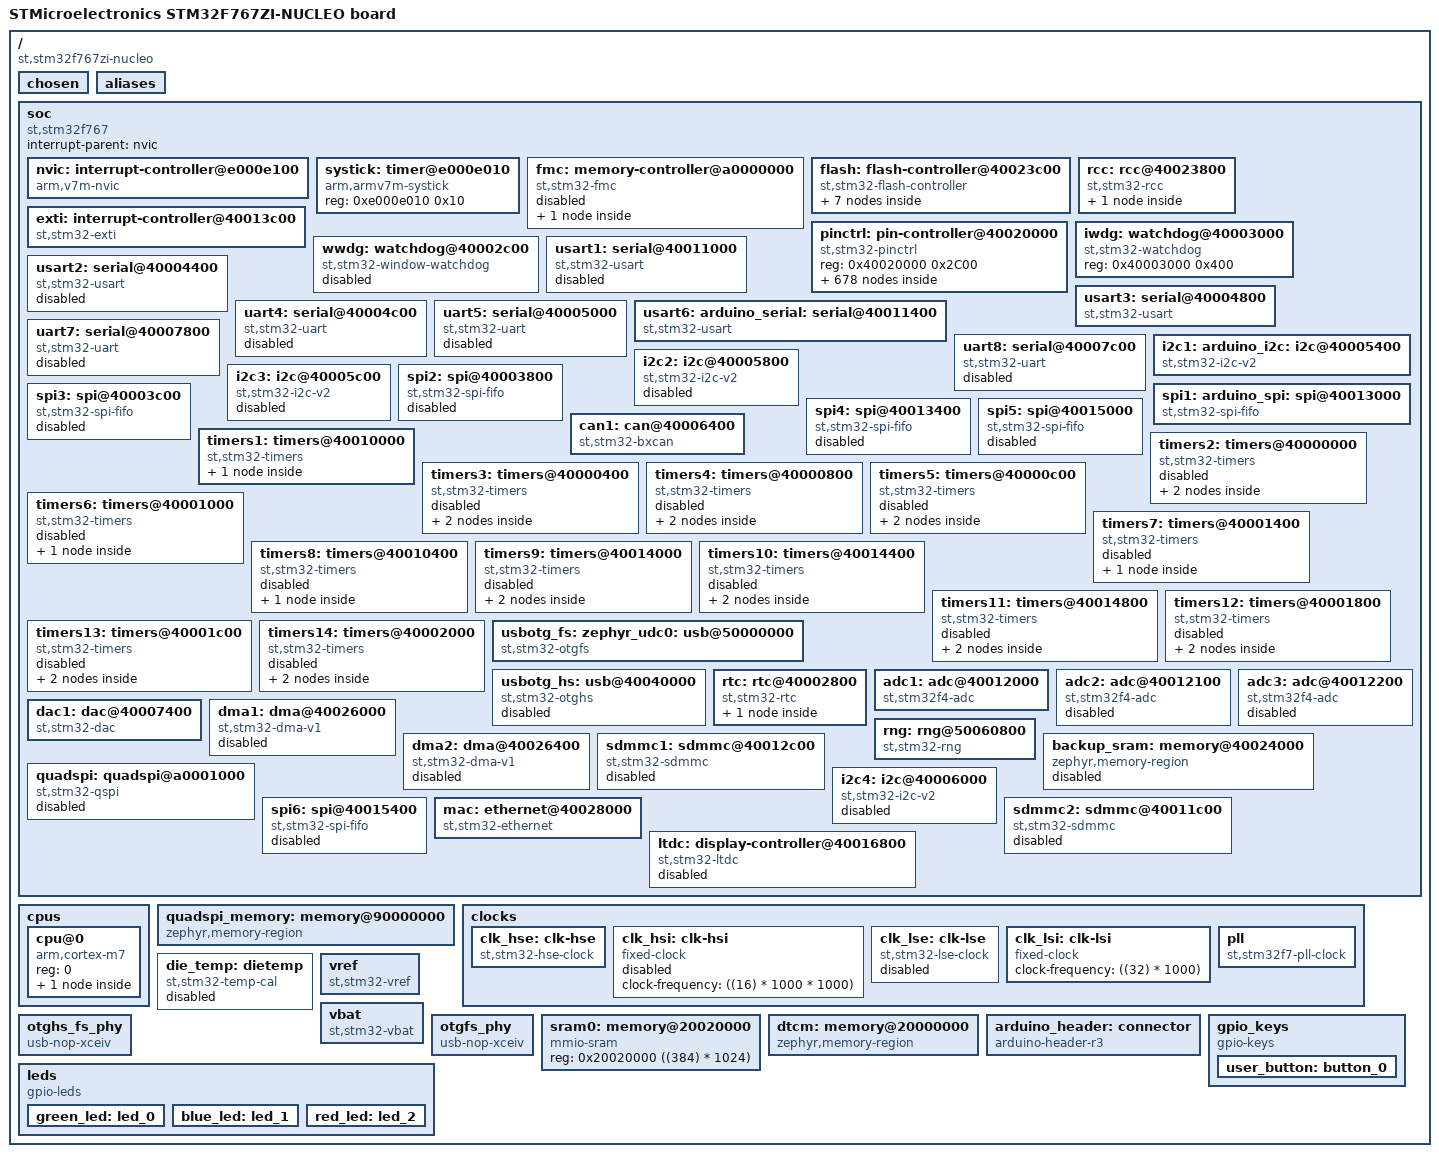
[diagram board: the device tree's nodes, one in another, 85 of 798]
/dts-v1/;
/ {
 #address-cells = <1>;
 #size-cells = <1>;
 chosen { };
 aliases { };
};
/ {
 soc {
  #address-cells = <1>;
  #size-cells = <1>;
  compatible = "simple-bus";
  interrupt-parent = <&nvic>;
  ranges;
  nvic: interrupt-controller@e000e100 {
   #address-cells = <1>;
   compatible = "arm,v7m-nvic";
   reg = <0xe000e100 0xc00>;
   interrupt-controller;
   #interrupt-cells = <2>;
  };
  systick: timer@e000e010 {
   compatible = "arm,armv7m-systick";
   reg = <0xe000e010 0x10>;
  };
 };
};
/ {
 chosen {
  zephyr,entropy = &rng;
  zephyr,flash-controller = &flash;
 };
 cpus {
  #address-cells = <1>;
  #size-cells = <0>;
  cpu@0 {
   device_type = "cpu";
   compatible = "arm,cortex-m7";
   reg = <0>;
   #address-cells = <1>;
   #size-cells = <1>;
   mpu: mpu@e000ed90 {
    compatible = "arm,armv7m-mpu";
    reg = <0xe000ed90 0x40>;
    arm,num-mpu-regions = <8>;
   };
  };
 };
 quadspi_memory: memory@90000000 {
  compatible = "zephyr,memory-region", "mmio-sram";
  reg = <0x90000000 ((256) * 1024 * 1024)>;
  zephyr,memory-region = "QSPI";
  zephyr,memory-attr = <( (((1UL << (5))) << (20)) )>;
 };
 clocks {
  clk_hse: clk-hse {
   #clock-cells = <0>;
   compatible = "st,stm32-hse-clock";
   status = "disabled";
  };
  clk_hsi: clk-hsi {
   #clock-cells = <0>;
   compatible = "fixed-clock";
   clock-frequency = <((16) * 1000 * 1000)>;
   status = "disabled";
  };
  clk_lse: clk-lse {
   #clock-cells = <0>;
   compatible = "st,stm32-lse-clock";
   clock-frequency = <32768>;
   driving-capability = <0>;
   status = "disabled";
  };
  clk_lsi: clk-lsi {
   #clock-cells = <0>;
   compatible = "fixed-clock";
   clock-frequency = <((32) * 1000)>;
   status = "disabled";
  };
  pll: pll {
   #clock-cells = <0>;
   compatible = "st,stm32f7-pll-clock";
   status = "disabled";
  };
 };
 soc {
  fmc: memory-controller@a0000000 {
   compatible = "st,stm32-fmc";
   reg = <0xa0000000 0x400>;
   clocks = <&rcc 0x038 0x00000001>;
   status = "disabled";
   sdram: sdram {
    compatible = "st,stm32-fmc-sdram";
    #address-cells = <1>;
    #size-cells = <0>;
    status = "disabled";
   };
  };
  flash: flash-controller@40023c00 {
   compatible = "st,stm32-flash-controller", "st,stm32f7-flash-controller";
   reg = <0x40023c00 0x400>;
   interrupts = <4 0>;
   #address-cells = <1>;
   #size-cells = <1>;
   flash0: flash@8000000 {
    compatible = "st,stm32-nv-flash", "soc-nv-flash";
    write-block-size = <1>;
    max-erase-time = <4000>;
   };
  };
  rcc: rcc@40023800 {
   compatible = "st,stm32-rcc";
   #clock-cells = <2>;
   reg = <0x40023800 0x400>;
   rctl: reset-controller {
    compatible = "st,stm32-rcc-rctl";
    #reset-cells = <1>;
   };
  };
  exti: interrupt-controller@40013c00 {
   compatible = "st,stm32-exti";
   interrupt-controller;
   #interrupt-cells = <1>;
   #address-cells = <1>;
   reg = <0x40013c00 0x400>;
   num-lines = <16>;
   interrupts = <6 0>, <7 0>, <8 0>, <9 0>,
         <10 0>, <23 0>, <40 0>;
   interrupt-names = "line0", "line1", "line2", "line3",
       "line4", "line5-9", "line10-15";
   line-ranges = <0 1>, <1 1>, <2 1>, <3 1>,
          <4 1>, <5 5>, <10 6>;
  };
  pinctrl: pin-controller@40020000 {
   compatible = "st,stm32-pinctrl";
   #address-cells = <1>;
   #size-cells = <1>;
   reg = <0x40020000 0x2400>;
   gpioa: gpio@40020000 {
    compatible = "st,stm32-gpio";
    gpio-controller;
    #gpio-cells = <2>;
    reg = <0x40020000 0x400>;
    clocks = <&rcc 0x030 0x00000001>;
   };
   gpiob: gpio@40020400 {
    compatible = "st,stm32-gpio";
    gpio-controller;
    #gpio-cells = <2>;
    reg = <0x40020400 0x400>;
    clocks = <&rcc 0x030 0x00000002>;
   };
   gpioc: gpio@40020800 {
    compatible = "st,stm32-gpio";
    gpio-controller;
    #gpio-cells = <2>;
    reg = <0x40020800 0x400>;
    clocks = <&rcc 0x030 0x00000004>;
   };
   gpiod: gpio@40020C00 {
    compatible = "st,stm32-gpio";
    gpio-controller;
    #gpio-cells = <2>;
    reg = <0x40020C00 0x400>;
    clocks = <&rcc 0x030 0x00000008>;
   };
   gpioe: gpio@40021000 {
    compatible = "st,stm32-gpio";
    gpio-controller;
    #gpio-cells = <2>;
    reg = <0x40021000 0x400>;
    clocks = <&rcc 0x030 0x00000010>;
   };
   gpiof: gpio@40021400 {
    compatible = "st,stm32-gpio";
    gpio-controller;
    #gpio-cells = <2>;
    reg = <0x40021400 0x400>;
    clocks = <&rcc 0x030 0x00000020>;
   };
   gpiog: gpio@40021800 {
    compatible = "st,stm32-gpio";
    gpio-controller;
    #gpio-cells = <2>;
    reg = <0x40021800 0x400>;
    clocks = <&rcc 0x030 0x00000040>;
   };
   gpioh: gpio@40021C00 {
    compatible = "st,stm32-gpio";
    gpio-controller;
    #gpio-cells = <2>;
    reg = <0x40021C00 0x400>;
    clocks = <&rcc 0x030 0x00000080>;
   };
   gpioi: gpio@40022000 {
    compatible = "st,stm32-gpio";
    gpio-controller;
    #gpio-cells = <2>;
    reg = <0x40022000 0x400>;
    clocks = <&rcc 0x030 0x00000100>;
   };
  };
  iwdg: watchdog@40003000 {
   compatible = "st,stm32-watchdog";
   reg = <0x40003000 0x400>;
   status = "disabled";
  };
  wwdg: watchdog@40002c00 {
   compatible = "st,stm32-window-watchdog";
   reg = <0x40002C00 0x400>;
   clocks = <&rcc 0x040 0x00000800>;
   interrupts = <0 7>;
   status = "disabled";
  };
  usart1: serial@40011000 {
   compatible = "st,stm32-usart", "st,stm32-uart";
   reg = <0x40011000 0x400>;
   clocks = <&rcc 0x044 0x00000010>;
   resets = <&rctl (((0x24) << 5U) | (4U))>;
   interrupts = <37 0>;
   status = "disabled";
  };
  usart2: serial@40004400 {
   compatible = "st,stm32-usart", "st,stm32-uart";
   reg = <0x40004400 0x400>;
   clocks = <&rcc 0x040 0x00020000>;
   resets = <&rctl (((0x20) << 5U) | (17U))>;
   interrupts = <38 0>;
   status = "disabled";
  };
  usart3: serial@40004800 {
   compatible = "st,stm32-usart", "st,stm32-uart";
   reg = <0x40004800 0x400>;
   clocks = <&rcc 0x040 0x00040000>;
   resets = <&rctl (((0x20) << 5U) | (18U))>;
   interrupts = <39 0>;
   status = "disabled";
  };
  uart4: serial@40004c00 {
   compatible ="st,stm32-uart";
   reg = <0x40004c00 0x400>;
   clocks = <&rcc 0x040 0x00080000>;
   resets = <&rctl (((0x20) << 5U) | (19U))>;
   interrupts = <52 0>;
   status = "disabled";
  };
  uart5: serial@40005000 {
   compatible = "st,stm32-uart";
   reg = <0x40005000 0x400>;
   clocks = <&rcc 0x040 0x00100000>;
   resets = <&rctl (((0x20) << 5U) | (20U))>;
   interrupts = <53 0>;
   status = "disabled";
  };
  usart6: serial@40011400 {
   compatible = "st,stm32-usart", "st,stm32-uart";
   reg = <0x40011400 0x400>;
   clocks = <&rcc 0x044 0x00000020>;
   resets = <&rctl (((0x24) << 5U) | (5U))>;
   interrupts = <71 0>;
   status = "disabled";
  };
  uart7: serial@40007800 {
   compatible = "st,stm32-uart";
   reg = <0x40007800 0x400>;
   clocks = <&rcc 0x040 0x40000000>;
   resets = <&rctl (((0x20) << 5U) | (30U))>;
   interrupts = <82 0>;
   status = "disabled";
  };
  uart8: serial@40007c00 {
   compatible = "st,stm32-uart";
   reg = <0x40007c00 0x400>;
   clocks = <&rcc 0x040 0x80000000>;
   resets = <&rctl (((0x20) << 5U) | (31U))>;
   interrupts = <83 0>;
   status = "disabled";
  };
  i2c1: i2c@40005400 {
   compatible = "st,stm32-i2c-v2";
   clock-frequency = <100000>;
   #address-cells = <1>;
   #size-cells = <0>;
   reg = <0x40005400 0x400>;
   clocks = <&rcc 0x040 0x00200000>;
   interrupts = <31 0>, <32 0>;
   interrupt-names = "event", "error";
   status = "disabled";
  };
  i2c2: i2c@40005800 {
   compatible = "st,stm32-i2c-v2";
   clock-frequency = <100000>;
   #address-cells = <1>;
   #size-cells = <0>;
   reg = <0x40005800 0x400>;
   clocks = <&rcc 0x040 0x00400000>;
   interrupts = <33 0>, <34 0>;
   interrupt-names = "event", "error";
   status = "disabled";
  };
  i2c3: i2c@40005c00 {
   compatible = "st,stm32-i2c-v2";
   clock-frequency = <100000>;
   #address-cells = <1>;
   #size-cells = <0>;
   reg = <0x40005c00 0x400>;
   clocks = <&rcc 0x040 0x00800000>;
   interrupts = <72 0>, <73 0>;
   interrupt-names = "event", "error";
   status = "disabled";
  };
  spi1: spi@40013000 {
   compatible = "st,stm32-spi-fifo", "st,stm32-spi";
   #address-cells = <1>;
   #size-cells = <0>;
   reg = <0x40013000 0x400>;
   clocks = <&rcc 0x044 0x00001000>;
   interrupts = <35 5>;
   status = "disabled";
  };
  spi2: spi@40003800 {
   compatible = "st,stm32-spi-fifo", "st,stm32-spi";
   #address-cells = <1>;
   #size-cells = <0>;
   reg = <0x40003800 0x400>;
   clocks = <&rcc 0x040 0x00004000>;
   interrupts = <36 5>;
   status = "disabled";
  };
  spi3: spi@40003c00 {
   compatible = "st,stm32-spi-fifo", "st,stm32-spi";
   #address-cells = <1>;
   #size-cells = <0>;
   reg = <0x40003c00 0x400>;
   clocks = <&rcc 0x040 0x00008000>;
   interrupts = <51 5>;
   status = "disabled";
  };
  spi4: spi@40013400 {
   compatible = "st,stm32-spi-fifo", "st,stm32-spi";
   #address-cells = <1>;
   #size-cells = <0>;
   reg = <0x40013400 0x400>;
   clocks = <&rcc 0x044 0x00002000>;
   interrupts = <84 5>;
   status = "disabled";
  };
  spi5: spi@40015000 {
   compatible = "st,stm32-spi-fifo", "st,stm32-spi";
   #address-cells = <1>;
   #size-cells = <0>;
   reg = <0x40015000 0x400>;
   clocks = <&rcc 0x044 0x00100000>;
   interrupts = <85 5>;
   status = "disabled";
  };
  can1: can@40006400 {
   compatible = "st,stm32-bxcan";
   reg = <0x40006400 0x400>;
   interrupts = <19 0>, <20 0>, <21 0>, <22 0>;
   interrupt-names = "TX", "RX0", "RX1", "SCE";
   clocks = <&rcc 0x040 0x02000000>;
   status = "disabled";
   sample-point = <875>;
  };
  timers1: timers@40010000 {
   compatible = "st,stm32-timers";
   reg = <0x40010000 0x400>;
   clocks = <&rcc 0x044 0x00000001>;
   resets = <&rctl (((0x24) << 5U) | (0U))>;
   interrupts = <24 0>, <25 0>, <26 0>, <27 0>;
   interrupt-names = "brk", "up", "trgcom", "cc";
   st,prescaler = <0>;
   status = "disabled";
   pwm {
    compatible = "st,stm32-pwm";
    status = "disabled";
    #pwm-cells = <3>;
   };
  };
  timers2: timers@40000000 {
   compatible = "st,stm32-timers";
   reg = <0x40000000 0x400>;
   clocks = <&rcc 0x040 0x00000001>;
   resets = <&rctl (((0x20) << 5U) | (0U))>;
   interrupts = <28 0>;
   interrupt-names = "global";
   st,prescaler = <0>;
   status = "disabled";
   pwm {
    compatible = "st,stm32-pwm";
    status = "disabled";
    #pwm-cells = <3>;
   };
   counter {
    compatible = "st,stm32-counter";
    status = "disabled";
   };
  };
  timers3: timers@40000400 {
   compatible = "st,stm32-timers";
   reg = <0x40000400 0x400>;
   clocks = <&rcc 0x040 0x00000002>;
   resets = <&rctl (((0x20) << 5U) | (1U))>;
   interrupts = <29 0>;
   interrupt-names = "global";
   st,prescaler = <0>;
   status = "disabled";
   pwm {
    compatible = "st,stm32-pwm";
    status = "disabled";
    #pwm-cells = <3>;
   };
   counter {
    compatible = "st,stm32-counter";
    status = "disabled";
   };
  };
  timers4: timers@40000800 {
   compatible = "st,stm32-timers";
   reg = <0x40000800 0x400>;
   clocks = <&rcc 0x040 0x00000004>;
   resets = <&rctl (((0x20) << 5U) | (2U))>;
   interrupts = <30 0>;
   interrupt-names = "global";
   st,prescaler = <0>;
   status = "disabled";
   pwm {
    compatible = "st,stm32-pwm";
    status = "disabled";
    #pwm-cells = <3>;
   };
   counter {
    compatible = "st,stm32-counter";
    status = "disabled";
   };
  };
  timers5: timers@40000c00 {
   compatible = "st,stm32-timers";
   reg = <0x40000c00 0x400>;
   clocks = <&rcc 0x040 0x00000008>;
   resets = <&rctl (((0x20) << 5U) | (3U))>;
   interrupts = <50 0>;
   interrupt-names = "global";
   st,prescaler = <0>;
   status = "disabled";
   pwm {
    compatible = "st,stm32-pwm";
    status = "disabled";
    #pwm-cells = <3>;
   };
   counter {
    compatible = "st,stm32-counter";
    status = "disabled";
   };
  };
  timers6: timers@40001000 {
   compatible = "st,stm32-timers";
   reg = <0x40001000 0x400>;
   clocks = <&rcc 0x040 0x00000010>;
   resets = <&rctl (((0x20) << 5U) | (4U))>;
   interrupts = <54 0>;
   interrupt-names = "global";
   st,prescaler = <0>;
   status = "disabled";
   counter {
    compatible = "st,stm32-counter";
    status = "disabled";
   };
  };
  timers7: timers@40001400 {
   compatible = "st,stm32-timers";
   reg = <0x40001400 0x400>;
   clocks = <&rcc 0x040 0x00000020>;
   resets = <&rctl (((0x20) << 5U) | (5U))>;
   interrupts = <55 0>;
   interrupt-names = "global";
   st,prescaler = <0>;
   status = "disabled";
   counter {
    compatible = "st,stm32-counter";
    status = "disabled";
   };
  };
  timers8: timers@40010400 {
   compatible = "st,stm32-timers";
   reg = <0x40010400 0x400>;
   clocks = <&rcc 0x044 0x00000002>;
   resets = <&rctl (((0x24) << 5U) | (1U))>;
   interrupts = <43 0>, <44 0>, <45 0>, <46 0>;
   interrupt-names = "brk", "up", "trgcom", "cc";
   st,prescaler = <0>;
   status = "disabled";
   pwm {
    compatible = "st,stm32-pwm";
    status = "disabled";
    #pwm-cells = <3>;
   };
  };
  timers9: timers@40014000 {
   compatible = "st,stm32-timers";
   reg = <0x40014000 0x400>;
   clocks = <&rcc 0x044 0x00010000>;
   resets = <&rctl (((0x24) << 5U) | (16U))>;
   interrupts = <24 0>;
   interrupt-names = "global";
   st,prescaler = <0>;
   status = "disabled";
   pwm {
    compatible = "st,stm32-pwm";
    status = "disabled";
    #pwm-cells = <3>;
   };
   counter {
    compatible = "st,stm32-counter";
    status = "disabled";
   };
  };
  timers10: timers@40014400 {
   compatible = "st,stm32-timers";
   reg = <0x40014400 0x400>;
   clocks = <&rcc 0x044 0x00020000>;
   resets = <&rctl (((0x24) << 5U) | (17U))>;
   interrupts = <25 0>;
   interrupt-names = "global";
   st,prescaler = <0>;
   status = "disabled";
   pwm {
    compatible = "st,stm32-pwm";
    status = "disabled";
    #pwm-cells = <3>;
   };
   counter {
    compatible = "st,stm32-counter";
    status = "disabled";
   };
  };
  timers11: timers@40014800 {
   compatible = "st,stm32-timers";
   reg = <0x40014800 0x400>;
   clocks = <&rcc 0x044 0x00040000>;
   resets = <&rctl (((0x24) << 5U) | (18U))>;
   interrupts = <26 0>;
   interrupt-names = "global";
   st,prescaler = <0>;
   status = "disabled";
   pwm {
    compatible = "st,stm32-pwm";
    status = "disabled";
    #pwm-cells = <3>;
   };
   counter {
    compatible = "st,stm32-counter";
    status = "disabled";
   };
  };
  timers12: timers@40001800 {
   compatible = "st,stm32-timers";
   reg = <0x40001800 0x400>;
   clocks = <&rcc 0x040 0x00000040>;
   resets = <&rctl (((0x20) << 5U) | (6U))>;
   interrupts = <43 0>;
   interrupt-names = "global";
   st,prescaler = <0>;
   status = "disabled";
   pwm {
    compatible = "st,stm32-pwm";
    status = "disabled";
    #pwm-cells = <3>;
   };
   counter {
    compatible = "st,stm32-counter";
    status = "disabled";
   };
  };
  timers13: timers@40001c00 {
   compatible = "st,stm32-timers";
   reg = <0x40001c00 0x400>;
   clocks = <&rcc 0x040 0x00000080>;
   resets = <&rctl (((0x20) << 5U) | (7U))>;
   interrupts = <44 0>;
   interrupt-names = "global";
   st,prescaler = <0>;
   status = "disabled";
   pwm {
    compatible = "st,stm32-pwm";
    status = "disabled";
    #pwm-cells = <3>;
   };
   counter {
    compatible = "st,stm32-counter";
    status = "disabled";
   };
  };
  timers14: timers@40002000 {
   compatible = "st,stm32-timers";
   reg = <0x40002000 0x400>;
   clocks = <&rcc 0x040 0x00000100>;
   resets = <&rctl (((0x20) << 5U) | (8U))>;
   interrupts = <45 0>;
   interrupt-names = "global";
   st,prescaler = <0>;
   status = "disabled";
   pwm {
    compatible = "st,stm32-pwm";
    status = "disabled";
    #pwm-cells = <3>;
   };
   counter {
    compatible = "st,stm32-counter";
    status = "disabled";
   };
  };
  usbotg_fs: usb@50000000 {
   compatible = "st,stm32-otgfs";
   reg = <0x50000000 0x40000>;
   interrupts = <67 0>;
   interrupt-names = "otgfs";
   num-bidir-endpoints = <6>;
   ram-size = <1280>;
   maximum-speed = "full-speed";
   phys = <&otgfs_phy>;
   clocks = <&rcc 0x034 0x00000080>,
     <&rcc 0x002 ((((0x90) & 0xFFU) << 0U) | (((27) & 0x1FU) << 8U) | (((1) & 0x7U) << 13U) | (((0) & 0x7U) << 16U))>;
   status = "disabled";
  };
  usbotg_hs: usb@40040000 {
   compatible = "st,stm32-otghs";
   reg = <0x40040000 0x40000>;
   interrupts = <77 0>, <74 0>, <75 0>;
   interrupt-names = "otghs", "ep1_out", "ep1_in";
   num-bidir-endpoints = <9>;
   ram-size = <4096>;
   maximum-speed = "full-speed";
   clocks = <&rcc 0x030 0x20000000>;
   phys = <&otghs_fs_phy>;
   status = "disabled";
  };
  rtc: rtc@40002800 {
   compatible = "st,stm32-rtc";
   reg = <0x40002800 0x300>;
   interrupts = <41 0>;
   clocks = <&rcc 0x040 0x10000000>;
   prescaler = <32768>;
   status = "disabled";
   bbram: backup_regs {
    compatible = "st,stm32-bbram";
    st,backup-regs = <32>;
    status = "disabled";
   };
  };
  adc1: adc@40012000 {
   compatible = "st,stm32f4-adc", "st,stm32-adc";
   reg = <0x40012000 0x50>;
   clocks = <&rcc 0x044 0x00000100>;
   interrupts = <18 0>;
   status = "disabled";
   #io-channel-cells = <1>;
   resolutions = <((((0x04) & ((1UL << (8)) - 1UL)) << 0U) | (((24) & ((1UL << (5)) - 1UL)) << 8U) | (((((1UL << (2)) - 1UL)) & ((1UL << (3)) - 1UL)) << 13U) | (((0x00) & ((1UL << (3)) - 1UL)) << 16U) | (((12) & ((1UL << (13)) - 1UL)) << 19U))
           ((((0x04) & ((1UL << (8)) - 1UL)) << 0U) | (((24) & ((1UL << (5)) - 1UL)) << 8U) | (((((1UL << (2)) - 1UL)) & ((1UL << (3)) - 1UL)) << 13U) | (((0x01) & ((1UL << (3)) - 1UL)) << 16U) | (((10) & ((1UL << (13)) - 1UL)) << 19U))
           ((((0x04) & ((1UL << (8)) - 1UL)) << 0U) | (((24) & ((1UL << (5)) - 1UL)) << 8U) | (((((1UL << (2)) - 1UL)) & ((1UL << (3)) - 1UL)) << 13U) | (((0x02) & ((1UL << (3)) - 1UL)) << 16U) | (((8) & ((1UL << (13)) - 1UL)) << 19U))
           ((((0x04) & ((1UL << (8)) - 1UL)) << 0U) | (((24) & ((1UL << (5)) - 1UL)) << 8U) | (((((1UL << (2)) - 1UL)) & ((1UL << (3)) - 1UL)) << 13U) | (((0x03) & ((1UL << (3)) - 1UL)) << 16U) | (((6) & ((1UL << (13)) - 1UL)) << 19U))>;
   sampling-times = <3 15 28 56 84 112 144 480>;
   st,adc-clock-source = <1>;
   st,adc-sequencer = <1>;
  };
  adc2: adc@40012100 {
   compatible = "st,stm32f4-adc", "st,stm32-adc";
   reg = <0x40012100 0x50>;
   clocks = <&rcc 0x044 0x00000200>;
   interrupts = <18 0>;
   status = "disabled";
   #io-channel-cells = <1>;
   resolutions = <((((0x04) & ((1UL << (8)) - 1UL)) << 0U) | (((24) & ((1UL << (5)) - 1UL)) << 8U) | (((((1UL << (2)) - 1UL)) & ((1UL << (3)) - 1UL)) << 13U) | (((0x00) & ((1UL << (3)) - 1UL)) << 16U) | (((12) & ((1UL << (13)) - 1UL)) << 19U))
           ((((0x04) & ((1UL << (8)) - 1UL)) << 0U) | (((24) & ((1UL << (5)) - 1UL)) << 8U) | (((((1UL << (2)) - 1UL)) & ((1UL << (3)) - 1UL)) << 13U) | (((0x01) & ((1UL << (3)) - 1UL)) << 16U) | (((10) & ((1UL << (13)) - 1UL)) << 19U))
           ((((0x04) & ((1UL << (8)) - 1UL)) << 0U) | (((24) & ((1UL << (5)) - 1UL)) << 8U) | (((((1UL << (2)) - 1UL)) & ((1UL << (3)) - 1UL)) << 13U) | (((0x02) & ((1UL << (3)) - 1UL)) << 16U) | (((8) & ((1UL << (13)) - 1UL)) << 19U))
           ((((0x04) & ((1UL << (8)) - 1UL)) << 0U) | (((24) & ((1UL << (5)) - 1UL)) << 8U) | (((((1UL << (2)) - 1UL)) & ((1UL << (3)) - 1UL)) << 13U) | (((0x03) & ((1UL << (3)) - 1UL)) << 16U) | (((6) & ((1UL << (13)) - 1UL)) << 19U))>;
   sampling-times = <3 15 28 56 84 112 144 480>;
   st,adc-clock-source = <1>;
   st,adc-sequencer = <1>;
  };
  adc3: adc@40012200 {
   compatible = "st,stm32f4-adc", "st,stm32-adc";
   reg = <0x40012200 0x50>;
   clocks = <&rcc 0x044 0x00000400>;
   interrupts = <18 0>;
   status = "disabled";
   #io-channel-cells = <1>;
   resolutions = <((((0x04) & ((1UL << (8)) - 1UL)) << 0U) | (((24) & ((1UL << (5)) - 1UL)) << 8U) | (((((1UL << (2)) - 1UL)) & ((1UL << (3)) - 1UL)) << 13U) | (((0x00) & ((1UL << (3)) - 1UL)) << 16U) | (((12) & ((1UL << (13)) - 1UL)) << 19U))
           ((((0x04) & ((1UL << (8)) - 1UL)) << 0U) | (((24) & ((1UL << (5)) - 1UL)) << 8U) | (((((1UL << (2)) - 1UL)) & ((1UL << (3)) - 1UL)) << 13U) | (((0x01) & ((1UL << (3)) - 1UL)) << 16U) | (((10) & ((1UL << (13)) - 1UL)) << 19U))
           ((((0x04) & ((1UL << (8)) - 1UL)) << 0U) | (((24) & ((1UL << (5)) - 1UL)) << 8U) | (((((1UL << (2)) - 1UL)) & ((1UL << (3)) - 1UL)) << 13U) | (((0x02) & ((1UL << (3)) - 1UL)) << 16U) | (((8) & ((1UL << (13)) - 1UL)) << 19U))
           ((((0x04) & ((1UL << (8)) - 1UL)) << 0U) | (((24) & ((1UL << (5)) - 1UL)) << 8U) | (((((1UL << (2)) - 1UL)) & ((1UL << (3)) - 1UL)) << 13U) | (((0x03) & ((1UL << (3)) - 1UL)) << 16U) | (((6) & ((1UL << (13)) - 1UL)) << 19U))>;
   sampling-times = <3 15 28 56 84 112 144 480>;
   st,adc-clock-source = <1>;
   st,adc-sequencer = <1>;
  };
  dac1: dac@40007400 {
   compatible = "st,stm32-dac";
   reg = <0x40007400 0x400>;
   clocks = <&rcc 0x040 0x20000000>;
   status = "disabled";
   #io-channel-cells = <1>;
  };
  dma1: dma@40026000 {
   compatible = "st,stm32-dma-v1";
   #dma-cells = <4>;
   reg = <0x40026000 0x400>;
   interrupts = <11 0 12 0 13 0 14 0 15 0 16 0 17 0 47 0>;
   clocks = <&rcc 0x030 0x200000>;
   status = "disabled";
  };
  dma2: dma@40026400 {
   compatible = "st,stm32-dma-v1";
   #dma-cells = <4>;
   reg = <0x40026400 0x400>;
   interrupts = <56 0 57 0 58 0 59 0 60 0 68 0 69 0 70 0>;
   clocks = <&rcc 0x030 0x400000>;
   st,mem2mem;
   status = "disabled";
  };
  rng: rng@50060800 {
   compatible = "st,stm32-rng";
   reg = <0x50060800 0x400>;
   interrupts = <80 0>;
   clocks = <&rcc 0x034 0x00000040>,
     <&rcc 0x002 ((((0x90) & 0xFFU) << 0U) | (((27) & 0x1FU) << 8U) | (((1) & 0x7U) << 13U) | (((0) & 0x7U) << 16U))>;
   status = "disabled";
  };
  sdmmc1: sdmmc@40012c00 {
   compatible = "st,stm32-sdmmc";
   reg = <0x40012c00 0x400>;
   clocks = <&rcc 0x044 0x00000800>,
     <&rcc 0x002 ((((0x90) & 0xFFU) << 0U) | (((28) & 0x1FU) << 8U) | (((1) & 0x7U) << 13U) | (((0) & 0x7U) << 16U))>;
   resets = <&rctl (((0x24) << 5U) | (11U))>;
   interrupts = <49 0>;
   status = "disabled";
  };
  backup_sram: memory@40024000 {
   compatible = "zephyr,memory-region", "st,stm32-backup-sram";
   reg = <0x40024000 ((4) * 1024)>;
   clocks = <&rcc 0x030 0x00040000>;
   zephyr,memory-region = "BACKUP_SRAM";
   status = "disabled";
  };
  quadspi: quadspi@a0001000 {
   compatible = "st,stm32-qspi";
   #address-cells = <0x1>;
   #size-cells = <0x0>;
   reg = <0xa0001000 0x34>;
   interrupts = <92 0>;
   clocks = <&rcc 0x038 0x2>;
   status = "disabled";
  };
 };
 die_temp: dietemp {
  compatible = "st,stm32-temp-cal";
  ts-cal1-addr = <0x1FF0F44C>;
  ts-cal2-addr = <0x1FF0F44E>;
  ts-cal1-temp = <30>;
  ts-cal2-temp = <110>;
  ts-cal-vrefanalog = <3300>;
  io-channels = <&adc1 18>;
  status = "disabled";
 };
 vref: vref {
  compatible = "st,stm32-vref";
  vrefint-cal-addr = <0x1FFF7A2A>;
  vrefint-cal-mv = <3300>;
  io-channels = <&adc1 17>;
  status = "disabled";
 };
 vbat: vbat {
  compatible = "st,stm32-vbat";
  ratio = <4>;
  io-channels = <&adc1 18>;
  status = "disabled";
 };
 otghs_fs_phy: otghs_fs_phy {
  compatible = "usb-nop-xceiv";
  #phy-cells = <0>;
 };
 otgfs_phy: otgfs_phy {
  compatible = "usb-nop-xceiv";
  #phy-cells = <0>;
 };
};
&nvic {
 arm,num-irq-priority-bits = <4>;
};
/ {
 sram0: memory@20020000 {
  compatible = "mmio-sram";
  reg = <0x20020000 ((384) * 1024)>;
 };
 dtcm: memory@20000000 {
  compatible = "zephyr,memory-region", "arm,dtcm";
  reg = <0x20000000 ((128) * 1024)>;
  zephyr,memory-region = "DTCM";
 };
 soc {
  compatible = "st,stm32f765", "st,stm32f7", "simple-bus";
  pinctrl: pin-controller@40020000 {
   reg = <0x40020000 0x2C00>;
   gpioj: gpio@40022400 {
    compatible = "st,stm32-gpio";
    gpio-controller;
    #gpio-cells = <2>;
    reg = <0x40022400 0x400>;
    clocks = <&rcc 0x030 0x00000200>;
   };
   gpiok: gpio@40022800 {
    compatible = "st,stm32-gpio";
    gpio-controller;
    #gpio-cells = <2>;
    reg = <0x40022800 0x400>;
    clocks = <&rcc 0x030 0x00000400>;
   };
  };
  i2c4: i2c@40006000 {
   compatible = "st,stm32-i2c-v2";
   clock-frequency = <100000>;
   #address-cells = <1>;
   #size-cells = <0>;
   reg = <0x40006000 0x400>;
   clocks = <&rcc 0x040 0x01000000>;
   interrupts = <95 0>, <96 0>;
   interrupt-names = "event", "error";
   status = "disabled";
  };
  spi6: spi@40015400 {
   compatible = "st,stm32-spi-fifo", "st,stm32-spi";
   #address-cells = <1>;
   #size-cells = <0>;
   reg = <0x40015400 0x400>;
   clocks = <&rcc 0x044 0x00200000>;
   interrupts = <86 5>;
   status = "disabled";
  };
  mac: ethernet@40028000 {
   compatible = "st,stm32-ethernet";
   reg = <0x40028000 0x8000>;
   interrupts = <61 0>;
   clock-names = "stmmaceth", "mac-clk-tx",
          "mac-clk-rx", "mac-clk-ptp";
   clocks = <&rcc 0x030 0x02000000>,
     <&rcc 0x030 0x04000000>,
     <&rcc 0x030 0x08000000>,
     <&rcc 0x030 0x10000000>;
   status = "disabled";
  };
  sdmmc2: sdmmc@40011c00 {
   compatible = "st,stm32-sdmmc";
   reg = <0x40011c00 0x400>;
   clocks = <&rcc 0x044 0x00000080>,
     <&rcc 0x002 ((((0x90) & 0xFFU) << 0U) | (((29) & 0x1FU) << 8U) | (((1) & 0x7U) << 13U) | (((0) & 0x7U) << 16U))>;
   resets = <&rctl (((0x24) << 5U) | (7U))>;
   interrupts = <103 0>;
   status = "disabled";
  };
 };
};
/ {
 soc {
  compatible = "st,stm32f767", "st,stm32f7", "simple-bus";
  ltdc: display-controller@40016800 {
   compatible = "st,stm32-ltdc";
   reg = <0x40016800 0x200>;
   interrupts = <88 0>, <89 0>;
   interrupt-names = "ltdc", "ltdc_err";
   clocks = <&rcc 0x044 0x04000000>;
   status = "disabled";
  };
 };
};
/ {
 soc {
  flash-controller@40023c00 {
   flash0: flash@8000000 {
    reg = <0x08000000 ((2048) * 1024)>;
   };
  };
 };
};
/ {
 soc {
  pinctrl: pin-controller@40020000 {
   /omit-if-no-ref/ adc1_in0_pa0: adc1_in0_pa0 {
    pinmux = <((((('A') - 'A') & 0xFU) << 9U) | (((0) & 0xFU) << 5U) | (((0x10) & 0x1FU) << 0U))>;
   };
   /omit-if-no-ref/ adc1_in1_pa1: adc1_in1_pa1 {
    pinmux = <((((('A') - 'A') & 0xFU) << 9U) | (((1) & 0xFU) << 5U) | (((0x10) & 0x1FU) << 0U))>;
   };
   /omit-if-no-ref/ adc1_in2_pa2: adc1_in2_pa2 {
    pinmux = <((((('A') - 'A') & 0xFU) << 9U) | (((2) & 0xFU) << 5U) | (((0x10) & 0x1FU) << 0U))>;
   };
   /omit-if-no-ref/ adc1_in3_pa3: adc1_in3_pa3 {
    pinmux = <((((('A') - 'A') & 0xFU) << 9U) | (((3) & 0xFU) << 5U) | (((0x10) & 0x1FU) << 0U))>;
   };
   /omit-if-no-ref/ adc1_in4_pa4: adc1_in4_pa4 {
    pinmux = <((((('A') - 'A') & 0xFU) << 9U) | (((4) & 0xFU) << 5U) | (((0x10) & 0x1FU) << 0U))>;
   };
   /omit-if-no-ref/ adc1_in5_pa5: adc1_in5_pa5 {
    pinmux = <((((('A') - 'A') & 0xFU) << 9U) | (((5) & 0xFU) << 5U) | (((0x10) & 0x1FU) << 0U))>;
   };
   /omit-if-no-ref/ adc1_in6_pa6: adc1_in6_pa6 {
    pinmux = <((((('A') - 'A') & 0xFU) << 9U) | (((6) & 0xFU) << 5U) | (((0x10) & 0x1FU) << 0U))>;
   };
   /omit-if-no-ref/ adc1_in7_pa7: adc1_in7_pa7 {
    pinmux = <((((('A') - 'A') & 0xFU) << 9U) | (((7) & 0xFU) << 5U) | (((0x10) & 0x1FU) << 0U))>;
   };
   /omit-if-no-ref/ adc1_in8_pb0: adc1_in8_pb0 {
    pinmux = <((((('B') - 'A') & 0xFU) << 9U) | (((0) & 0xFU) << 5U) | (((0x10) & 0x1FU) << 0U))>;
   };
   /omit-if-no-ref/ adc1_in9_pb1: adc1_in9_pb1 {
    pinmux = <((((('B') - 'A') & 0xFU) << 9U) | (((1) & 0xFU) << 5U) | (((0x10) & 0x1FU) << 0U))>;
   };
   /omit-if-no-ref/ adc1_in10_pc0: adc1_in10_pc0 {
    pinmux = <((((('C') - 'A') & 0xFU) << 9U) | (((0) & 0xFU) << 5U) | (((0x10) & 0x1FU) << 0U))>;
   };
   /omit-if-no-ref/ adc1_in11_pc1: adc1_in11_pc1 {
    pinmux = <((((('C') - 'A') & 0xFU) << 9U) | (((1) & 0xFU) << 5U) | (((0x10) & 0x1FU) << 0U))>;
   };
   /omit-if-no-ref/ adc1_in12_pc2: adc1_in12_pc2 {
    pinmux = <((((('C') - 'A') & 0xFU) << 9U) | (((2) & 0xFU) << 5U) | (((0x10) & 0x1FU) << 0U))>;
   };
   /omit-if-no-ref/ adc1_in13_pc3: adc1_in13_pc3 {
    pinmux = <((((('C') - 'A') & 0xFU) << 9U) | (((3) & 0xFU) << 5U) | (((0x10) & 0x1FU) << 0U))>;
   };
   /omit-if-no-ref/ adc1_in14_pc4: adc1_in14_pc4 {
    pinmux = <((((('C') - 'A') & 0xFU) << 9U) | (((4) & 0xFU) << 5U) | (((0x10) & 0x1FU) << 0U))>;
   };
   /omit-if-no-ref/ adc1_in15_pc5: adc1_in15_pc5 {
    pinmux = <((((('C') - 'A') & 0xFU) << 9U) | (((5) & 0xFU) << 5U) | (((0x10) & 0x1FU) << 0U))>;
   };
   /omit-if-no-ref/ adc2_in0_pa0: adc2_in0_pa0 {
    pinmux = <((((('A') - 'A') & 0xFU) << 9U) | (((0) & 0xFU) << 5U) | (((0x10) & 0x1FU) << 0U))>;
   };
   /omit-if-no-ref/ adc2_in1_pa1: adc2_in1_pa1 {
    pinmux = <((((('A') - 'A') & 0xFU) << 9U) | (((1) & 0xFU) << 5U) | (((0x10) & 0x1FU) << 0U))>;
   };
   /omit-if-no-ref/ adc2_in2_pa2: adc2_in2_pa2 {
    pinmux = <((((('A') - 'A') & 0xFU) << 9U) | (((2) & 0xFU) << 5U) | (((0x10) & 0x1FU) << 0U))>;
   };
   /omit-if-no-ref/ adc2_in3_pa3: adc2_in3_pa3 {
    pinmux = <((((('A') - 'A') & 0xFU) << 9U) | (((3) & 0xFU) << 5U) | (((0x10) & 0x1FU) << 0U))>;
   };
   /omit-if-no-ref/ adc2_in4_pa4: adc2_in4_pa4 {
    pinmux = <((((('A') - 'A') & 0xFU) << 9U) | (((4) & 0xFU) << 5U) | (((0x10) & 0x1FU) << 0U))>;
   };
   /omit-if-no-ref/ adc2_in5_pa5: adc2_in5_pa5 {
    pinmux = <((((('A') - 'A') & 0xFU) << 9U) | (((5) & 0xFU) << 5U) | (((0x10) & 0x1FU) << 0U))>;
   };
   /omit-if-no-ref/ adc2_in6_pa6: adc2_in6_pa6 {
    pinmux = <((((('A') - 'A') & 0xFU) << 9U) | (((6) & 0xFU) << 5U) | (((0x10) & 0x1FU) << 0U))>;
   };
   /omit-if-no-ref/ adc2_in7_pa7: adc2_in7_pa7 {
    pinmux = <((((('A') - 'A') & 0xFU) << 9U) | (((7) & 0xFU) << 5U) | (((0x10) & 0x1FU) << 0U))>;
   };
   /omit-if-no-ref/ adc2_in8_pb0: adc2_in8_pb0 {
    pinmux = <((((('B') - 'A') & 0xFU) << 9U) | (((0) & 0xFU) << 5U) | (((0x10) & 0x1FU) << 0U))>;
   };
   /omit-if-no-ref/ adc2_in9_pb1: adc2_in9_pb1 {
    pinmux = <((((('B') - 'A') & 0xFU) << 9U) | (((1) & 0xFU) << 5U) | (((0x10) & 0x1FU) << 0U))>;
   };
   /omit-if-no-ref/ adc2_in10_pc0: adc2_in10_pc0 {
    pinmux = <((((('C') - 'A') & 0xFU) << 9U) | (((0) & 0xFU) << 5U) | (((0x10) & 0x1FU) << 0U))>;
   };
   /omit-if-no-ref/ adc2_in11_pc1: adc2_in11_pc1 {
    pinmux = <((((('C') - 'A') & 0xFU) << 9U) | (((1) & 0xFU) << 5U) | (((0x10) & 0x1FU) << 0U))>;
   };
   /omit-if-no-ref/ adc2_in12_pc2: adc2_in12_pc2 {
    pinmux = <((((('C') - 'A') & 0xFU) << 9U) | (((2) & 0xFU) << 5U) | (((0x10) & 0x1FU) << 0U))>;
   };
   /omit-if-no-ref/ adc2_in13_pc3: adc2_in13_pc3 {
    pinmux = <((((('C') - 'A') & 0xFU) << 9U) | (((3) & 0xFU) << 5U) | (((0x10) & 0x1FU) << 0U))>;
   };
   /omit-if-no-ref/ adc2_in14_pc4: adc2_in14_pc4 {
    pinmux = <((((('C') - 'A') & 0xFU) << 9U) | (((4) & 0xFU) << 5U) | (((0x10) & 0x1FU) << 0U))>;
   };
   /omit-if-no-ref/ adc2_in15_pc5: adc2_in15_pc5 {
    pinmux = <((((('C') - 'A') & 0xFU) << 9U) | (((5) & 0xFU) << 5U) | (((0x10) & 0x1FU) << 0U))>;
   };
   /omit-if-no-ref/ adc3_in0_pa0: adc3_in0_pa0 {
    pinmux = <((((('A') - 'A') & 0xFU) << 9U) | (((0) & 0xFU) << 5U) | (((0x10) & 0x1FU) << 0U))>;
   };
   /omit-if-no-ref/ adc3_in1_pa1: adc3_in1_pa1 {
    pinmux = <((((('A') - 'A') & 0xFU) << 9U) | (((1) & 0xFU) << 5U) | (((0x10) & 0x1FU) << 0U))>;
   };
   /omit-if-no-ref/ adc3_in2_pa2: adc3_in2_pa2 {
    pinmux = <((((('A') - 'A') & 0xFU) << 9U) | (((2) & 0xFU) << 5U) | (((0x10) & 0x1FU) << 0U))>;
   };
   /omit-if-no-ref/ adc3_in3_pa3: adc3_in3_pa3 {
    pinmux = <((((('A') - 'A') & 0xFU) << 9U) | (((3) & 0xFU) << 5U) | (((0x10) & 0x1FU) << 0U))>;
   };
   /omit-if-no-ref/ adc3_in10_pc0: adc3_in10_pc0 {
    pinmux = <((((('C') - 'A') & 0xFU) << 9U) | (((0) & 0xFU) << 5U) | (((0x10) & 0x1FU) << 0U))>;
   };
   /omit-if-no-ref/ adc3_in11_pc1: adc3_in11_pc1 {
    pinmux = <((((('C') - 'A') & 0xFU) << 9U) | (((1) & 0xFU) << 5U) | (((0x10) & 0x1FU) << 0U))>;
   };
   /omit-if-no-ref/ adc3_in12_pc2: adc3_in12_pc2 {
    pinmux = <((((('C') - 'A') & 0xFU) << 9U) | (((2) & 0xFU) << 5U) | (((0x10) & 0x1FU) << 0U))>;
   };
   /omit-if-no-ref/ adc3_in13_pc3: adc3_in13_pc3 {
    pinmux = <((((('C') - 'A') & 0xFU) << 9U) | (((3) & 0xFU) << 5U) | (((0x10) & 0x1FU) << 0U))>;
   };
   /omit-if-no-ref/ adc3_in9_pf3: adc3_in9_pf3 {
    pinmux = <((((('F') - 'A') & 0xFU) << 9U) | (((3) & 0xFU) << 5U) | (((0x10) & 0x1FU) << 0U))>;
   };
   /omit-if-no-ref/ adc3_in14_pf4: adc3_in14_pf4 {
    pinmux = <((((('F') - 'A') & 0xFU) << 9U) | (((4) & 0xFU) << 5U) | (((0x10) & 0x1FU) << 0U))>;
   };
   /omit-if-no-ref/ adc3_in15_pf5: adc3_in15_pf5 {
    pinmux = <((((('F') - 'A') & 0xFU) << 9U) | (((5) & 0xFU) << 5U) | (((0x10) & 0x1FU) << 0U))>;
   };
   /omit-if-no-ref/ adc3_in4_pf6: adc3_in4_pf6 {
    pinmux = <((((('F') - 'A') & 0xFU) << 9U) | (((6) & 0xFU) << 5U) | (((0x10) & 0x1FU) << 0U))>;
   };
   /omit-if-no-ref/ adc3_in5_pf7: adc3_in5_pf7 {
    pinmux = <((((('F') - 'A') & 0xFU) << 9U) | (((7) & 0xFU) << 5U) | (((0x10) & 0x1FU) << 0U))>;
   };
   /omit-if-no-ref/ adc3_in6_pf8: adc3_in6_pf8 {
    pinmux = <((((('F') - 'A') & 0xFU) << 9U) | (((8) & 0xFU) << 5U) | (((0x10) & 0x1FU) << 0U))>;
   };
   /omit-if-no-ref/ adc3_in7_pf9: adc3_in7_pf9 {
    pinmux = <((((('F') - 'A') & 0xFU) << 9U) | (((9) & 0xFU) << 5U) | (((0x10) & 0x1FU) << 0U))>;
   };
   /omit-if-no-ref/ adc3_in8_pf10: adc3_in8_pf10 {
    pinmux = <((((('F') - 'A') & 0xFU) << 9U) | (((10) & 0xFU) << 5U) | (((0x10) & 0x1FU) << 0U))>;
   };
   /omit-if-no-ref/ analog_pa0: analog_pa0 {
    pinmux = <((((('A') - 'A') & 0xFU) << 9U) | (((0) & 0xFU) << 5U) | (((0x10) & 0x1FU) << 0U))>;
   };
   /omit-if-no-ref/ analog_pa1: analog_pa1 {
    pinmux = <((((('A') - 'A') & 0xFU) << 9U) | (((1) & 0xFU) << 5U) | (((0x10) & 0x1FU) << 0U))>;
   };
   /omit-if-no-ref/ analog_pa2: analog_pa2 {
    pinmux = <((((('A') - 'A') & 0xFU) << 9U) | (((2) & 0xFU) << 5U) | (((0x10) & 0x1FU) << 0U))>;
   };
   /omit-if-no-ref/ analog_pa3: analog_pa3 {
    pinmux = <((((('A') - 'A') & 0xFU) << 9U) | (((3) & 0xFU) << 5U) | (((0x10) & 0x1FU) << 0U))>;
   };
   /omit-if-no-ref/ analog_pa4: analog_pa4 {
    pinmux = <((((('A') - 'A') & 0xFU) << 9U) | (((4) & 0xFU) << 5U) | (((0x10) & 0x1FU) << 0U))>;
   };
   /omit-if-no-ref/ analog_pa5: analog_pa5 {
    pinmux = <((((('A') - 'A') & 0xFU) << 9U) | (((5) & 0xFU) << 5U) | (((0x10) & 0x1FU) << 0U))>;
   };
   /omit-if-no-ref/ analog_pa6: analog_pa6 {
    pinmux = <((((('A') - 'A') & 0xFU) << 9U) | (((6) & 0xFU) << 5U) | (((0x10) & 0x1FU) << 0U))>;
   };
   /omit-if-no-ref/ analog_pa7: analog_pa7 {
    pinmux = <((((('A') - 'A') & 0xFU) << 9U) | (((7) & 0xFU) << 5U) | (((0x10) & 0x1FU) << 0U))>;
   };
   /omit-if-no-ref/ analog_pa8: analog_pa8 {
    pinmux = <((((('A') - 'A') & 0xFU) << 9U) | (((8) & 0xFU) << 5U) | (((0x10) & 0x1FU) << 0U))>;
   };
   /omit-if-no-ref/ analog_pa9: analog_pa9 {
    pinmux = <((((('A') - 'A') & 0xFU) << 9U) | (((9) & 0xFU) << 5U) | (((0x10) & 0x1FU) << 0U))>;
   };
   /omit-if-no-ref/ analog_pa10: analog_pa10 {
    pinmux = <((((('A') - 'A') & 0xFU) << 9U) | (((10) & 0xFU) << 5U) | (((0x10) & 0x1FU) << 0U))>;
   };
   /omit-if-no-ref/ analog_pa11: analog_pa11 {
    pinmux = <((((('A') - 'A') & 0xFU) << 9U) | (((11) & 0xFU) << 5U) | (((0x10) & 0x1FU) << 0U))>;
   };
   /omit-if-no-ref/ analog_pa12: analog_pa12 {
    pinmux = <((((('A') - 'A') & 0xFU) << 9U) | (((12) & 0xFU) << 5U) | (((0x10) & 0x1FU) << 0U))>;
   };
   /omit-if-no-ref/ analog_pa13: analog_pa13 {
    pinmux = <((((('A') - 'A') & 0xFU) << 9U) | (((13) & 0xFU) << 5U) | (((0x10) & 0x1FU) << 0U))>;
   };
   /omit-if-no-ref/ analog_pa14: analog_pa14 {
    pinmux = <((((('A') - 'A') & 0xFU) << 9U) | (((14) & 0xFU) << 5U) | (((0x10) & 0x1FU) << 0U))>;
   };
   /omit-if-no-ref/ analog_pa15: analog_pa15 {
    pinmux = <((((('A') - 'A') & 0xFU) << 9U) | (((15) & 0xFU) << 5U) | (((0x10) & 0x1FU) << 0U))>;
   };
   /omit-if-no-ref/ analog_pb0: analog_pb0 {
    pinmux = <((((('B') - 'A') & 0xFU) << 9U) | (((0) & 0xFU) << 5U) | (((0x10) & 0x1FU) << 0U))>;
   };
   /omit-if-no-ref/ analog_pb1: analog_pb1 {
    pinmux = <((((('B') - 'A') & 0xFU) << 9U) | (((1) & 0xFU) << 5U) | (((0x10) & 0x1FU) << 0U))>;
   };
   /omit-if-no-ref/ analog_pb2: analog_pb2 {
    pinmux = <((((('B') - 'A') & 0xFU) << 9U) | (((2) & 0xFU) << 5U) | (((0x10) & 0x1FU) << 0U))>;
   };
   /omit-if-no-ref/ analog_pb3: analog_pb3 {
    pinmux = <((((('B') - 'A') & 0xFU) << 9U) | (((3) & 0xFU) << 5U) | (((0x10) & 0x1FU) << 0U))>;
   };
   /omit-if-no-ref/ analog_pb4: analog_pb4 {
    pinmux = <((((('B') - 'A') & 0xFU) << 9U) | (((4) & 0xFU) << 5U) | (((0x10) & 0x1FU) << 0U))>;
   };
   /omit-if-no-ref/ analog_pb5: analog_pb5 {
    pinmux = <((((('B') - 'A') & 0xFU) << 9U) | (((5) & 0xFU) << 5U) | (((0x10) & 0x1FU) << 0U))>;
   };
   /omit-if-no-ref/ analog_pb6: analog_pb6 {
    pinmux = <((((('B') - 'A') & 0xFU) << 9U) | (((6) & 0xFU) << 5U) | (((0x10) & 0x1FU) << 0U))>;
   };
   /omit-if-no-ref/ analog_pb7: analog_pb7 {
    pinmux = <((((('B') - 'A') & 0xFU) << 9U) | (((7) & 0xFU) << 5U) | (((0x10) & 0x1FU) << 0U))>;
   };
   /omit-if-no-ref/ analog_pb8: analog_pb8 {
    pinmux = <((((('B') - 'A') & 0xFU) << 9U) | (((8) & 0xFU) << 5U) | (((0x10) & 0x1FU) << 0U))>;
   };
   /omit-if-no-ref/ analog_pb9: analog_pb9 {
    pinmux = <((((('B') - 'A') & 0xFU) << 9U) | (((9) & 0xFU) << 5U) | (((0x10) & 0x1FU) << 0U))>;
   };
   /omit-if-no-ref/ analog_pb10: analog_pb10 {
    pinmux = <((((('B') - 'A') & 0xFU) << 9U) | (((10) & 0xFU) << 5U) | (((0x10) & 0x1FU) << 0U))>;
   };
   /omit-if-no-ref/ analog_pb11: analog_pb11 {
    pinmux = <((((('B') - 'A') & 0xFU) << 9U) | (((11) & 0xFU) << 5U) | (((0x10) & 0x1FU) << 0U))>;
   };
   /omit-if-no-ref/ analog_pb12: analog_pb12 {
    pinmux = <((((('B') - 'A') & 0xFU) << 9U) | (((12) & 0xFU) << 5U) | (((0x10) & 0x1FU) << 0U))>;
   };
   /omit-if-no-ref/ analog_pb13: analog_pb13 {
    pinmux = <((((('B') - 'A') & 0xFU) << 9U) | (((13) & 0xFU) << 5U) | (((0x10) & 0x1FU) << 0U))>;
   };
   /omit-if-no-ref/ analog_pb14: analog_pb14 {
    pinmux = <((((('B') - 'A') & 0xFU) << 9U) | (((14) & 0xFU) << 5U) | (((0x10) & 0x1FU) << 0U))>;
   };
   /omit-if-no-ref/ analog_pb15: analog_pb15 {
    pinmux = <((((('B') - 'A') & 0xFU) << 9U) | (((15) & 0xFU) << 5U) | (((0x10) & 0x1FU) << 0U))>;
   };
   /omit-if-no-ref/ analog_pc0: analog_pc0 {
    pinmux = <((((('C') - 'A') & 0xFU) << 9U) | (((0) & 0xFU) << 5U) | (((0x10) & 0x1FU) << 0U))>;
   };
   /omit-if-no-ref/ analog_pc1: analog_pc1 {
    pinmux = <((((('C') - 'A') & 0xFU) << 9U) | (((1) & 0xFU) << 5U) | (((0x10) & 0x1FU) << 0U))>;
   };
   /omit-if-no-ref/ analog_pc2: analog_pc2 {
    pinmux = <((((('C') - 'A') & 0xFU) << 9U) | (((2) & 0xFU) << 5U) | (((0x10) & 0x1FU) << 0U))>;
   };
   /omit-if-no-ref/ analog_pc3: analog_pc3 {
    pinmux = <((((('C') - 'A') & 0xFU) << 9U) | (((3) & 0xFU) << 5U) | (((0x10) & 0x1FU) << 0U))>;
   };
   /omit-if-no-ref/ analog_pc4: analog_pc4 {
    pinmux = <((((('C') - 'A') & 0xFU) << 9U) | (((4) & 0xFU) << 5U) | (((0x10) & 0x1FU) << 0U))>;
   };
   /omit-if-no-ref/ analog_pc5: analog_pc5 {
    pinmux = <((((('C') - 'A') & 0xFU) << 9U) | (((5) & 0xFU) << 5U) | (((0x10) & 0x1FU) << 0U))>;
   };
   /omit-if-no-ref/ analog_pc6: analog_pc6 {
    pinmux = <((((('C') - 'A') & 0xFU) << 9U) | (((6) & 0xFU) << 5U) | (((0x10) & 0x1FU) << 0U))>;
   };
   /omit-if-no-ref/ analog_pc7: analog_pc7 {
    pinmux = <((((('C') - 'A') & 0xFU) << 9U) | (((7) & 0xFU) << 5U) | (((0x10) & 0x1FU) << 0U))>;
   };
   /omit-if-no-ref/ analog_pc8: analog_pc8 {
    pinmux = <((((('C') - 'A') & 0xFU) << 9U) | (((8) & 0xFU) << 5U) | (((0x10) & 0x1FU) << 0U))>;
   };
   /omit-if-no-ref/ analog_pc9: analog_pc9 {
    pinmux = <((((('C') - 'A') & 0xFU) << 9U) | (((9) & 0xFU) << 5U) | (((0x10) & 0x1FU) << 0U))>;
   };
   /omit-if-no-ref/ analog_pc10: analog_pc10 {
    pinmux = <((((('C') - 'A') & 0xFU) << 9U) | (((10) & 0xFU) << 5U) | (((0x10) & 0x1FU) << 0U))>;
   };
   /omit-if-no-ref/ analog_pc11: analog_pc11 {
    pinmux = <((((('C') - 'A') & 0xFU) << 9U) | (((11) & 0xFU) << 5U) | (((0x10) & 0x1FU) << 0U))>;
   };
   /omit-if-no-ref/ analog_pc12: analog_pc12 {
    pinmux = <((((('C') - 'A') & 0xFU) << 9U) | (((12) & 0xFU) << 5U) | (((0x10) & 0x1FU) << 0U))>;
   };
   /omit-if-no-ref/ analog_pc13: analog_pc13 {
    pinmux = <((((('C') - 'A') & 0xFU) << 9U) | (((13) & 0xFU) << 5U) | (((0x10) & 0x1FU) << 0U))>;
   };
   /omit-if-no-ref/ analog_pc14: analog_pc14 {
    pinmux = <((((('C') - 'A') & 0xFU) << 9U) | (((14) & 0xFU) << 5U) | (((0x10) & 0x1FU) << 0U))>;
   };
   /omit-if-no-ref/ analog_pc15: analog_pc15 {
    pinmux = <((((('C') - 'A') & 0xFU) << 9U) | (((15) & 0xFU) << 5U) | (((0x10) & 0x1FU) << 0U))>;
   };
   /omit-if-no-ref/ analog_pd0: analog_pd0 {
    pinmux = <((((('D') - 'A') & 0xFU) << 9U) | (((0) & 0xFU) << 5U) | (((0x10) & 0x1FU) << 0U))>;
   };
   /omit-if-no-ref/ analog_pd1: analog_pd1 {
    pinmux = <((((('D') - 'A') & 0xFU) << 9U) | (((1) & 0xFU) << 5U) | (((0x10) & 0x1FU) << 0U))>;
   };
   /omit-if-no-ref/ analog_pd2: analog_pd2 {
    pinmux = <((((('D') - 'A') & 0xFU) << 9U) | (((2) & 0xFU) << 5U) | (((0x10) & 0x1FU) << 0U))>;
   };
   /omit-if-no-ref/ analog_pd3: analog_pd3 {
    pinmux = <((((('D') - 'A') & 0xFU) << 9U) | (((3) & 0xFU) << 5U) | (((0x10) & 0x1FU) << 0U))>;
   };
   /omit-if-no-ref/ analog_pd4: analog_pd4 {
    pinmux = <((((('D') - 'A') & 0xFU) << 9U) | (((4) & 0xFU) << 5U) | (((0x10) & 0x1FU) << 0U))>;
   };
   /omit-if-no-ref/ analog_pd5: analog_pd5 {
    pinmux = <((((('D') - 'A') & 0xFU) << 9U) | (((5) & 0xFU) << 5U) | (((0x10) & 0x1FU) << 0U))>;
   };
   /omit-if-no-ref/ analog_pd6: analog_pd6 {
    pinmux = <((((('D') - 'A') & 0xFU) << 9U) | (((6) & 0xFU) << 5U) | (((0x10) & 0x1FU) << 0U))>;
   };
   /omit-if-no-ref/ analog_pd7: analog_pd7 {
    pinmux = <((((('D') - 'A') & 0xFU) << 9U) | (((7) & 0xFU) << 5U) | (((0x10) & 0x1FU) << 0U))>;
   };
   /omit-if-no-ref/ analog_pd8: analog_pd8 {
    pinmux = <((((('D') - 'A') & 0xFU) << 9U) | (((8) & 0xFU) << 5U) | (((0x10) & 0x1FU) << 0U))>;
   };
   /omit-if-no-ref/ analog_pd9: analog_pd9 {
    pinmux = <((((('D') - 'A') & 0xFU) << 9U) | (((9) & 0xFU) << 5U) | (((0x10) & 0x1FU) << 0U))>;
   };
   /omit-if-no-ref/ analog_pd10: analog_pd10 {
    pinmux = <((((('D') - 'A') & 0xFU) << 9U) | (((10) & 0xFU) << 5U) | (((0x10) & 0x1FU) << 0U))>;
   };
   /omit-if-no-ref/ analog_pd11: analog_pd11 {
    pinmux = <((((('D') - 'A') & 0xFU) << 9U) | (((11) & 0xFU) << 5U) | (((0x10) & 0x1FU) << 0U))>;
   };
   /omit-if-no-ref/ analog_pd12: analog_pd12 {
    pinmux = <((((('D') - 'A') & 0xFU) << 9U) | (((12) & 0xFU) << 5U) | (((0x10) & 0x1FU) << 0U))>;
   };
   /omit-if-no-ref/ analog_pd13: analog_pd13 {
    pinmux = <((((('D') - 'A') & 0xFU) << 9U) | (((13) & 0xFU) << 5U) | (((0x10) & 0x1FU) << 0U))>;
   };
   /omit-if-no-ref/ analog_pd14: analog_pd14 {
    pinmux = <((((('D') - 'A') & 0xFU) << 9U) | (((14) & 0xFU) << 5U) | (((0x10) & 0x1FU) << 0U))>;
   };
   /omit-if-no-ref/ analog_pd15: analog_pd15 {
    pinmux = <((((('D') - 'A') & 0xFU) << 9U) | (((15) & 0xFU) << 5U) | (((0x10) & 0x1FU) << 0U))>;
   };
   /omit-if-no-ref/ analog_pe0: analog_pe0 {
    pinmux = <((((('E') - 'A') & 0xFU) << 9U) | (((0) & 0xFU) << 5U) | (((0x10) & 0x1FU) << 0U))>;
   };
   /omit-if-no-ref/ analog_pe1: analog_pe1 {
    pinmux = <((((('E') - 'A') & 0xFU) << 9U) | (((1) & 0xFU) << 5U) | (((0x10) & 0x1FU) << 0U))>;
   };
   /omit-if-no-ref/ analog_pe2: analog_pe2 {
    pinmux = <((((('E') - 'A') & 0xFU) << 9U) | (((2) & 0xFU) << 5U) | (((0x10) & 0x1FU) << 0U))>;
   };
   /omit-if-no-ref/ analog_pe3: analog_pe3 {
    pinmux = <((((('E') - 'A') & 0xFU) << 9U) | (((3) & 0xFU) << 5U) | (((0x10) & 0x1FU) << 0U))>;
   };
   /omit-if-no-ref/ analog_pe4: analog_pe4 {
    pinmux = <((((('E') - 'A') & 0xFU) << 9U) | (((4) & 0xFU) << 5U) | (((0x10) & 0x1FU) << 0U))>;
   };
   /omit-if-no-ref/ analog_pe5: analog_pe5 {
    pinmux = <((((('E') - 'A') & 0xFU) << 9U) | (((5) & 0xFU) << 5U) | (((0x10) & 0x1FU) << 0U))>;
   };
   /omit-if-no-ref/ analog_pe6: analog_pe6 {
    pinmux = <((((('E') - 'A') & 0xFU) << 9U) | (((6) & 0xFU) << 5U) | (((0x10) & 0x1FU) << 0U))>;
   };
   /omit-if-no-ref/ analog_pe7: analog_pe7 {
    pinmux = <((((('E') - 'A') & 0xFU) << 9U) | (((7) & 0xFU) << 5U) | (((0x10) & 0x1FU) << 0U))>;
   };
   /omit-if-no-ref/ analog_pe8: analog_pe8 {
    pinmux = <((((('E') - 'A') & 0xFU) << 9U) | (((8) & 0xFU) << 5U) | (((0x10) & 0x1FU) << 0U))>;
   };
   /omit-if-no-ref/ analog_pe9: analog_pe9 {
    pinmux = <((((('E') - 'A') & 0xFU) << 9U) | (((9) & 0xFU) << 5U) | (((0x10) & 0x1FU) << 0U))>;
   };
   /omit-if-no-ref/ analog_pe10: analog_pe10 {
    pinmux = <((((('E') - 'A') & 0xFU) << 9U) | (((10) & 0xFU) << 5U) | (((0x10) & 0x1FU) << 0U))>;
   };
   /omit-if-no-ref/ analog_pe11: analog_pe11 {
    pinmux = <((((('E') - 'A') & 0xFU) << 9U) | (((11) & 0xFU) << 5U) | (((0x10) & 0x1FU) << 0U))>;
   };
   /omit-if-no-ref/ analog_pe12: analog_pe12 {
    pinmux = <((((('E') - 'A') & 0xFU) << 9U) | (((12) & 0xFU) << 5U) | (((0x10) & 0x1FU) << 0U))>;
   };
   /omit-if-no-ref/ analog_pe13: analog_pe13 {
    pinmux = <((((('E') - 'A') & 0xFU) << 9U) | (((13) & 0xFU) << 5U) | (((0x10) & 0x1FU) << 0U))>;
   };
   /omit-if-no-ref/ analog_pe14: analog_pe14 {
    pinmux = <((((('E') - 'A') & 0xFU) << 9U) | (((14) & 0xFU) << 5U) | (((0x10) & 0x1FU) << 0U))>;
   };
   /omit-if-no-ref/ analog_pe15: analog_pe15 {
    pinmux = <((((('E') - 'A') & 0xFU) << 9U) | (((15) & 0xFU) << 5U) | (((0x10) & 0x1FU) << 0U))>;
   };
   /omit-if-no-ref/ analog_pf0: analog_pf0 {
    pinmux = <((((('F') - 'A') & 0xFU) << 9U) | (((0) & 0xFU) << 5U) | (((0x10) & 0x1FU) << 0U))>;
   };
   /omit-if-no-ref/ analog_pf1: analog_pf1 {
    pinmux = <((((('F') - 'A') & 0xFU) << 9U) | (((1) & 0xFU) << 5U) | (((0x10) & 0x1FU) << 0U))>;
   };
   /omit-if-no-ref/ analog_pf2: analog_pf2 {
    pinmux = <((((('F') - 'A') & 0xFU) << 9U) | (((2) & 0xFU) << 5U) | (((0x10) & 0x1FU) << 0U))>;
   };
   /omit-if-no-ref/ analog_pf3: analog_pf3 {
    pinmux = <((((('F') - 'A') & 0xFU) << 9U) | (((3) & 0xFU) << 5U) | (((0x10) & 0x1FU) << 0U))>;
   };
   /omit-if-no-ref/ analog_pf4: analog_pf4 {
    pinmux = <((((('F') - 'A') & 0xFU) << 9U) | (((4) & 0xFU) << 5U) | (((0x10) & 0x1FU) << 0U))>;
   };
   /omit-if-no-ref/ analog_pf5: analog_pf5 {
    pinmux = <((((('F') - 'A') & 0xFU) << 9U) | (((5) & 0xFU) << 5U) | (((0x10) & 0x1FU) << 0U))>;
   };
   /omit-if-no-ref/ analog_pf6: analog_pf6 {
    pinmux = <((((('F') - 'A') & 0xFU) << 9U) | (((6) & 0xFU) << 5U) | (((0x10) & 0x1FU) << 0U))>;
   };
   /omit-if-no-ref/ analog_pf7: analog_pf7 {
    pinmux = <((((('F') - 'A') & 0xFU) << 9U) | (((7) & 0xFU) << 5U) | (((0x10) & 0x1FU) << 0U))>;
   };
   /omit-if-no-ref/ analog_pf8: analog_pf8 {
    pinmux = <((((('F') - 'A') & 0xFU) << 9U) | (((8) & 0xFU) << 5U) | (((0x10) & 0x1FU) << 0U))>;
   };
   /omit-if-no-ref/ analog_pf9: analog_pf9 {
    pinmux = <((((('F') - 'A') & 0xFU) << 9U) | (((9) & 0xFU) << 5U) | (((0x10) & 0x1FU) << 0U))>;
   };
   /omit-if-no-ref/ analog_pf10: analog_pf10 {
    pinmux = <((((('F') - 'A') & 0xFU) << 9U) | (((10) & 0xFU) << 5U) | (((0x10) & 0x1FU) << 0U))>;
   };
   /omit-if-no-ref/ analog_pf11: analog_pf11 {
    pinmux = <((((('F') - 'A') & 0xFU) << 9U) | (((11) & 0xFU) << 5U) | (((0x10) & 0x1FU) << 0U))>;
   };
   /omit-if-no-ref/ analog_pf12: analog_pf12 {
    pinmux = <((((('F') - 'A') & 0xFU) << 9U) | (((12) & 0xFU) << 5U) | (((0x10) & 0x1FU) << 0U))>;
   };
   /omit-if-no-ref/ analog_pf13: analog_pf13 {
    pinmux = <((((('F') - 'A') & 0xFU) << 9U) | (((13) & 0xFU) << 5U) | (((0x10) & 0x1FU) << 0U))>;
   };
   /omit-if-no-ref/ analog_pf14: analog_pf14 {
    pinmux = <((((('F') - 'A') & 0xFU) << 9U) | (((14) & 0xFU) << 5U) | (((0x10) & 0x1FU) << 0U))>;
   };
   /omit-if-no-ref/ analog_pf15: analog_pf15 {
    pinmux = <((((('F') - 'A') & 0xFU) << 9U) | (((15) & 0xFU) << 5U) | (((0x10) & 0x1FU) << 0U))>;
   };
   /omit-if-no-ref/ analog_pg0: analog_pg0 {
    pinmux = <((((('G') - 'A') & 0xFU) << 9U) | (((0) & 0xFU) << 5U) | (((0x10) & 0x1FU) << 0U))>;
   };
   /omit-if-no-ref/ analog_pg1: analog_pg1 {
    pinmux = <((((('G') - 'A') & 0xFU) << 9U) | (((1) & 0xFU) << 5U) | (((0x10) & 0x1FU) << 0U))>;
   };
   /omit-if-no-ref/ analog_pg2: analog_pg2 {
    pinmux = <((((('G') - 'A') & 0xFU) << 9U) | (((2) & 0xFU) << 5U) | (((0x10) & 0x1FU) << 0U))>;
   };
   /omit-if-no-ref/ analog_pg3: analog_pg3 {
    pinmux = <((((('G') - 'A') & 0xFU) << 9U) | (((3) & 0xFU) << 5U) | (((0x10) & 0x1FU) << 0U))>;
   };
   /omit-if-no-ref/ analog_pg4: analog_pg4 {
    pinmux = <((((('G') - 'A') & 0xFU) << 9U) | (((4) & 0xFU) << 5U) | (((0x10) & 0x1FU) << 0U))>;
   };
   /omit-if-no-ref/ analog_pg5: analog_pg5 {
    pinmux = <((((('G') - 'A') & 0xFU) << 9U) | (((5) & 0xFU) << 5U) | (((0x10) & 0x1FU) << 0U))>;
   };
   /omit-if-no-ref/ analog_pg6: analog_pg6 {
    pinmux = <((((('G') - 'A') & 0xFU) << 9U) | (((6) & 0xFU) << 5U) | (((0x10) & 0x1FU) << 0U))>;
   };
   /omit-if-no-ref/ analog_pg7: analog_pg7 {
    pinmux = <((((('G') - 'A') & 0xFU) << 9U) | (((7) & 0xFU) << 5U) | (((0x10) & 0x1FU) << 0U))>;
   };
   /omit-if-no-ref/ analog_pg8: analog_pg8 {
    pinmux = <((((('G') - 'A') & 0xFU) << 9U) | (((8) & 0xFU) << 5U) | (((0x10) & 0x1FU) << 0U))>;
   };
   /omit-if-no-ref/ analog_pg9: analog_pg9 {
    pinmux = <((((('G') - 'A') & 0xFU) << 9U) | (((9) & 0xFU) << 5U) | (((0x10) & 0x1FU) << 0U))>;
   };
   /omit-if-no-ref/ analog_pg10: analog_pg10 {
    pinmux = <((((('G') - 'A') & 0xFU) << 9U) | (((10) & 0xFU) << 5U) | (((0x10) & 0x1FU) << 0U))>;
   };
   /omit-if-no-ref/ analog_pg11: analog_pg11 {
    pinmux = <((((('G') - 'A') & 0xFU) << 9U) | (((11) & 0xFU) << 5U) | (((0x10) & 0x1FU) << 0U))>;
   };
   /omit-if-no-ref/ analog_pg12: analog_pg12 {
    pinmux = <((((('G') - 'A') & 0xFU) << 9U) | (((12) & 0xFU) << 5U) | (((0x10) & 0x1FU) << 0U))>;
   };
   /omit-if-no-ref/ analog_pg13: analog_pg13 {
    pinmux = <((((('G') - 'A') & 0xFU) << 9U) | (((13) & 0xFU) << 5U) | (((0x10) & 0x1FU) << 0U))>;
   };
   /omit-if-no-ref/ analog_pg14: analog_pg14 {
    pinmux = <((((('G') - 'A') & 0xFU) << 9U) | (((14) & 0xFU) << 5U) | (((0x10) & 0x1FU) << 0U))>;
   };
   /omit-if-no-ref/ analog_pg15: analog_pg15 {
    pinmux = <((((('G') - 'A') & 0xFU) << 9U) | (((15) & 0xFU) << 5U) | (((0x10) & 0x1FU) << 0U))>;
   };
   /omit-if-no-ref/ analog_ph0: analog_ph0 {
    pinmux = <((((('H') - 'A') & 0xFU) << 9U) | (((0) & 0xFU) << 5U) | (((0x10) & 0x1FU) << 0U))>;
   };
   /omit-if-no-ref/ analog_ph1: analog_ph1 {
    pinmux = <((((('H') - 'A') & 0xFU) << 9U) | (((1) & 0xFU) << 5U) | (((0x10) & 0x1FU) << 0U))>;
   };
   /omit-if-no-ref/ can1_rx_pa11: can1_rx_pa11 {
    pinmux = <((((('A') - 'A') & 0xFU) << 9U) | (((11) & 0xFU) << 5U) | (((0x9) & 0x1FU) << 0U))>;
    bias-pull-up;
   };
   /omit-if-no-ref/ can1_rx_pb8: can1_rx_pb8 {
    pinmux = <((((('B') - 'A') & 0xFU) << 9U) | (((8) & 0xFU) << 5U) | (((0x9) & 0x1FU) << 0U))>;
    bias-pull-up;
   };
   /omit-if-no-ref/ can1_rx_pd0: can1_rx_pd0 {
    pinmux = <((((('D') - 'A') & 0xFU) << 9U) | (((0) & 0xFU) << 5U) | (((0x9) & 0x1FU) << 0U))>;
    bias-pull-up;
   };
   /omit-if-no-ref/ can2_rx_pb5: can2_rx_pb5 {
    pinmux = <((((('B') - 'A') & 0xFU) << 9U) | (((5) & 0xFU) << 5U) | (((0x9) & 0x1FU) << 0U))>;
    bias-pull-up;
   };
   /omit-if-no-ref/ can2_rx_pb12: can2_rx_pb12 {
    pinmux = <((((('B') - 'A') & 0xFU) << 9U) | (((12) & 0xFU) << 5U) | (((0x9) & 0x1FU) << 0U))>;
    bias-pull-up;
   };
   /omit-if-no-ref/ can3_rx_pa8: can3_rx_pa8 {
    pinmux = <((((('A') - 'A') & 0xFU) << 9U) | (((8) & 0xFU) << 5U) | (((0xb) & 0x1FU) << 0U))>;
    bias-pull-up;
   };
   /omit-if-no-ref/ can3_rx_pb3: can3_rx_pb3 {
    pinmux = <((((('B') - 'A') & 0xFU) << 9U) | (((3) & 0xFU) << 5U) | (((0xb) & 0x1FU) << 0U))>;
    bias-pull-up;
   };
   /omit-if-no-ref/ can1_tx_pa12: can1_tx_pa12 {
    pinmux = <((((('A') - 'A') & 0xFU) << 9U) | (((12) & 0xFU) << 5U) | (((0x9) & 0x1FU) << 0U))>;
   };
   /omit-if-no-ref/ can1_tx_pb9: can1_tx_pb9 {
    pinmux = <((((('B') - 'A') & 0xFU) << 9U) | (((9) & 0xFU) << 5U) | (((0x9) & 0x1FU) << 0U))>;
   };
   /omit-if-no-ref/ can1_tx_pd1: can1_tx_pd1 {
    pinmux = <((((('D') - 'A') & 0xFU) << 9U) | (((1) & 0xFU) << 5U) | (((0x9) & 0x1FU) << 0U))>;
   };
   /omit-if-no-ref/ can2_tx_pb6: can2_tx_pb6 {
    pinmux = <((((('B') - 'A') & 0xFU) << 9U) | (((6) & 0xFU) << 5U) | (((0x9) & 0x1FU) << 0U))>;
   };
   /omit-if-no-ref/ can2_tx_pb13: can2_tx_pb13 {
    pinmux = <((((('B') - 'A') & 0xFU) << 9U) | (((13) & 0xFU) << 5U) | (((0x9) & 0x1FU) << 0U))>;
   };
   /omit-if-no-ref/ can3_tx_pa15: can3_tx_pa15 {
    pinmux = <((((('A') - 'A') & 0xFU) << 9U) | (((15) & 0xFU) << 5U) | (((0xb) & 0x1FU) << 0U))>;
   };
   /omit-if-no-ref/ can3_tx_pb4: can3_tx_pb4 {
    pinmux = <((((('B') - 'A') & 0xFU) << 9U) | (((4) & 0xFU) << 5U) | (((0xb) & 0x1FU) << 0U))>;
   };
   /omit-if-no-ref/ dac_out1_pa4: dac_out1_pa4 {
    pinmux = <((((('A') - 'A') & 0xFU) << 9U) | (((4) & 0xFU) << 5U) | (((0x10) & 0x1FU) << 0U))>;
   };
   /omit-if-no-ref/ dac_out2_pa5: dac_out2_pa5 {
    pinmux = <((((('A') - 'A') & 0xFU) << 9U) | (((5) & 0xFU) << 5U) | (((0x10) & 0x1FU) << 0U))>;
   };
   /omit-if-no-ref/ eth_col_pa3: eth_col_pa3 {
    pinmux = <((((('A') - 'A') & 0xFU) << 9U) | (((3) & 0xFU) << 5U) | (((0xb) & 0x1FU) << 0U))>;
    slew-rate = "very-high-speed";
   };
   /omit-if-no-ref/ eth_crs_pa0: eth_crs_pa0 {
    pinmux = <((((('A') - 'A') & 0xFU) << 9U) | (((0) & 0xFU) << 5U) | (((0xb) & 0x1FU) << 0U))>;
    slew-rate = "very-high-speed";
   };
   /omit-if-no-ref/ eth_crs_dv_pa7: eth_crs_dv_pa7 {
    pinmux = <((((('A') - 'A') & 0xFU) << 9U) | (((7) & 0xFU) << 5U) | (((0xb) & 0x1FU) << 0U))>;
    slew-rate = "very-high-speed";
   };
   /omit-if-no-ref/ eth_mdc_pc1: eth_mdc_pc1 {
    pinmux = <((((('C') - 'A') & 0xFU) << 9U) | (((1) & 0xFU) << 5U) | (((0xb) & 0x1FU) << 0U))>;
    slew-rate = "very-high-speed";
   };
   /omit-if-no-ref/ eth_mdio_pa2: eth_mdio_pa2 {
    pinmux = <((((('A') - 'A') & 0xFU) << 9U) | (((2) & 0xFU) << 5U) | (((0xb) & 0x1FU) << 0U))>;
    slew-rate = "very-high-speed";
   };
   /omit-if-no-ref/ eth_pps_out_pb5: eth_pps_out_pb5 {
    pinmux = <((((('B') - 'A') & 0xFU) << 9U) | (((5) & 0xFU) << 5U) | (((0xb) & 0x1FU) << 0U))>;
    slew-rate = "very-high-speed";
   };
   /omit-if-no-ref/ eth_pps_out_pg8: eth_pps_out_pg8 {
    pinmux = <((((('G') - 'A') & 0xFU) << 9U) | (((8) & 0xFU) << 5U) | (((0xb) & 0x1FU) << 0U))>;
    slew-rate = "very-high-speed";
   };
   /omit-if-no-ref/ eth_ref_clk_pa1: eth_ref_clk_pa1 {
    pinmux = <((((('A') - 'A') & 0xFU) << 9U) | (((1) & 0xFU) << 5U) | (((0xb) & 0x1FU) << 0U))>;
    slew-rate = "very-high-speed";
   };
   /omit-if-no-ref/ eth_rxd0_pc4: eth_rxd0_pc4 {
    pinmux = <((((('C') - 'A') & 0xFU) << 9U) | (((4) & 0xFU) << 5U) | (((0xb) & 0x1FU) << 0U))>;
    slew-rate = "very-high-speed";
   };
   /omit-if-no-ref/ eth_rxd1_pc5: eth_rxd1_pc5 {
    pinmux = <((((('C') - 'A') & 0xFU) << 9U) | (((5) & 0xFU) << 5U) | (((0xb) & 0x1FU) << 0U))>;
    slew-rate = "very-high-speed";
   };
   /omit-if-no-ref/ eth_rxd2_pb0: eth_rxd2_pb0 {
    pinmux = <((((('B') - 'A') & 0xFU) << 9U) | (((0) & 0xFU) << 5U) | (((0xb) & 0x1FU) << 0U))>;
    slew-rate = "very-high-speed";
   };
   /omit-if-no-ref/ eth_rxd3_pb1: eth_rxd3_pb1 {
    pinmux = <((((('B') - 'A') & 0xFU) << 9U) | (((1) & 0xFU) << 5U) | (((0xb) & 0x1FU) << 0U))>;
    slew-rate = "very-high-speed";
   };
   /omit-if-no-ref/ eth_rx_clk_pa1: eth_rx_clk_pa1 {
    pinmux = <((((('A') - 'A') & 0xFU) << 9U) | (((1) & 0xFU) << 5U) | (((0xb) & 0x1FU) << 0U))>;
    slew-rate = "very-high-speed";
   };
   /omit-if-no-ref/ eth_rx_dv_pa7: eth_rx_dv_pa7 {
    pinmux = <((((('A') - 'A') & 0xFU) << 9U) | (((7) & 0xFU) << 5U) | (((0xb) & 0x1FU) << 0U))>;
    slew-rate = "very-high-speed";
   };
   /omit-if-no-ref/ eth_rx_er_pb10: eth_rx_er_pb10 {
    pinmux = <((((('B') - 'A') & 0xFU) << 9U) | (((10) & 0xFU) << 5U) | (((0xb) & 0x1FU) << 0U))>;
    slew-rate = "very-high-speed";
   };
   /omit-if-no-ref/ eth_txd0_pb12: eth_txd0_pb12 {
    pinmux = <((((('B') - 'A') & 0xFU) << 9U) | (((12) & 0xFU) << 5U) | (((0xb) & 0x1FU) << 0U))>;
    slew-rate = "very-high-speed";
   };
   /omit-if-no-ref/ eth_txd0_pg13: eth_txd0_pg13 {
    pinmux = <((((('G') - 'A') & 0xFU) << 9U) | (((13) & 0xFU) << 5U) | (((0xb) & 0x1FU) << 0U))>;
    slew-rate = "very-high-speed";
   };
   /omit-if-no-ref/ eth_txd1_pb13: eth_txd1_pb13 {
    pinmux = <((((('B') - 'A') & 0xFU) << 9U) | (((13) & 0xFU) << 5U) | (((0xb) & 0x1FU) << 0U))>;
    slew-rate = "very-high-speed";
   };
   /omit-if-no-ref/ eth_txd1_pg14: eth_txd1_pg14 {
    pinmux = <((((('G') - 'A') & 0xFU) << 9U) | (((14) & 0xFU) << 5U) | (((0xb) & 0x1FU) << 0U))>;
    slew-rate = "very-high-speed";
   };
   /omit-if-no-ref/ eth_txd2_pc2: eth_txd2_pc2 {
    pinmux = <((((('C') - 'A') & 0xFU) << 9U) | (((2) & 0xFU) << 5U) | (((0xb) & 0x1FU) << 0U))>;
    slew-rate = "very-high-speed";
   };
   /omit-if-no-ref/ eth_txd3_pb8: eth_txd3_pb8 {
    pinmux = <((((('B') - 'A') & 0xFU) << 9U) | (((8) & 0xFU) << 5U) | (((0xb) & 0x1FU) << 0U))>;
    slew-rate = "very-high-speed";
   };
   /omit-if-no-ref/ eth_txd3_pe2: eth_txd3_pe2 {
    pinmux = <((((('E') - 'A') & 0xFU) << 9U) | (((2) & 0xFU) << 5U) | (((0xb) & 0x1FU) << 0U))>;
    slew-rate = "very-high-speed";
   };
   /omit-if-no-ref/ eth_tx_clk_pc3: eth_tx_clk_pc3 {
    pinmux = <((((('C') - 'A') & 0xFU) << 9U) | (((3) & 0xFU) << 5U) | (((0xb) & 0x1FU) << 0U))>;
    slew-rate = "very-high-speed";
   };
   /omit-if-no-ref/ eth_tx_en_pb11: eth_tx_en_pb11 {
    pinmux = <((((('B') - 'A') & 0xFU) << 9U) | (((11) & 0xFU) << 5U) | (((0xb) & 0x1FU) << 0U))>;
    slew-rate = "very-high-speed";
   };
   /omit-if-no-ref/ eth_tx_en_pg11: eth_tx_en_pg11 {
    pinmux = <((((('G') - 'A') & 0xFU) << 9U) | (((11) & 0xFU) << 5U) | (((0xb) & 0x1FU) << 0U))>;
    slew-rate = "very-high-speed";
   };
   /omit-if-no-ref/ fmc_sdnwe_pa7: fmc_sdnwe_pa7 {
    pinmux = <((((('A') - 'A') & 0xFU) << 9U) | (((7) & 0xFU) << 5U) | (((0xc) & 0x1FU) << 0U))>;
    bias-pull-up;
    slew-rate = "very-high-speed";
   };
   /omit-if-no-ref/ fmc_sdcke1_pb5: fmc_sdcke1_pb5 {
    pinmux = <((((('B') - 'A') & 0xFU) << 9U) | (((5) & 0xFU) << 5U) | (((0xc) & 0x1FU) << 0U))>;
    bias-pull-up;
    slew-rate = "very-high-speed";
   };
   /omit-if-no-ref/ fmc_sdne1_pb6: fmc_sdne1_pb6 {
    pinmux = <((((('B') - 'A') & 0xFU) << 9U) | (((6) & 0xFU) << 5U) | (((0xc) & 0x1FU) << 0U))>;
    bias-pull-up;
    slew-rate = "very-high-speed";
   };
   /omit-if-no-ref/ fmc_nl_pb7: fmc_nl_pb7 {
    pinmux = <((((('B') - 'A') & 0xFU) << 9U) | (((7) & 0xFU) << 5U) | (((0xc) & 0x1FU) << 0U))>;
    bias-pull-up;
    slew-rate = "very-high-speed";
   };
   /omit-if-no-ref/ fmc_sdnwe_pc0: fmc_sdnwe_pc0 {
    pinmux = <((((('C') - 'A') & 0xFU) << 9U) | (((0) & 0xFU) << 5U) | (((0xc) & 0x1FU) << 0U))>;
    bias-pull-up;
    slew-rate = "very-high-speed";
   };
   /omit-if-no-ref/ fmc_sdne0_pc2: fmc_sdne0_pc2 {
    pinmux = <((((('C') - 'A') & 0xFU) << 9U) | (((2) & 0xFU) << 5U) | (((0xc) & 0x1FU) << 0U))>;
    bias-pull-up;
    slew-rate = "very-high-speed";
   };
   /omit-if-no-ref/ fmc_sdcke0_pc3: fmc_sdcke0_pc3 {
    pinmux = <((((('C') - 'A') & 0xFU) << 9U) | (((3) & 0xFU) << 5U) | (((0xc) & 0x1FU) << 0U))>;
    bias-pull-up;
    slew-rate = "very-high-speed";
   };
   /omit-if-no-ref/ fmc_sdne0_pc4: fmc_sdne0_pc4 {
    pinmux = <((((('C') - 'A') & 0xFU) << 9U) | (((4) & 0xFU) << 5U) | (((0xc) & 0x1FU) << 0U))>;
    bias-pull-up;
    slew-rate = "very-high-speed";
   };
   /omit-if-no-ref/ fmc_sdcke0_pc5: fmc_sdcke0_pc5 {
    pinmux = <((((('C') - 'A') & 0xFU) << 9U) | (((5) & 0xFU) << 5U) | (((0xc) & 0x1FU) << 0U))>;
    bias-pull-up;
    slew-rate = "very-high-speed";
   };
   /omit-if-no-ref/ fmc_nwait_pc6: fmc_nwait_pc6 {
    pinmux = <((((('C') - 'A') & 0xFU) << 9U) | (((6) & 0xFU) << 5U) | (((0x9) & 0x1FU) << 0U))>;
    bias-pull-up;
    slew-rate = "very-high-speed";
   };
   /omit-if-no-ref/ fmc_ne1_pc7: fmc_ne1_pc7 {
    pinmux = <((((('C') - 'A') & 0xFU) << 9U) | (((7) & 0xFU) << 5U) | (((0x9) & 0x1FU) << 0U))>;
    bias-pull-up;
    slew-rate = "very-high-speed";
   };
   /omit-if-no-ref/ fmc_nce_pc8: fmc_nce_pc8 {
    pinmux = <((((('C') - 'A') & 0xFU) << 9U) | (((8) & 0xFU) << 5U) | (((0x9) & 0x1FU) << 0U))>;
    bias-pull-up;
    slew-rate = "very-high-speed";
   };
   /omit-if-no-ref/ fmc_ne2_pc8: fmc_ne2_pc8 {
    pinmux = <((((('C') - 'A') & 0xFU) << 9U) | (((8) & 0xFU) << 5U) | (((0x9) & 0x1FU) << 0U))>;
    bias-pull-up;
    slew-rate = "very-high-speed";
   };
   /omit-if-no-ref/ fmc_d2_pd0: fmc_d2_pd0 {
    pinmux = <((((('D') - 'A') & 0xFU) << 9U) | (((0) & 0xFU) << 5U) | (((0xc) & 0x1FU) << 0U))>;
    bias-pull-up;
    slew-rate = "very-high-speed";
   };
   /omit-if-no-ref/ fmc_d3_pd1: fmc_d3_pd1 {
    pinmux = <((((('D') - 'A') & 0xFU) << 9U) | (((1) & 0xFU) << 5U) | (((0xc) & 0x1FU) << 0U))>;
    bias-pull-up;
    slew-rate = "very-high-speed";
   };
   /omit-if-no-ref/ fmc_clk_pd3: fmc_clk_pd3 {
    pinmux = <((((('D') - 'A') & 0xFU) << 9U) | (((3) & 0xFU) << 5U) | (((0xc) & 0x1FU) << 0U))>;
    bias-pull-up;
    slew-rate = "very-high-speed";
   };
   /omit-if-no-ref/ fmc_noe_pd4: fmc_noe_pd4 {
    pinmux = <((((('D') - 'A') & 0xFU) << 9U) | (((4) & 0xFU) << 5U) | (((0xc) & 0x1FU) << 0U))>;
    bias-pull-up;
    slew-rate = "very-high-speed";
   };
   /omit-if-no-ref/ fmc_nwe_pd5: fmc_nwe_pd5 {
    pinmux = <((((('D') - 'A') & 0xFU) << 9U) | (((5) & 0xFU) << 5U) | (((0xc) & 0x1FU) << 0U))>;
    bias-pull-up;
    slew-rate = "very-high-speed";
   };
   /omit-if-no-ref/ fmc_nwait_pd6: fmc_nwait_pd6 {
    pinmux = <((((('D') - 'A') & 0xFU) << 9U) | (((6) & 0xFU) << 5U) | (((0xc) & 0x1FU) << 0U))>;
    bias-pull-up;
    slew-rate = "very-high-speed";
   };
   /omit-if-no-ref/ fmc_ne1_pd7: fmc_ne1_pd7 {
    pinmux = <((((('D') - 'A') & 0xFU) << 9U) | (((7) & 0xFU) << 5U) | (((0xc) & 0x1FU) << 0U))>;
    bias-pull-up;
    slew-rate = "very-high-speed";
   };
   /omit-if-no-ref/ fmc_d13_pd8: fmc_d13_pd8 {
    pinmux = <((((('D') - 'A') & 0xFU) << 9U) | (((8) & 0xFU) << 5U) | (((0xc) & 0x1FU) << 0U))>;
    bias-pull-up;
    slew-rate = "very-high-speed";
   };
   /omit-if-no-ref/ fmc_d14_pd9: fmc_d14_pd9 {
    pinmux = <((((('D') - 'A') & 0xFU) << 9U) | (((9) & 0xFU) << 5U) | (((0xc) & 0x1FU) << 0U))>;
    bias-pull-up;
    slew-rate = "very-high-speed";
   };
   /omit-if-no-ref/ fmc_d15_pd10: fmc_d15_pd10 {
    pinmux = <((((('D') - 'A') & 0xFU) << 9U) | (((10) & 0xFU) << 5U) | (((0xc) & 0x1FU) << 0U))>;
    bias-pull-up;
    slew-rate = "very-high-speed";
   };
   /omit-if-no-ref/ fmc_a16_pd11: fmc_a16_pd11 {
    pinmux = <((((('D') - 'A') & 0xFU) << 9U) | (((11) & 0xFU) << 5U) | (((0xc) & 0x1FU) << 0U))>;
    bias-pull-up;
    slew-rate = "very-high-speed";
   };
   /omit-if-no-ref/ fmc_a17_pd12: fmc_a17_pd12 {
    pinmux = <((((('D') - 'A') & 0xFU) << 9U) | (((12) & 0xFU) << 5U) | (((0xc) & 0x1FU) << 0U))>;
    bias-pull-up;
    slew-rate = "very-high-speed";
   };
   /omit-if-no-ref/ fmc_a18_pd13: fmc_a18_pd13 {
    pinmux = <((((('D') - 'A') & 0xFU) << 9U) | (((13) & 0xFU) << 5U) | (((0xc) & 0x1FU) << 0U))>;
    bias-pull-up;
    slew-rate = "very-high-speed";
   };
   /omit-if-no-ref/ fmc_d0_pd14: fmc_d0_pd14 {
    pinmux = <((((('D') - 'A') & 0xFU) << 9U) | (((14) & 0xFU) << 5U) | (((0xc) & 0x1FU) << 0U))>;
    bias-pull-up;
    slew-rate = "very-high-speed";
   };
   /omit-if-no-ref/ fmc_d1_pd15: fmc_d1_pd15 {
    pinmux = <((((('D') - 'A') & 0xFU) << 9U) | (((15) & 0xFU) << 5U) | (((0xc) & 0x1FU) << 0U))>;
    bias-pull-up;
    slew-rate = "very-high-speed";
   };
   /omit-if-no-ref/ fmc_nbl0_pe0: fmc_nbl0_pe0 {
    pinmux = <((((('E') - 'A') & 0xFU) << 9U) | (((0) & 0xFU) << 5U) | (((0xc) & 0x1FU) << 0U))>;
    bias-pull-up;
    slew-rate = "very-high-speed";
   };
   /omit-if-no-ref/ fmc_nbl1_pe1: fmc_nbl1_pe1 {
    pinmux = <((((('E') - 'A') & 0xFU) << 9U) | (((1) & 0xFU) << 5U) | (((0xc) & 0x1FU) << 0U))>;
    bias-pull-up;
    slew-rate = "very-high-speed";
   };
   /omit-if-no-ref/ fmc_a23_pe2: fmc_a23_pe2 {
    pinmux = <((((('E') - 'A') & 0xFU) << 9U) | (((2) & 0xFU) << 5U) | (((0xc) & 0x1FU) << 0U))>;
    bias-pull-up;
    slew-rate = "very-high-speed";
   };
   /omit-if-no-ref/ fmc_a19_pe3: fmc_a19_pe3 {
    pinmux = <((((('E') - 'A') & 0xFU) << 9U) | (((3) & 0xFU) << 5U) | (((0xc) & 0x1FU) << 0U))>;
    bias-pull-up;
    slew-rate = "very-high-speed";
   };
   /omit-if-no-ref/ fmc_a20_pe4: fmc_a20_pe4 {
    pinmux = <((((('E') - 'A') & 0xFU) << 9U) | (((4) & 0xFU) << 5U) | (((0xc) & 0x1FU) << 0U))>;
    bias-pull-up;
    slew-rate = "very-high-speed";
   };
   /omit-if-no-ref/ fmc_a21_pe5: fmc_a21_pe5 {
    pinmux = <((((('E') - 'A') & 0xFU) << 9U) | (((5) & 0xFU) << 5U) | (((0xc) & 0x1FU) << 0U))>;
    bias-pull-up;
    slew-rate = "very-high-speed";
   };
   /omit-if-no-ref/ fmc_a22_pe6: fmc_a22_pe6 {
    pinmux = <((((('E') - 'A') & 0xFU) << 9U) | (((6) & 0xFU) << 5U) | (((0xc) & 0x1FU) << 0U))>;
    bias-pull-up;
    slew-rate = "very-high-speed";
   };
   /omit-if-no-ref/ fmc_d4_pe7: fmc_d4_pe7 {
    pinmux = <((((('E') - 'A') & 0xFU) << 9U) | (((7) & 0xFU) << 5U) | (((0xc) & 0x1FU) << 0U))>;
    bias-pull-up;
    slew-rate = "very-high-speed";
   };
   /omit-if-no-ref/ fmc_d5_pe8: fmc_d5_pe8 {
    pinmux = <((((('E') - 'A') & 0xFU) << 9U) | (((8) & 0xFU) << 5U) | (((0xc) & 0x1FU) << 0U))>;
    bias-pull-up;
    slew-rate = "very-high-speed";
   };
   /omit-if-no-ref/ fmc_d6_pe9: fmc_d6_pe9 {
    pinmux = <((((('E') - 'A') & 0xFU) << 9U) | (((9) & 0xFU) << 5U) | (((0xc) & 0x1FU) << 0U))>;
    bias-pull-up;
    slew-rate = "very-high-speed";
   };
   /omit-if-no-ref/ fmc_d7_pe10: fmc_d7_pe10 {
    pinmux = <((((('E') - 'A') & 0xFU) << 9U) | (((10) & 0xFU) << 5U) | (((0xc) & 0x1FU) << 0U))>;
    bias-pull-up;
    slew-rate = "very-high-speed";
   };
   /omit-if-no-ref/ fmc_d8_pe11: fmc_d8_pe11 {
    pinmux = <((((('E') - 'A') & 0xFU) << 9U) | (((11) & 0xFU) << 5U) | (((0xc) & 0x1FU) << 0U))>;
    bias-pull-up;
    slew-rate = "very-high-speed";
   };
   /omit-if-no-ref/ fmc_d9_pe12: fmc_d9_pe12 {
    pinmux = <((((('E') - 'A') & 0xFU) << 9U) | (((12) & 0xFU) << 5U) | (((0xc) & 0x1FU) << 0U))>;
    bias-pull-up;
    slew-rate = "very-high-speed";
   };
   /omit-if-no-ref/ fmc_d10_pe13: fmc_d10_pe13 {
    pinmux = <((((('E') - 'A') & 0xFU) << 9U) | (((13) & 0xFU) << 5U) | (((0xc) & 0x1FU) << 0U))>;
    bias-pull-up;
    slew-rate = "very-high-speed";
   };
   /omit-if-no-ref/ fmc_d11_pe14: fmc_d11_pe14 {
    pinmux = <((((('E') - 'A') & 0xFU) << 9U) | (((14) & 0xFU) << 5U) | (((0xc) & 0x1FU) << 0U))>;
    bias-pull-up;
    slew-rate = "very-high-speed";
   };
   /omit-if-no-ref/ fmc_d12_pe15: fmc_d12_pe15 {
    pinmux = <((((('E') - 'A') & 0xFU) << 9U) | (((15) & 0xFU) << 5U) | (((0xc) & 0x1FU) << 0U))>;
    bias-pull-up;
    slew-rate = "very-high-speed";
   };
   /omit-if-no-ref/ fmc_a0_pf0: fmc_a0_pf0 {
    pinmux = <((((('F') - 'A') & 0xFU) << 9U) | (((0) & 0xFU) << 5U) | (((0xc) & 0x1FU) << 0U))>;
    bias-pull-up;
    slew-rate = "very-high-speed";
   };
   /omit-if-no-ref/ fmc_a1_pf1: fmc_a1_pf1 {
    pinmux = <((((('F') - 'A') & 0xFU) << 9U) | (((1) & 0xFU) << 5U) | (((0xc) & 0x1FU) << 0U))>;
    bias-pull-up;
    slew-rate = "very-high-speed";
   };
   /omit-if-no-ref/ fmc_a2_pf2: fmc_a2_pf2 {
    pinmux = <((((('F') - 'A') & 0xFU) << 9U) | (((2) & 0xFU) << 5U) | (((0xc) & 0x1FU) << 0U))>;
    bias-pull-up;
    slew-rate = "very-high-speed";
   };
   /omit-if-no-ref/ fmc_a3_pf3: fmc_a3_pf3 {
    pinmux = <((((('F') - 'A') & 0xFU) << 9U) | (((3) & 0xFU) << 5U) | (((0xc) & 0x1FU) << 0U))>;
    bias-pull-up;
    slew-rate = "very-high-speed";
   };
   /omit-if-no-ref/ fmc_a4_pf4: fmc_a4_pf4 {
    pinmux = <((((('F') - 'A') & 0xFU) << 9U) | (((4) & 0xFU) << 5U) | (((0xc) & 0x1FU) << 0U))>;
    bias-pull-up;
    slew-rate = "very-high-speed";
   };
   /omit-if-no-ref/ fmc_a5_pf5: fmc_a5_pf5 {
    pinmux = <((((('F') - 'A') & 0xFU) << 9U) | (((5) & 0xFU) << 5U) | (((0xc) & 0x1FU) << 0U))>;
    bias-pull-up;
    slew-rate = "very-high-speed";
   };
   /omit-if-no-ref/ fmc_sdnras_pf11: fmc_sdnras_pf11 {
    pinmux = <((((('F') - 'A') & 0xFU) << 9U) | (((11) & 0xFU) << 5U) | (((0xc) & 0x1FU) << 0U))>;
    bias-pull-up;
    slew-rate = "very-high-speed";
   };
   /omit-if-no-ref/ fmc_a6_pf12: fmc_a6_pf12 {
    pinmux = <((((('F') - 'A') & 0xFU) << 9U) | (((12) & 0xFU) << 5U) | (((0xc) & 0x1FU) << 0U))>;
    bias-pull-up;
    slew-rate = "very-high-speed";
   };
   /omit-if-no-ref/ fmc_a7_pf13: fmc_a7_pf13 {
    pinmux = <((((('F') - 'A') & 0xFU) << 9U) | (((13) & 0xFU) << 5U) | (((0xc) & 0x1FU) << 0U))>;
    bias-pull-up;
    slew-rate = "very-high-speed";
   };
   /omit-if-no-ref/ fmc_a8_pf14: fmc_a8_pf14 {
    pinmux = <((((('F') - 'A') & 0xFU) << 9U) | (((14) & 0xFU) << 5U) | (((0xc) & 0x1FU) << 0U))>;
    bias-pull-up;
    slew-rate = "very-high-speed";
   };
   /omit-if-no-ref/ fmc_a9_pf15: fmc_a9_pf15 {
    pinmux = <((((('F') - 'A') & 0xFU) << 9U) | (((15) & 0xFU) << 5U) | (((0xc) & 0x1FU) << 0U))>;
    bias-pull-up;
    slew-rate = "very-high-speed";
   };
   /omit-if-no-ref/ fmc_a10_pg0: fmc_a10_pg0 {
    pinmux = <((((('G') - 'A') & 0xFU) << 9U) | (((0) & 0xFU) << 5U) | (((0xc) & 0x1FU) << 0U))>;
    bias-pull-up;
    slew-rate = "very-high-speed";
   };
   /omit-if-no-ref/ fmc_a11_pg1: fmc_a11_pg1 {
    pinmux = <((((('G') - 'A') & 0xFU) << 9U) | (((1) & 0xFU) << 5U) | (((0xc) & 0x1FU) << 0U))>;
    bias-pull-up;
    slew-rate = "very-high-speed";
   };
   /omit-if-no-ref/ fmc_a12_pg2: fmc_a12_pg2 {
    pinmux = <((((('G') - 'A') & 0xFU) << 9U) | (((2) & 0xFU) << 5U) | (((0xc) & 0x1FU) << 0U))>;
    bias-pull-up;
    slew-rate = "very-high-speed";
   };
   /omit-if-no-ref/ fmc_a13_pg3: fmc_a13_pg3 {
    pinmux = <((((('G') - 'A') & 0xFU) << 9U) | (((3) & 0xFU) << 5U) | (((0xc) & 0x1FU) << 0U))>;
    bias-pull-up;
    slew-rate = "very-high-speed";
   };
   /omit-if-no-ref/ fmc_a14_pg4: fmc_a14_pg4 {
    pinmux = <((((('G') - 'A') & 0xFU) << 9U) | (((4) & 0xFU) << 5U) | (((0xc) & 0x1FU) << 0U))>;
    bias-pull-up;
    slew-rate = "very-high-speed";
   };
   /omit-if-no-ref/ fmc_a15_pg5: fmc_a15_pg5 {
    pinmux = <((((('G') - 'A') & 0xFU) << 9U) | (((5) & 0xFU) << 5U) | (((0xc) & 0x1FU) << 0U))>;
    bias-pull-up;
    slew-rate = "very-high-speed";
   };
   /omit-if-no-ref/ fmc_ne3_pg6: fmc_ne3_pg6 {
    pinmux = <((((('G') - 'A') & 0xFU) << 9U) | (((6) & 0xFU) << 5U) | (((0xc) & 0x1FU) << 0U))>;
    bias-pull-up;
    slew-rate = "very-high-speed";
   };
   /omit-if-no-ref/ fmc_int_pg7: fmc_int_pg7 {
    pinmux = <((((('G') - 'A') & 0xFU) << 9U) | (((7) & 0xFU) << 5U) | (((0xc) & 0x1FU) << 0U))>;
    bias-pull-up;
    slew-rate = "very-high-speed";
   };
   /omit-if-no-ref/ fmc_sdclk_pg8: fmc_sdclk_pg8 {
    pinmux = <((((('G') - 'A') & 0xFU) << 9U) | (((8) & 0xFU) << 5U) | (((0xc) & 0x1FU) << 0U))>;
    bias-pull-up;
    slew-rate = "very-high-speed";
   };
   /omit-if-no-ref/ fmc_nce_pg9: fmc_nce_pg9 {
    pinmux = <((((('G') - 'A') & 0xFU) << 9U) | (((9) & 0xFU) << 5U) | (((0xc) & 0x1FU) << 0U))>;
    bias-pull-up;
    slew-rate = "very-high-speed";
   };
   /omit-if-no-ref/ fmc_ne2_pg9: fmc_ne2_pg9 {
    pinmux = <((((('G') - 'A') & 0xFU) << 9U) | (((9) & 0xFU) << 5U) | (((0xc) & 0x1FU) << 0U))>;
    bias-pull-up;
    slew-rate = "very-high-speed";
   };
   /omit-if-no-ref/ fmc_ne3_pg10: fmc_ne3_pg10 {
    pinmux = <((((('G') - 'A') & 0xFU) << 9U) | (((10) & 0xFU) << 5U) | (((0xc) & 0x1FU) << 0U))>;
    bias-pull-up;
    slew-rate = "very-high-speed";
   };
   /omit-if-no-ref/ fmc_ne4_pg12: fmc_ne4_pg12 {
    pinmux = <((((('G') - 'A') & 0xFU) << 9U) | (((12) & 0xFU) << 5U) | (((0xc) & 0x1FU) << 0U))>;
    bias-pull-up;
    slew-rate = "very-high-speed";
   };
   /omit-if-no-ref/ fmc_a24_pg13: fmc_a24_pg13 {
    pinmux = <((((('G') - 'A') & 0xFU) << 9U) | (((13) & 0xFU) << 5U) | (((0xc) & 0x1FU) << 0U))>;
    bias-pull-up;
    slew-rate = "very-high-speed";
   };
   /omit-if-no-ref/ fmc_a25_pg14: fmc_a25_pg14 {
    pinmux = <((((('G') - 'A') & 0xFU) << 9U) | (((14) & 0xFU) << 5U) | (((0xc) & 0x1FU) << 0U))>;
    bias-pull-up;
    slew-rate = "very-high-speed";
   };
   /omit-if-no-ref/ fmc_sdncas_pg15: fmc_sdncas_pg15 {
    pinmux = <((((('G') - 'A') & 0xFU) << 9U) | (((15) & 0xFU) << 5U) | (((0xc) & 0x1FU) << 0U))>;
    bias-pull-up;
    slew-rate = "very-high-speed";
   };
   /omit-if-no-ref/ i2c1_scl_pb6: i2c1_scl_pb6 {
    pinmux = <((((('B') - 'A') & 0xFU) << 9U) | (((6) & 0xFU) << 5U) | (((0x4) & 0x1FU) << 0U))>;
    bias-pull-up;
    drive-open-drain;
   };
   /omit-if-no-ref/ i2c1_scl_pb8: i2c1_scl_pb8 {
    pinmux = <((((('B') - 'A') & 0xFU) << 9U) | (((8) & 0xFU) << 5U) | (((0x4) & 0x1FU) << 0U))>;
    bias-pull-up;
    drive-open-drain;
   };
   /omit-if-no-ref/ i2c2_scl_pb10: i2c2_scl_pb10 {
    pinmux = <((((('B') - 'A') & 0xFU) << 9U) | (((10) & 0xFU) << 5U) | (((0x4) & 0x1FU) << 0U))>;
    bias-pull-up;
    drive-open-drain;
   };
   /omit-if-no-ref/ i2c2_scl_pf1: i2c2_scl_pf1 {
    pinmux = <((((('F') - 'A') & 0xFU) << 9U) | (((1) & 0xFU) << 5U) | (((0x4) & 0x1FU) << 0U))>;
    bias-pull-up;
    drive-open-drain;
   };
   /omit-if-no-ref/ i2c3_scl_pa8: i2c3_scl_pa8 {
    pinmux = <((((('A') - 'A') & 0xFU) << 9U) | (((8) & 0xFU) << 5U) | (((0x4) & 0x1FU) << 0U))>;
    bias-pull-up;
    drive-open-drain;
   };
   /omit-if-no-ref/ i2c4_scl_pb6: i2c4_scl_pb6 {
    pinmux = <((((('B') - 'A') & 0xFU) << 9U) | (((6) & 0xFU) << 5U) | (((0xb) & 0x1FU) << 0U))>;
    bias-pull-up;
    drive-open-drain;
   };
   /omit-if-no-ref/ i2c4_scl_pb8: i2c4_scl_pb8 {
    pinmux = <((((('B') - 'A') & 0xFU) << 9U) | (((8) & 0xFU) << 5U) | (((0x1) & 0x1FU) << 0U))>;
    bias-pull-up;
    drive-open-drain;
   };
   /omit-if-no-ref/ i2c4_scl_pd12: i2c4_scl_pd12 {
    pinmux = <((((('D') - 'A') & 0xFU) << 9U) | (((12) & 0xFU) << 5U) | (((0x4) & 0x1FU) << 0U))>;
    bias-pull-up;
    drive-open-drain;
   };
   /omit-if-no-ref/ i2c4_scl_pf14: i2c4_scl_pf14 {
    pinmux = <((((('F') - 'A') & 0xFU) << 9U) | (((14) & 0xFU) << 5U) | (((0x4) & 0x1FU) << 0U))>;
    bias-pull-up;
    drive-open-drain;
   };
   /omit-if-no-ref/ i2c1_sda_pb7: i2c1_sda_pb7 {
    pinmux = <((((('B') - 'A') & 0xFU) << 9U) | (((7) & 0xFU) << 5U) | (((0x4) & 0x1FU) << 0U))>;
    bias-pull-up;
    drive-open-drain;
   };
   /omit-if-no-ref/ i2c1_sda_pb9: i2c1_sda_pb9 {
    pinmux = <((((('B') - 'A') & 0xFU) << 9U) | (((9) & 0xFU) << 5U) | (((0x4) & 0x1FU) << 0U))>;
    bias-pull-up;
    drive-open-drain;
   };
   /omit-if-no-ref/ i2c2_sda_pb11: i2c2_sda_pb11 {
    pinmux = <((((('B') - 'A') & 0xFU) << 9U) | (((11) & 0xFU) << 5U) | (((0x4) & 0x1FU) << 0U))>;
    bias-pull-up;
    drive-open-drain;
   };
   /omit-if-no-ref/ i2c2_sda_pf0: i2c2_sda_pf0 {
    pinmux = <((((('F') - 'A') & 0xFU) << 9U) | (((0) & 0xFU) << 5U) | (((0x4) & 0x1FU) << 0U))>;
    bias-pull-up;
    drive-open-drain;
   };
   /omit-if-no-ref/ i2c3_sda_pc9: i2c3_sda_pc9 {
    pinmux = <((((('C') - 'A') & 0xFU) << 9U) | (((9) & 0xFU) << 5U) | (((0x4) & 0x1FU) << 0U))>;
    bias-pull-up;
    drive-open-drain;
   };
   /omit-if-no-ref/ i2c4_sda_pb7: i2c4_sda_pb7 {
    pinmux = <((((('B') - 'A') & 0xFU) << 9U) | (((7) & 0xFU) << 5U) | (((0xb) & 0x1FU) << 0U))>;
    bias-pull-up;
    drive-open-drain;
   };
   /omit-if-no-ref/ i2c4_sda_pb9: i2c4_sda_pb9 {
    pinmux = <((((('B') - 'A') & 0xFU) << 9U) | (((9) & 0xFU) << 5U) | (((0x1) & 0x1FU) << 0U))>;
    bias-pull-up;
    drive-open-drain;
   };
   /omit-if-no-ref/ i2c4_sda_pd13: i2c4_sda_pd13 {
    pinmux = <((((('D') - 'A') & 0xFU) << 9U) | (((13) & 0xFU) << 5U) | (((0x4) & 0x1FU) << 0U))>;
    bias-pull-up;
    drive-open-drain;
   };
   /omit-if-no-ref/ i2c4_sda_pf15: i2c4_sda_pf15 {
    pinmux = <((((('F') - 'A') & 0xFU) << 9U) | (((15) & 0xFU) << 5U) | (((0x4) & 0x1FU) << 0U))>;
    bias-pull-up;
    drive-open-drain;
   };
   /omit-if-no-ref/ i2s1_ck_pa5: i2s1_ck_pa5 {
    pinmux = <((((('A') - 'A') & 0xFU) << 9U) | (((5) & 0xFU) << 5U) | (((0x5) & 0x1FU) << 0U))>;
    slew-rate = "very-high-speed";
   };
   /omit-if-no-ref/ i2s1_ck_pb3: i2s1_ck_pb3 {
    pinmux = <((((('B') - 'A') & 0xFU) << 9U) | (((3) & 0xFU) << 5U) | (((0x5) & 0x1FU) << 0U))>;
    slew-rate = "very-high-speed";
   };
   /omit-if-no-ref/ i2s1_ck_pg11: i2s1_ck_pg11 {
    pinmux = <((((('G') - 'A') & 0xFU) << 9U) | (((11) & 0xFU) << 5U) | (((0x5) & 0x1FU) << 0U))>;
    slew-rate = "very-high-speed";
   };
   /omit-if-no-ref/ i2s2_ck_pa9: i2s2_ck_pa9 {
    pinmux = <((((('A') - 'A') & 0xFU) << 9U) | (((9) & 0xFU) << 5U) | (((0x5) & 0x1FU) << 0U))>;
    slew-rate = "very-high-speed";
   };
   /omit-if-no-ref/ i2s2_ck_pa12: i2s2_ck_pa12 {
    pinmux = <((((('A') - 'A') & 0xFU) << 9U) | (((12) & 0xFU) << 5U) | (((0x5) & 0x1FU) << 0U))>;
    slew-rate = "very-high-speed";
   };
   /omit-if-no-ref/ i2s2_ck_pb10: i2s2_ck_pb10 {
    pinmux = <((((('B') - 'A') & 0xFU) << 9U) | (((10) & 0xFU) << 5U) | (((0x5) & 0x1FU) << 0U))>;
    slew-rate = "very-high-speed";
   };
   /omit-if-no-ref/ i2s2_ck_pb13: i2s2_ck_pb13 {
    pinmux = <((((('B') - 'A') & 0xFU) << 9U) | (((13) & 0xFU) << 5U) | (((0x5) & 0x1FU) << 0U))>;
    slew-rate = "very-high-speed";
   };
   /omit-if-no-ref/ i2s2_ck_pd3: i2s2_ck_pd3 {
    pinmux = <((((('D') - 'A') & 0xFU) << 9U) | (((3) & 0xFU) << 5U) | (((0x5) & 0x1FU) << 0U))>;
    slew-rate = "very-high-speed";
   };
   /omit-if-no-ref/ i2s3_ck_pb3: i2s3_ck_pb3 {
    pinmux = <((((('B') - 'A') & 0xFU) << 9U) | (((3) & 0xFU) << 5U) | (((0x6) & 0x1FU) << 0U))>;
    slew-rate = "very-high-speed";
   };
   /omit-if-no-ref/ i2s3_ck_pc10: i2s3_ck_pc10 {
    pinmux = <((((('C') - 'A') & 0xFU) << 9U) | (((10) & 0xFU) << 5U) | (((0x6) & 0x1FU) << 0U))>;
    slew-rate = "very-high-speed";
   };
   /omit-if-no-ref/ i2s1_mck_pc4: i2s1_mck_pc4 {
    pinmux = <((((('C') - 'A') & 0xFU) << 9U) | (((4) & 0xFU) << 5U) | (((0x5) & 0x1FU) << 0U))>;
    slew-rate = "very-high-speed";
   };
   /omit-if-no-ref/ i2s2_mck_pc6: i2s2_mck_pc6 {
    pinmux = <((((('C') - 'A') & 0xFU) << 9U) | (((6) & 0xFU) << 5U) | (((0x5) & 0x1FU) << 0U))>;
    slew-rate = "very-high-speed";
   };
   /omit-if-no-ref/ i2s3_mck_pc7: i2s3_mck_pc7 {
    pinmux = <((((('C') - 'A') & 0xFU) << 9U) | (((7) & 0xFU) << 5U) | (((0x6) & 0x1FU) << 0U))>;
    slew-rate = "very-high-speed";
   };
   /omit-if-no-ref/ i2s1_sd_pa7: i2s1_sd_pa7 {
    pinmux = <((((('A') - 'A') & 0xFU) << 9U) | (((7) & 0xFU) << 5U) | (((0x5) & 0x1FU) << 0U))>;
   };
   /omit-if-no-ref/ i2s1_sd_pb5: i2s1_sd_pb5 {
    pinmux = <((((('B') - 'A') & 0xFU) << 9U) | (((5) & 0xFU) << 5U) | (((0x5) & 0x1FU) << 0U))>;
   };
   /omit-if-no-ref/ i2s1_sd_pd7: i2s1_sd_pd7 {
    pinmux = <((((('D') - 'A') & 0xFU) << 9U) | (((7) & 0xFU) << 5U) | (((0x5) & 0x1FU) << 0U))>;
   };
   /omit-if-no-ref/ i2s2_sd_pb15: i2s2_sd_pb15 {
    pinmux = <((((('B') - 'A') & 0xFU) << 9U) | (((15) & 0xFU) << 5U) | (((0x5) & 0x1FU) << 0U))>;
   };
   /omit-if-no-ref/ i2s2_sd_pc1: i2s2_sd_pc1 {
    pinmux = <((((('C') - 'A') & 0xFU) << 9U) | (((1) & 0xFU) << 5U) | (((0x5) & 0x1FU) << 0U))>;
   };
   /omit-if-no-ref/ i2s2_sd_pc3: i2s2_sd_pc3 {
    pinmux = <((((('C') - 'A') & 0xFU) << 9U) | (((3) & 0xFU) << 5U) | (((0x5) & 0x1FU) << 0U))>;
   };
   /omit-if-no-ref/ i2s3_sd_pb2: i2s3_sd_pb2 {
    pinmux = <((((('B') - 'A') & 0xFU) << 9U) | (((2) & 0xFU) << 5U) | (((0x7) & 0x1FU) << 0U))>;
   };
   /omit-if-no-ref/ i2s3_sd_pb5: i2s3_sd_pb5 {
    pinmux = <((((('B') - 'A') & 0xFU) << 9U) | (((5) & 0xFU) << 5U) | (((0x6) & 0x1FU) << 0U))>;
   };
   /omit-if-no-ref/ i2s3_sd_pc12: i2s3_sd_pc12 {
    pinmux = <((((('C') - 'A') & 0xFU) << 9U) | (((12) & 0xFU) << 5U) | (((0x6) & 0x1FU) << 0U))>;
   };
   /omit-if-no-ref/ i2s3_sd_pd6: i2s3_sd_pd6 {
    pinmux = <((((('D') - 'A') & 0xFU) << 9U) | (((6) & 0xFU) << 5U) | (((0x5) & 0x1FU) << 0U))>;
   };
   /omit-if-no-ref/ i2s1_ws_pa4: i2s1_ws_pa4 {
    pinmux = <((((('A') - 'A') & 0xFU) << 9U) | (((4) & 0xFU) << 5U) | (((0x5) & 0x1FU) << 0U))>;
   };
   /omit-if-no-ref/ i2s1_ws_pa15: i2s1_ws_pa15 {
    pinmux = <((((('A') - 'A') & 0xFU) << 9U) | (((15) & 0xFU) << 5U) | (((0x5) & 0x1FU) << 0U))>;
   };
   /omit-if-no-ref/ i2s1_ws_pg10: i2s1_ws_pg10 {
    pinmux = <((((('G') - 'A') & 0xFU) << 9U) | (((10) & 0xFU) << 5U) | (((0x5) & 0x1FU) << 0U))>;
   };
   /omit-if-no-ref/ i2s2_ws_pa11: i2s2_ws_pa11 {
    pinmux = <((((('A') - 'A') & 0xFU) << 9U) | (((11) & 0xFU) << 5U) | (((0x5) & 0x1FU) << 0U))>;
   };
   /omit-if-no-ref/ i2s2_ws_pb4: i2s2_ws_pb4 {
    pinmux = <((((('B') - 'A') & 0xFU) << 9U) | (((4) & 0xFU) << 5U) | (((0x7) & 0x1FU) << 0U))>;
   };
   /omit-if-no-ref/ i2s2_ws_pb9: i2s2_ws_pb9 {
    pinmux = <((((('B') - 'A') & 0xFU) << 9U) | (((9) & 0xFU) << 5U) | (((0x5) & 0x1FU) << 0U))>;
   };
   /omit-if-no-ref/ i2s2_ws_pb12: i2s2_ws_pb12 {
    pinmux = <((((('B') - 'A') & 0xFU) << 9U) | (((12) & 0xFU) << 5U) | (((0x5) & 0x1FU) << 0U))>;
   };
   /omit-if-no-ref/ i2s3_ws_pa4: i2s3_ws_pa4 {
    pinmux = <((((('A') - 'A') & 0xFU) << 9U) | (((4) & 0xFU) << 5U) | (((0x6) & 0x1FU) << 0U))>;
   };
   /omit-if-no-ref/ i2s3_ws_pa15: i2s3_ws_pa15 {
    pinmux = <((((('A') - 'A') & 0xFU) << 9U) | (((15) & 0xFU) << 5U) | (((0x6) & 0x1FU) << 0U))>;
   };
   /omit-if-no-ref/ ltdc_r2_pa1: ltdc_r2_pa1 {
    pinmux = <((((('A') - 'A') & 0xFU) << 9U) | (((1) & 0xFU) << 5U) | (((0xe) & 0x1FU) << 0U))>;
   };
   /omit-if-no-ref/ ltdc_r1_pa2: ltdc_r1_pa2 {
    pinmux = <((((('A') - 'A') & 0xFU) << 9U) | (((2) & 0xFU) << 5U) | (((0xe) & 0x1FU) << 0U))>;
   };
   /omit-if-no-ref/ ltdc_b2_pa3: ltdc_b2_pa3 {
    pinmux = <((((('A') - 'A') & 0xFU) << 9U) | (((3) & 0xFU) << 5U) | (((0x9) & 0x1FU) << 0U))>;
   };
   /omit-if-no-ref/ ltdc_b5_pa3: ltdc_b5_pa3 {
    pinmux = <((((('A') - 'A') & 0xFU) << 9U) | (((3) & 0xFU) << 5U) | (((0xe) & 0x1FU) << 0U))>;
   };
   /omit-if-no-ref/ ltdc_vsync_pa4: ltdc_vsync_pa4 {
    pinmux = <((((('A') - 'A') & 0xFU) << 9U) | (((4) & 0xFU) << 5U) | (((0xe) & 0x1FU) << 0U))>;
   };
   /omit-if-no-ref/ ltdc_r4_pa5: ltdc_r4_pa5 {
    pinmux = <((((('A') - 'A') & 0xFU) << 9U) | (((5) & 0xFU) << 5U) | (((0xe) & 0x1FU) << 0U))>;
   };
   /omit-if-no-ref/ ltdc_g2_pa6: ltdc_g2_pa6 {
    pinmux = <((((('A') - 'A') & 0xFU) << 9U) | (((6) & 0xFU) << 5U) | (((0xe) & 0x1FU) << 0U))>;
   };
   /omit-if-no-ref/ ltdc_b3_pa8: ltdc_b3_pa8 {
    pinmux = <((((('A') - 'A') & 0xFU) << 9U) | (((8) & 0xFU) << 5U) | (((0xd) & 0x1FU) << 0U))>;
   };
   /omit-if-no-ref/ ltdc_r6_pa8: ltdc_r6_pa8 {
    pinmux = <((((('A') - 'A') & 0xFU) << 9U) | (((8) & 0xFU) << 5U) | (((0xe) & 0x1FU) << 0U))>;
   };
   /omit-if-no-ref/ ltdc_r5_pa9: ltdc_r5_pa9 {
    pinmux = <((((('A') - 'A') & 0xFU) << 9U) | (((9) & 0xFU) << 5U) | (((0xe) & 0x1FU) << 0U))>;
   };
   /omit-if-no-ref/ ltdc_b1_pa10: ltdc_b1_pa10 {
    pinmux = <((((('A') - 'A') & 0xFU) << 9U) | (((10) & 0xFU) << 5U) | (((0xe) & 0x1FU) << 0U))>;
   };
   /omit-if-no-ref/ ltdc_b4_pa10: ltdc_b4_pa10 {
    pinmux = <((((('A') - 'A') & 0xFU) << 9U) | (((10) & 0xFU) << 5U) | (((0x9) & 0x1FU) << 0U))>;
   };
   /omit-if-no-ref/ ltdc_r4_pa11: ltdc_r4_pa11 {
    pinmux = <((((('A') - 'A') & 0xFU) << 9U) | (((11) & 0xFU) << 5U) | (((0xe) & 0x1FU) << 0U))>;
   };
   /omit-if-no-ref/ ltdc_r5_pa12: ltdc_r5_pa12 {
    pinmux = <((((('A') - 'A') & 0xFU) << 9U) | (((12) & 0xFU) << 5U) | (((0xe) & 0x1FU) << 0U))>;
   };
   /omit-if-no-ref/ ltdc_g1_pb0: ltdc_g1_pb0 {
    pinmux = <((((('B') - 'A') & 0xFU) << 9U) | (((0) & 0xFU) << 5U) | (((0xe) & 0x1FU) << 0U))>;
   };
   /omit-if-no-ref/ ltdc_r3_pb0: ltdc_r3_pb0 {
    pinmux = <((((('B') - 'A') & 0xFU) << 9U) | (((0) & 0xFU) << 5U) | (((0x9) & 0x1FU) << 0U))>;
   };
   /omit-if-no-ref/ ltdc_g0_pb1: ltdc_g0_pb1 {
    pinmux = <((((('B') - 'A') & 0xFU) << 9U) | (((1) & 0xFU) << 5U) | (((0xe) & 0x1FU) << 0U))>;
   };
   /omit-if-no-ref/ ltdc_r6_pb1: ltdc_r6_pb1 {
    pinmux = <((((('B') - 'A') & 0xFU) << 9U) | (((1) & 0xFU) << 5U) | (((0x9) & 0x1FU) << 0U))>;
   };
   /omit-if-no-ref/ ltdc_g7_pb5: ltdc_g7_pb5 {
    pinmux = <((((('B') - 'A') & 0xFU) << 9U) | (((5) & 0xFU) << 5U) | (((0xe) & 0x1FU) << 0U))>;
   };
   /omit-if-no-ref/ ltdc_b6_pb8: ltdc_b6_pb8 {
    pinmux = <((((('B') - 'A') & 0xFU) << 9U) | (((8) & 0xFU) << 5U) | (((0xe) & 0x1FU) << 0U))>;
   };
   /omit-if-no-ref/ ltdc_b7_pb9: ltdc_b7_pb9 {
    pinmux = <((((('B') - 'A') & 0xFU) << 9U) | (((9) & 0xFU) << 5U) | (((0xe) & 0x1FU) << 0U))>;
   };
   /omit-if-no-ref/ ltdc_g4_pb10: ltdc_g4_pb10 {
    pinmux = <((((('B') - 'A') & 0xFU) << 9U) | (((10) & 0xFU) << 5U) | (((0xe) & 0x1FU) << 0U))>;
   };
   /omit-if-no-ref/ ltdc_g5_pb11: ltdc_g5_pb11 {
    pinmux = <((((('B') - 'A') & 0xFU) << 9U) | (((11) & 0xFU) << 5U) | (((0xe) & 0x1FU) << 0U))>;
   };
   /omit-if-no-ref/ ltdc_r5_pc0: ltdc_r5_pc0 {
    pinmux = <((((('C') - 'A') & 0xFU) << 9U) | (((0) & 0xFU) << 5U) | (((0xe) & 0x1FU) << 0U))>;
   };
   /omit-if-no-ref/ ltdc_hsync_pc6: ltdc_hsync_pc6 {
    pinmux = <((((('C') - 'A') & 0xFU) << 9U) | (((6) & 0xFU) << 5U) | (((0xe) & 0x1FU) << 0U))>;
   };
   /omit-if-no-ref/ ltdc_g6_pc7: ltdc_g6_pc7 {
    pinmux = <((((('C') - 'A') & 0xFU) << 9U) | (((7) & 0xFU) << 5U) | (((0xe) & 0x1FU) << 0U))>;
   };
   /omit-if-no-ref/ ltdc_b2_pc9: ltdc_b2_pc9 {
    pinmux = <((((('C') - 'A') & 0xFU) << 9U) | (((9) & 0xFU) << 5U) | (((0xe) & 0x1FU) << 0U))>;
   };
   /omit-if-no-ref/ ltdc_g3_pc9: ltdc_g3_pc9 {
    pinmux = <((((('C') - 'A') & 0xFU) << 9U) | (((9) & 0xFU) << 5U) | (((0xa) & 0x1FU) << 0U))>;
   };
   /omit-if-no-ref/ ltdc_r2_pc10: ltdc_r2_pc10 {
    pinmux = <((((('C') - 'A') & 0xFU) << 9U) | (((10) & 0xFU) << 5U) | (((0xe) & 0x1FU) << 0U))>;
   };
   /omit-if-no-ref/ ltdc_g7_pd3: ltdc_g7_pd3 {
    pinmux = <((((('D') - 'A') & 0xFU) << 9U) | (((3) & 0xFU) << 5U) | (((0xe) & 0x1FU) << 0U))>;
   };
   /omit-if-no-ref/ ltdc_b2_pd6: ltdc_b2_pd6 {
    pinmux = <((((('D') - 'A') & 0xFU) << 9U) | (((6) & 0xFU) << 5U) | (((0xe) & 0x1FU) << 0U))>;
   };
   /omit-if-no-ref/ ltdc_b3_pd10: ltdc_b3_pd10 {
    pinmux = <((((('D') - 'A') & 0xFU) << 9U) | (((10) & 0xFU) << 5U) | (((0xe) & 0x1FU) << 0U))>;
   };
   /omit-if-no-ref/ ltdc_b0_pe4: ltdc_b0_pe4 {
    pinmux = <((((('E') - 'A') & 0xFU) << 9U) | (((4) & 0xFU) << 5U) | (((0xe) & 0x1FU) << 0U))>;
   };
   /omit-if-no-ref/ ltdc_g0_pe5: ltdc_g0_pe5 {
    pinmux = <((((('E') - 'A') & 0xFU) << 9U) | (((5) & 0xFU) << 5U) | (((0xe) & 0x1FU) << 0U))>;
   };
   /omit-if-no-ref/ ltdc_g1_pe6: ltdc_g1_pe6 {
    pinmux = <((((('E') - 'A') & 0xFU) << 9U) | (((6) & 0xFU) << 5U) | (((0xe) & 0x1FU) << 0U))>;
   };
   /omit-if-no-ref/ ltdc_g3_pe11: ltdc_g3_pe11 {
    pinmux = <((((('E') - 'A') & 0xFU) << 9U) | (((11) & 0xFU) << 5U) | (((0xe) & 0x1FU) << 0U))>;
   };
   /omit-if-no-ref/ ltdc_b4_pe12: ltdc_b4_pe12 {
    pinmux = <((((('E') - 'A') & 0xFU) << 9U) | (((12) & 0xFU) << 5U) | (((0xe) & 0x1FU) << 0U))>;
   };
   /omit-if-no-ref/ ltdc_de_pe13: ltdc_de_pe13 {
    pinmux = <((((('E') - 'A') & 0xFU) << 9U) | (((13) & 0xFU) << 5U) | (((0xe) & 0x1FU) << 0U))>;
   };
   /omit-if-no-ref/ ltdc_clk_pe14: ltdc_clk_pe14 {
    pinmux = <((((('E') - 'A') & 0xFU) << 9U) | (((14) & 0xFU) << 5U) | (((0xe) & 0x1FU) << 0U))>;
   };
   /omit-if-no-ref/ ltdc_r7_pe15: ltdc_r7_pe15 {
    pinmux = <((((('E') - 'A') & 0xFU) << 9U) | (((15) & 0xFU) << 5U) | (((0xe) & 0x1FU) << 0U))>;
   };
   /omit-if-no-ref/ ltdc_de_pf10: ltdc_de_pf10 {
    pinmux = <((((('F') - 'A') & 0xFU) << 9U) | (((10) & 0xFU) << 5U) | (((0xe) & 0x1FU) << 0U))>;
   };
   /omit-if-no-ref/ ltdc_r7_pg6: ltdc_r7_pg6 {
    pinmux = <((((('G') - 'A') & 0xFU) << 9U) | (((6) & 0xFU) << 5U) | (((0xe) & 0x1FU) << 0U))>;
   };
   /omit-if-no-ref/ ltdc_clk_pg7: ltdc_clk_pg7 {
    pinmux = <((((('G') - 'A') & 0xFU) << 9U) | (((7) & 0xFU) << 5U) | (((0xe) & 0x1FU) << 0U))>;
   };
   /omit-if-no-ref/ ltdc_g7_pg8: ltdc_g7_pg8 {
    pinmux = <((((('G') - 'A') & 0xFU) << 9U) | (((8) & 0xFU) << 5U) | (((0xe) & 0x1FU) << 0U))>;
   };
   /omit-if-no-ref/ ltdc_b2_pg10: ltdc_b2_pg10 {
    pinmux = <((((('G') - 'A') & 0xFU) << 9U) | (((10) & 0xFU) << 5U) | (((0xe) & 0x1FU) << 0U))>;
   };
   /omit-if-no-ref/ ltdc_g3_pg10: ltdc_g3_pg10 {
    pinmux = <((((('G') - 'A') & 0xFU) << 9U) | (((10) & 0xFU) << 5U) | (((0x9) & 0x1FU) << 0U))>;
   };
   /omit-if-no-ref/ ltdc_b3_pg11: ltdc_b3_pg11 {
    pinmux = <((((('G') - 'A') & 0xFU) << 9U) | (((11) & 0xFU) << 5U) | (((0xe) & 0x1FU) << 0U))>;
   };
   /omit-if-no-ref/ ltdc_b1_pg12: ltdc_b1_pg12 {
    pinmux = <((((('G') - 'A') & 0xFU) << 9U) | (((12) & 0xFU) << 5U) | (((0xe) & 0x1FU) << 0U))>;
   };
   /omit-if-no-ref/ ltdc_b4_pg12: ltdc_b4_pg12 {
    pinmux = <((((('G') - 'A') & 0xFU) << 9U) | (((12) & 0xFU) << 5U) | (((0x9) & 0x1FU) << 0U))>;
   };
   /omit-if-no-ref/ ltdc_r0_pg13: ltdc_r0_pg13 {
    pinmux = <((((('G') - 'A') & 0xFU) << 9U) | (((13) & 0xFU) << 5U) | (((0xe) & 0x1FU) << 0U))>;
   };
   /omit-if-no-ref/ ltdc_b0_pg14: ltdc_b0_pg14 {
    pinmux = <((((('G') - 'A') & 0xFU) << 9U) | (((14) & 0xFU) << 5U) | (((0xe) & 0x1FU) << 0U))>;
   };
   /omit-if-no-ref/ quadspi_bk1_io3_pa1: quadspi_bk1_io3_pa1 {
    pinmux = <((((('A') - 'A') & 0xFU) << 9U) | (((1) & 0xFU) << 5U) | (((0x9) & 0x1FU) << 0U))>;
    slew-rate = "very-high-speed";
   };
   /omit-if-no-ref/ quadspi_clk_pb2: quadspi_clk_pb2 {
    pinmux = <((((('B') - 'A') & 0xFU) << 9U) | (((2) & 0xFU) << 5U) | (((0x9) & 0x1FU) << 0U))>;
    slew-rate = "very-high-speed";
   };
   /omit-if-no-ref/ quadspi_bk1_ncs_pb6: quadspi_bk1_ncs_pb6 {
    pinmux = <((((('B') - 'A') & 0xFU) << 9U) | (((6) & 0xFU) << 5U) | (((0xa) & 0x1FU) << 0U))>;
    slew-rate = "very-high-speed";
   };
   /omit-if-no-ref/ quadspi_bk1_ncs_pb10: quadspi_bk1_ncs_pb10 {
    pinmux = <((((('B') - 'A') & 0xFU) << 9U) | (((10) & 0xFU) << 5U) | (((0x9) & 0x1FU) << 0U))>;
    slew-rate = "very-high-speed";
   };
   /omit-if-no-ref/ quadspi_bk1_io0_pc9: quadspi_bk1_io0_pc9 {
    pinmux = <((((('C') - 'A') & 0xFU) << 9U) | (((9) & 0xFU) << 5U) | (((0x9) & 0x1FU) << 0U))>;
    slew-rate = "very-high-speed";
   };
   /omit-if-no-ref/ quadspi_bk1_io1_pc10: quadspi_bk1_io1_pc10 {
    pinmux = <((((('C') - 'A') & 0xFU) << 9U) | (((10) & 0xFU) << 5U) | (((0x9) & 0x1FU) << 0U))>;
    slew-rate = "very-high-speed";
   };
   /omit-if-no-ref/ quadspi_bk2_ncs_pc11: quadspi_bk2_ncs_pc11 {
    pinmux = <((((('C') - 'A') & 0xFU) << 9U) | (((11) & 0xFU) << 5U) | (((0x9) & 0x1FU) << 0U))>;
    slew-rate = "very-high-speed";
   };
   /omit-if-no-ref/ quadspi_bk1_io0_pd11: quadspi_bk1_io0_pd11 {
    pinmux = <((((('D') - 'A') & 0xFU) << 9U) | (((11) & 0xFU) << 5U) | (((0x9) & 0x1FU) << 0U))>;
    slew-rate = "very-high-speed";
   };
   /omit-if-no-ref/ quadspi_bk1_io1_pd12: quadspi_bk1_io1_pd12 {
    pinmux = <((((('D') - 'A') & 0xFU) << 9U) | (((12) & 0xFU) << 5U) | (((0x9) & 0x1FU) << 0U))>;
    slew-rate = "very-high-speed";
   };
   /omit-if-no-ref/ quadspi_bk1_io3_pd13: quadspi_bk1_io3_pd13 {
    pinmux = <((((('D') - 'A') & 0xFU) << 9U) | (((13) & 0xFU) << 5U) | (((0x9) & 0x1FU) << 0U))>;
    slew-rate = "very-high-speed";
   };
   /omit-if-no-ref/ quadspi_bk1_io2_pe2: quadspi_bk1_io2_pe2 {
    pinmux = <((((('E') - 'A') & 0xFU) << 9U) | (((2) & 0xFU) << 5U) | (((0x9) & 0x1FU) << 0U))>;
    slew-rate = "very-high-speed";
   };
   /omit-if-no-ref/ quadspi_bk2_io0_pe7: quadspi_bk2_io0_pe7 {
    pinmux = <((((('E') - 'A') & 0xFU) << 9U) | (((7) & 0xFU) << 5U) | (((0xa) & 0x1FU) << 0U))>;
    slew-rate = "very-high-speed";
   };
   /omit-if-no-ref/ quadspi_bk2_io1_pe8: quadspi_bk2_io1_pe8 {
    pinmux = <((((('E') - 'A') & 0xFU) << 9U) | (((8) & 0xFU) << 5U) | (((0xa) & 0x1FU) << 0U))>;
    slew-rate = "very-high-speed";
   };
   /omit-if-no-ref/ quadspi_bk2_io2_pe9: quadspi_bk2_io2_pe9 {
    pinmux = <((((('E') - 'A') & 0xFU) << 9U) | (((9) & 0xFU) << 5U) | (((0xa) & 0x1FU) << 0U))>;
    slew-rate = "very-high-speed";
   };
   /omit-if-no-ref/ quadspi_bk2_io3_pe10: quadspi_bk2_io3_pe10 {
    pinmux = <((((('E') - 'A') & 0xFU) << 9U) | (((10) & 0xFU) << 5U) | (((0xa) & 0x1FU) << 0U))>;
    slew-rate = "very-high-speed";
   };
   /omit-if-no-ref/ quadspi_bk1_io3_pf6: quadspi_bk1_io3_pf6 {
    pinmux = <((((('F') - 'A') & 0xFU) << 9U) | (((6) & 0xFU) << 5U) | (((0x9) & 0x1FU) << 0U))>;
    slew-rate = "very-high-speed";
   };
   /omit-if-no-ref/ quadspi_bk1_io2_pf7: quadspi_bk1_io2_pf7 {
    pinmux = <((((('F') - 'A') & 0xFU) << 9U) | (((7) & 0xFU) << 5U) | (((0x9) & 0x1FU) << 0U))>;
    slew-rate = "very-high-speed";
   };
   /omit-if-no-ref/ quadspi_bk1_io0_pf8: quadspi_bk1_io0_pf8 {
    pinmux = <((((('F') - 'A') & 0xFU) << 9U) | (((8) & 0xFU) << 5U) | (((0xa) & 0x1FU) << 0U))>;
    slew-rate = "very-high-speed";
   };
   /omit-if-no-ref/ quadspi_bk1_io1_pf9: quadspi_bk1_io1_pf9 {
    pinmux = <((((('F') - 'A') & 0xFU) << 9U) | (((9) & 0xFU) << 5U) | (((0xa) & 0x1FU) << 0U))>;
    slew-rate = "very-high-speed";
   };
   /omit-if-no-ref/ quadspi_clk_pf10: quadspi_clk_pf10 {
    pinmux = <((((('F') - 'A') & 0xFU) << 9U) | (((10) & 0xFU) << 5U) | (((0x9) & 0x1FU) << 0U))>;
    slew-rate = "very-high-speed";
   };
   /omit-if-no-ref/ quadspi_bk2_io2_pg9: quadspi_bk2_io2_pg9 {
    pinmux = <((((('G') - 'A') & 0xFU) << 9U) | (((9) & 0xFU) << 5U) | (((0x9) & 0x1FU) << 0U))>;
    slew-rate = "very-high-speed";
   };
   /omit-if-no-ref/ quadspi_bk2_io3_pg14: quadspi_bk2_io3_pg14 {
    pinmux = <((((('G') - 'A') & 0xFU) << 9U) | (((14) & 0xFU) << 5U) | (((0x9) & 0x1FU) << 0U))>;
    slew-rate = "very-high-speed";
   };
   /omit-if-no-ref/ sdmmc1_d4_pb8: sdmmc1_d4_pb8 {
    pinmux = <((((('B') - 'A') & 0xFU) << 9U) | (((8) & 0xFU) << 5U) | (((0xc) & 0x1FU) << 0U))>;
    bias-pull-up;
    slew-rate = "very-high-speed";
   };
   /omit-if-no-ref/ sdmmc1_d5_pb9: sdmmc1_d5_pb9 {
    pinmux = <((((('B') - 'A') & 0xFU) << 9U) | (((9) & 0xFU) << 5U) | (((0xc) & 0x1FU) << 0U))>;
    bias-pull-up;
    slew-rate = "very-high-speed";
   };
   /omit-if-no-ref/ sdmmc1_d6_pc6: sdmmc1_d6_pc6 {
    pinmux = <((((('C') - 'A') & 0xFU) << 9U) | (((6) & 0xFU) << 5U) | (((0xc) & 0x1FU) << 0U))>;
    bias-pull-up;
    slew-rate = "very-high-speed";
   };
   /omit-if-no-ref/ sdmmc1_d7_pc7: sdmmc1_d7_pc7 {
    pinmux = <((((('C') - 'A') & 0xFU) << 9U) | (((7) & 0xFU) << 5U) | (((0xc) & 0x1FU) << 0U))>;
    bias-pull-up;
    slew-rate = "very-high-speed";
   };
   /omit-if-no-ref/ sdmmc1_d0_pc8: sdmmc1_d0_pc8 {
    pinmux = <((((('C') - 'A') & 0xFU) << 9U) | (((8) & 0xFU) << 5U) | (((0xc) & 0x1FU) << 0U))>;
    bias-pull-up;
    slew-rate = "very-high-speed";
   };
   /omit-if-no-ref/ sdmmc1_d1_pc9: sdmmc1_d1_pc9 {
    pinmux = <((((('C') - 'A') & 0xFU) << 9U) | (((9) & 0xFU) << 5U) | (((0xc) & 0x1FU) << 0U))>;
    bias-pull-up;
    slew-rate = "very-high-speed";
   };
   /omit-if-no-ref/ sdmmc1_d2_pc10: sdmmc1_d2_pc10 {
    pinmux = <((((('C') - 'A') & 0xFU) << 9U) | (((10) & 0xFU) << 5U) | (((0xc) & 0x1FU) << 0U))>;
    bias-pull-up;
    slew-rate = "very-high-speed";
   };
   /omit-if-no-ref/ sdmmc1_d3_pc11: sdmmc1_d3_pc11 {
    pinmux = <((((('C') - 'A') & 0xFU) << 9U) | (((11) & 0xFU) << 5U) | (((0xc) & 0x1FU) << 0U))>;
    bias-pull-up;
    slew-rate = "very-high-speed";
   };
   /omit-if-no-ref/ sdmmc1_ck_pc12: sdmmc1_ck_pc12 {
    pinmux = <((((('C') - 'A') & 0xFU) << 9U) | (((12) & 0xFU) << 5U) | (((0xc) & 0x1FU) << 0U))>;
    bias-pull-up;
    slew-rate = "very-high-speed";
   };
   /omit-if-no-ref/ sdmmc1_cmd_pd2: sdmmc1_cmd_pd2 {
    pinmux = <((((('D') - 'A') & 0xFU) << 9U) | (((2) & 0xFU) << 5U) | (((0xc) & 0x1FU) << 0U))>;
    bias-pull-up;
    slew-rate = "very-high-speed";
   };
   /omit-if-no-ref/ sdmmc2_d2_pb3: sdmmc2_d2_pb3 {
    pinmux = <((((('B') - 'A') & 0xFU) << 9U) | (((3) & 0xFU) << 5U) | (((0xa) & 0x1FU) << 0U))>;
    bias-pull-up;
    slew-rate = "very-high-speed";
   };
   /omit-if-no-ref/ sdmmc2_d3_pb4: sdmmc2_d3_pb4 {
    pinmux = <((((('B') - 'A') & 0xFU) << 9U) | (((4) & 0xFU) << 5U) | (((0xa) & 0x1FU) << 0U))>;
    bias-pull-up;
    slew-rate = "very-high-speed";
   };
   /omit-if-no-ref/ sdmmc2_d4_pb8: sdmmc2_d4_pb8 {
    pinmux = <((((('B') - 'A') & 0xFU) << 9U) | (((8) & 0xFU) << 5U) | (((0xa) & 0x1FU) << 0U))>;
    bias-pull-up;
    slew-rate = "very-high-speed";
   };
   /omit-if-no-ref/ sdmmc2_d5_pb9: sdmmc2_d5_pb9 {
    pinmux = <((((('B') - 'A') & 0xFU) << 9U) | (((9) & 0xFU) << 5U) | (((0xa) & 0x1FU) << 0U))>;
    bias-pull-up;
    slew-rate = "very-high-speed";
   };
   /omit-if-no-ref/ sdmmc2_d0_pb14: sdmmc2_d0_pb14 {
    pinmux = <((((('B') - 'A') & 0xFU) << 9U) | (((14) & 0xFU) << 5U) | (((0xa) & 0x1FU) << 0U))>;
    bias-pull-up;
    slew-rate = "very-high-speed";
   };
   /omit-if-no-ref/ sdmmc2_d1_pb15: sdmmc2_d1_pb15 {
    pinmux = <((((('B') - 'A') & 0xFU) << 9U) | (((15) & 0xFU) << 5U) | (((0xa) & 0x1FU) << 0U))>;
    bias-pull-up;
    slew-rate = "very-high-speed";
   };
   /omit-if-no-ref/ sdmmc2_d6_pc6: sdmmc2_d6_pc6 {
    pinmux = <((((('C') - 'A') & 0xFU) << 9U) | (((6) & 0xFU) << 5U) | (((0xa) & 0x1FU) << 0U))>;
    bias-pull-up;
    slew-rate = "very-high-speed";
   };
   /omit-if-no-ref/ sdmmc2_d7_pc7: sdmmc2_d7_pc7 {
    pinmux = <((((('C') - 'A') & 0xFU) << 9U) | (((7) & 0xFU) << 5U) | (((0xa) & 0x1FU) << 0U))>;
    bias-pull-up;
    slew-rate = "very-high-speed";
   };
   /omit-if-no-ref/ sdmmc2_ck_pd6: sdmmc2_ck_pd6 {
    pinmux = <((((('D') - 'A') & 0xFU) << 9U) | (((6) & 0xFU) << 5U) | (((0xb) & 0x1FU) << 0U))>;
    bias-pull-up;
    slew-rate = "very-high-speed";
   };
   /omit-if-no-ref/ sdmmc2_cmd_pd7: sdmmc2_cmd_pd7 {
    pinmux = <((((('D') - 'A') & 0xFU) << 9U) | (((7) & 0xFU) << 5U) | (((0xb) & 0x1FU) << 0U))>;
    bias-pull-up;
    slew-rate = "very-high-speed";
   };
   /omit-if-no-ref/ sdmmc2_d0_pg9: sdmmc2_d0_pg9 {
    pinmux = <((((('G') - 'A') & 0xFU) << 9U) | (((9) & 0xFU) << 5U) | (((0xb) & 0x1FU) << 0U))>;
    bias-pull-up;
    slew-rate = "very-high-speed";
   };
   /omit-if-no-ref/ sdmmc2_d1_pg10: sdmmc2_d1_pg10 {
    pinmux = <((((('G') - 'A') & 0xFU) << 9U) | (((10) & 0xFU) << 5U) | (((0xb) & 0x1FU) << 0U))>;
    bias-pull-up;
    slew-rate = "very-high-speed";
   };
   /omit-if-no-ref/ sdmmc2_d2_pg11: sdmmc2_d2_pg11 {
    pinmux = <((((('G') - 'A') & 0xFU) << 9U) | (((11) & 0xFU) << 5U) | (((0xa) & 0x1FU) << 0U))>;
    bias-pull-up;
    slew-rate = "very-high-speed";
   };
   /omit-if-no-ref/ sdmmc2_d3_pg12: sdmmc2_d3_pg12 {
    pinmux = <((((('G') - 'A') & 0xFU) << 9U) | (((12) & 0xFU) << 5U) | (((0xb) & 0x1FU) << 0U))>;
    bias-pull-up;
    slew-rate = "very-high-speed";
   };
   /omit-if-no-ref/ spi1_miso_pa6: spi1_miso_pa6 {
    pinmux = <((((('A') - 'A') & 0xFU) << 9U) | (((6) & 0xFU) << 5U) | (((0x5) & 0x1FU) << 0U))>;
    bias-pull-down;
   };
   /omit-if-no-ref/ spi1_miso_pb4: spi1_miso_pb4 {
    pinmux = <((((('B') - 'A') & 0xFU) << 9U) | (((4) & 0xFU) << 5U) | (((0x5) & 0x1FU) << 0U))>;
    bias-pull-down;
   };
   /omit-if-no-ref/ spi1_miso_pg9: spi1_miso_pg9 {
    pinmux = <((((('G') - 'A') & 0xFU) << 9U) | (((9) & 0xFU) << 5U) | (((0x5) & 0x1FU) << 0U))>;
    bias-pull-down;
   };
   /omit-if-no-ref/ spi2_miso_pb14: spi2_miso_pb14 {
    pinmux = <((((('B') - 'A') & 0xFU) << 9U) | (((14) & 0xFU) << 5U) | (((0x5) & 0x1FU) << 0U))>;
    bias-pull-down;
   };
   /omit-if-no-ref/ spi2_miso_pc2: spi2_miso_pc2 {
    pinmux = <((((('C') - 'A') & 0xFU) << 9U) | (((2) & 0xFU) << 5U) | (((0x5) & 0x1FU) << 0U))>;
    bias-pull-down;
   };
   /omit-if-no-ref/ spi3_miso_pb4: spi3_miso_pb4 {
    pinmux = <((((('B') - 'A') & 0xFU) << 9U) | (((4) & 0xFU) << 5U) | (((0x6) & 0x1FU) << 0U))>;
    bias-pull-down;
   };
   /omit-if-no-ref/ spi3_miso_pc11: spi3_miso_pc11 {
    pinmux = <((((('C') - 'A') & 0xFU) << 9U) | (((11) & 0xFU) << 5U) | (((0x6) & 0x1FU) << 0U))>;
    bias-pull-down;
   };
   /omit-if-no-ref/ spi4_miso_pe5: spi4_miso_pe5 {
    pinmux = <((((('E') - 'A') & 0xFU) << 9U) | (((5) & 0xFU) << 5U) | (((0x5) & 0x1FU) << 0U))>;
    bias-pull-down;
   };
   /omit-if-no-ref/ spi4_miso_pe13: spi4_miso_pe13 {
    pinmux = <((((('E') - 'A') & 0xFU) << 9U) | (((13) & 0xFU) << 5U) | (((0x5) & 0x1FU) << 0U))>;
    bias-pull-down;
   };
   /omit-if-no-ref/ spi5_miso_pf8: spi5_miso_pf8 {
    pinmux = <((((('F') - 'A') & 0xFU) << 9U) | (((8) & 0xFU) << 5U) | (((0x5) & 0x1FU) << 0U))>;
    bias-pull-down;
   };
   /omit-if-no-ref/ spi6_miso_pa6: spi6_miso_pa6 {
    pinmux = <((((('A') - 'A') & 0xFU) << 9U) | (((6) & 0xFU) << 5U) | (((0x8) & 0x1FU) << 0U))>;
    bias-pull-down;
   };
   /omit-if-no-ref/ spi6_miso_pb4: spi6_miso_pb4 {
    pinmux = <((((('B') - 'A') & 0xFU) << 9U) | (((4) & 0xFU) << 5U) | (((0x8) & 0x1FU) << 0U))>;
    bias-pull-down;
   };
   /omit-if-no-ref/ spi6_miso_pg12: spi6_miso_pg12 {
    pinmux = <((((('G') - 'A') & 0xFU) << 9U) | (((12) & 0xFU) << 5U) | (((0x5) & 0x1FU) << 0U))>;
    bias-pull-down;
   };
   /omit-if-no-ref/ spi1_mosi_pa7: spi1_mosi_pa7 {
    pinmux = <((((('A') - 'A') & 0xFU) << 9U) | (((7) & 0xFU) << 5U) | (((0x5) & 0x1FU) << 0U))>;
    bias-pull-down;
   };
   /omit-if-no-ref/ spi1_mosi_pb5: spi1_mosi_pb5 {
    pinmux = <((((('B') - 'A') & 0xFU) << 9U) | (((5) & 0xFU) << 5U) | (((0x5) & 0x1FU) << 0U))>;
    bias-pull-down;
   };
   /omit-if-no-ref/ spi1_mosi_pd7: spi1_mosi_pd7 {
    pinmux = <((((('D') - 'A') & 0xFU) << 9U) | (((7) & 0xFU) << 5U) | (((0x5) & 0x1FU) << 0U))>;
    bias-pull-down;
   };
   /omit-if-no-ref/ spi2_mosi_pb15: spi2_mosi_pb15 {
    pinmux = <((((('B') - 'A') & 0xFU) << 9U) | (((15) & 0xFU) << 5U) | (((0x5) & 0x1FU) << 0U))>;
    bias-pull-down;
   };
   /omit-if-no-ref/ spi2_mosi_pc1: spi2_mosi_pc1 {
    pinmux = <((((('C') - 'A') & 0xFU) << 9U) | (((1) & 0xFU) << 5U) | (((0x5) & 0x1FU) << 0U))>;
    bias-pull-down;
   };
   /omit-if-no-ref/ spi2_mosi_pc3: spi2_mosi_pc3 {
    pinmux = <((((('C') - 'A') & 0xFU) << 9U) | (((3) & 0xFU) << 5U) | (((0x5) & 0x1FU) << 0U))>;
    bias-pull-down;
   };
   /omit-if-no-ref/ spi3_mosi_pb2: spi3_mosi_pb2 {
    pinmux = <((((('B') - 'A') & 0xFU) << 9U) | (((2) & 0xFU) << 5U) | (((0x7) & 0x1FU) << 0U))>;
    bias-pull-down;
   };
   /omit-if-no-ref/ spi3_mosi_pb5: spi3_mosi_pb5 {
    pinmux = <((((('B') - 'A') & 0xFU) << 9U) | (((5) & 0xFU) << 5U) | (((0x6) & 0x1FU) << 0U))>;
    bias-pull-down;
   };
   /omit-if-no-ref/ spi3_mosi_pc12: spi3_mosi_pc12 {
    pinmux = <((((('C') - 'A') & 0xFU) << 9U) | (((12) & 0xFU) << 5U) | (((0x6) & 0x1FU) << 0U))>;
    bias-pull-down;
   };
   /omit-if-no-ref/ spi3_mosi_pd6: spi3_mosi_pd6 {
    pinmux = <((((('D') - 'A') & 0xFU) << 9U) | (((6) & 0xFU) << 5U) | (((0x5) & 0x1FU) << 0U))>;
    bias-pull-down;
   };
   /omit-if-no-ref/ spi4_mosi_pe6: spi4_mosi_pe6 {
    pinmux = <((((('E') - 'A') & 0xFU) << 9U) | (((6) & 0xFU) << 5U) | (((0x5) & 0x1FU) << 0U))>;
    bias-pull-down;
   };
   /omit-if-no-ref/ spi4_mosi_pe14: spi4_mosi_pe14 {
    pinmux = <((((('E') - 'A') & 0xFU) << 9U) | (((14) & 0xFU) << 5U) | (((0x5) & 0x1FU) << 0U))>;
    bias-pull-down;
   };
   /omit-if-no-ref/ spi5_mosi_pf9: spi5_mosi_pf9 {
    pinmux = <((((('F') - 'A') & 0xFU) << 9U) | (((9) & 0xFU) << 5U) | (((0x5) & 0x1FU) << 0U))>;
    bias-pull-down;
   };
   /omit-if-no-ref/ spi5_mosi_pf11: spi5_mosi_pf11 {
    pinmux = <((((('F') - 'A') & 0xFU) << 9U) | (((11) & 0xFU) << 5U) | (((0x5) & 0x1FU) << 0U))>;
    bias-pull-down;
   };
   /omit-if-no-ref/ spi6_mosi_pa7: spi6_mosi_pa7 {
    pinmux = <((((('A') - 'A') & 0xFU) << 9U) | (((7) & 0xFU) << 5U) | (((0x8) & 0x1FU) << 0U))>;
    bias-pull-down;
   };
   /omit-if-no-ref/ spi6_mosi_pb5: spi6_mosi_pb5 {
    pinmux = <((((('B') - 'A') & 0xFU) << 9U) | (((5) & 0xFU) << 5U) | (((0x8) & 0x1FU) << 0U))>;
    bias-pull-down;
   };
   /omit-if-no-ref/ spi6_mosi_pg14: spi6_mosi_pg14 {
    pinmux = <((((('G') - 'A') & 0xFU) << 9U) | (((14) & 0xFU) << 5U) | (((0x5) & 0x1FU) << 0U))>;
    bias-pull-down;
   };
   /omit-if-no-ref/ spi1_nss_pa4: spi1_nss_pa4 {
    pinmux = <((((('A') - 'A') & 0xFU) << 9U) | (((4) & 0xFU) << 5U) | (((0x5) & 0x1FU) << 0U))>;
    bias-pull-up;
   };
   /omit-if-no-ref/ spi1_nss_pa15: spi1_nss_pa15 {
    pinmux = <((((('A') - 'A') & 0xFU) << 9U) | (((15) & 0xFU) << 5U) | (((0x5) & 0x1FU) << 0U))>;
    bias-pull-up;
   };
   /omit-if-no-ref/ spi1_nss_pg10: spi1_nss_pg10 {
    pinmux = <((((('G') - 'A') & 0xFU) << 9U) | (((10) & 0xFU) << 5U) | (((0x5) & 0x1FU) << 0U))>;
    bias-pull-up;
   };
   /omit-if-no-ref/ spi2_nss_pa11: spi2_nss_pa11 {
    pinmux = <((((('A') - 'A') & 0xFU) << 9U) | (((11) & 0xFU) << 5U) | (((0x5) & 0x1FU) << 0U))>;
    bias-pull-up;
   };
   /omit-if-no-ref/ spi2_nss_pb4: spi2_nss_pb4 {
    pinmux = <((((('B') - 'A') & 0xFU) << 9U) | (((4) & 0xFU) << 5U) | (((0x7) & 0x1FU) << 0U))>;
    bias-pull-up;
   };
   /omit-if-no-ref/ spi2_nss_pb9: spi2_nss_pb9 {
    pinmux = <((((('B') - 'A') & 0xFU) << 9U) | (((9) & 0xFU) << 5U) | (((0x5) & 0x1FU) << 0U))>;
    bias-pull-up;
   };
   /omit-if-no-ref/ spi2_nss_pb12: spi2_nss_pb12 {
    pinmux = <((((('B') - 'A') & 0xFU) << 9U) | (((12) & 0xFU) << 5U) | (((0x5) & 0x1FU) << 0U))>;
    bias-pull-up;
   };
   /omit-if-no-ref/ spi3_nss_pa4: spi3_nss_pa4 {
    pinmux = <((((('A') - 'A') & 0xFU) << 9U) | (((4) & 0xFU) << 5U) | (((0x6) & 0x1FU) << 0U))>;
    bias-pull-up;
   };
   /omit-if-no-ref/ spi3_nss_pa15: spi3_nss_pa15 {
    pinmux = <((((('A') - 'A') & 0xFU) << 9U) | (((15) & 0xFU) << 5U) | (((0x6) & 0x1FU) << 0U))>;
    bias-pull-up;
   };
   /omit-if-no-ref/ spi4_nss_pe4: spi4_nss_pe4 {
    pinmux = <((((('E') - 'A') & 0xFU) << 9U) | (((4) & 0xFU) << 5U) | (((0x5) & 0x1FU) << 0U))>;
    bias-pull-up;
   };
   /omit-if-no-ref/ spi4_nss_pe11: spi4_nss_pe11 {
    pinmux = <((((('E') - 'A') & 0xFU) << 9U) | (((11) & 0xFU) << 5U) | (((0x5) & 0x1FU) << 0U))>;
    bias-pull-up;
   };
   /omit-if-no-ref/ spi5_nss_pf6: spi5_nss_pf6 {
    pinmux = <((((('F') - 'A') & 0xFU) << 9U) | (((6) & 0xFU) << 5U) | (((0x5) & 0x1FU) << 0U))>;
    bias-pull-up;
   };
   /omit-if-no-ref/ spi6_nss_pa4: spi6_nss_pa4 {
    pinmux = <((((('A') - 'A') & 0xFU) << 9U) | (((4) & 0xFU) << 5U) | (((0x8) & 0x1FU) << 0U))>;
    bias-pull-up;
   };
   /omit-if-no-ref/ spi6_nss_pa15: spi6_nss_pa15 {
    pinmux = <((((('A') - 'A') & 0xFU) << 9U) | (((15) & 0xFU) << 5U) | (((0x7) & 0x1FU) << 0U))>;
    bias-pull-up;
   };
   /omit-if-no-ref/ spi6_nss_pg8: spi6_nss_pg8 {
    pinmux = <((((('G') - 'A') & 0xFU) << 9U) | (((8) & 0xFU) << 5U) | (((0x5) & 0x1FU) << 0U))>;
    bias-pull-up;
   };
   /omit-if-no-ref/ spi1_sck_pa5: spi1_sck_pa5 {
    pinmux = <((((('A') - 'A') & 0xFU) << 9U) | (((5) & 0xFU) << 5U) | (((0x5) & 0x1FU) << 0U))>;
    bias-pull-down;
    slew-rate = "very-high-speed";
   };
   /omit-if-no-ref/ spi1_sck_pb3: spi1_sck_pb3 {
    pinmux = <((((('B') - 'A') & 0xFU) << 9U) | (((3) & 0xFU) << 5U) | (((0x5) & 0x1FU) << 0U))>;
    bias-pull-down;
    slew-rate = "very-high-speed";
   };
   /omit-if-no-ref/ spi1_sck_pg11: spi1_sck_pg11 {
    pinmux = <((((('G') - 'A') & 0xFU) << 9U) | (((11) & 0xFU) << 5U) | (((0x5) & 0x1FU) << 0U))>;
    bias-pull-down;
    slew-rate = "very-high-speed";
   };
   /omit-if-no-ref/ spi2_sck_pa9: spi2_sck_pa9 {
    pinmux = <((((('A') - 'A') & 0xFU) << 9U) | (((9) & 0xFU) << 5U) | (((0x5) & 0x1FU) << 0U))>;
    bias-pull-down;
    slew-rate = "very-high-speed";
   };
   /omit-if-no-ref/ spi2_sck_pa12: spi2_sck_pa12 {
    pinmux = <((((('A') - 'A') & 0xFU) << 9U) | (((12) & 0xFU) << 5U) | (((0x5) & 0x1FU) << 0U))>;
    bias-pull-down;
    slew-rate = "very-high-speed";
   };
   /omit-if-no-ref/ spi2_sck_pb10: spi2_sck_pb10 {
    pinmux = <((((('B') - 'A') & 0xFU) << 9U) | (((10) & 0xFU) << 5U) | (((0x5) & 0x1FU) << 0U))>;
    bias-pull-down;
    slew-rate = "very-high-speed";
   };
   /omit-if-no-ref/ spi2_sck_pb13: spi2_sck_pb13 {
    pinmux = <((((('B') - 'A') & 0xFU) << 9U) | (((13) & 0xFU) << 5U) | (((0x5) & 0x1FU) << 0U))>;
    bias-pull-down;
    slew-rate = "very-high-speed";
   };
   /omit-if-no-ref/ spi2_sck_pd3: spi2_sck_pd3 {
    pinmux = <((((('D') - 'A') & 0xFU) << 9U) | (((3) & 0xFU) << 5U) | (((0x5) & 0x1FU) << 0U))>;
    bias-pull-down;
    slew-rate = "very-high-speed";
   };
   /omit-if-no-ref/ spi3_sck_pb3: spi3_sck_pb3 {
    pinmux = <((((('B') - 'A') & 0xFU) << 9U) | (((3) & 0xFU) << 5U) | (((0x6) & 0x1FU) << 0U))>;
    bias-pull-down;
    slew-rate = "very-high-speed";
   };
   /omit-if-no-ref/ spi3_sck_pc10: spi3_sck_pc10 {
    pinmux = <((((('C') - 'A') & 0xFU) << 9U) | (((10) & 0xFU) << 5U) | (((0x6) & 0x1FU) << 0U))>;
    bias-pull-down;
    slew-rate = "very-high-speed";
   };
   /omit-if-no-ref/ spi4_sck_pe2: spi4_sck_pe2 {
    pinmux = <((((('E') - 'A') & 0xFU) << 9U) | (((2) & 0xFU) << 5U) | (((0x5) & 0x1FU) << 0U))>;
    bias-pull-down;
    slew-rate = "very-high-speed";
   };
   /omit-if-no-ref/ spi4_sck_pe12: spi4_sck_pe12 {
    pinmux = <((((('E') - 'A') & 0xFU) << 9U) | (((12) & 0xFU) << 5U) | (((0x5) & 0x1FU) << 0U))>;
    bias-pull-down;
    slew-rate = "very-high-speed";
   };
   /omit-if-no-ref/ spi5_sck_pf7: spi5_sck_pf7 {
    pinmux = <((((('F') - 'A') & 0xFU) << 9U) | (((7) & 0xFU) << 5U) | (((0x5) & 0x1FU) << 0U))>;
    bias-pull-down;
    slew-rate = "very-high-speed";
   };
   /omit-if-no-ref/ spi6_sck_pa5: spi6_sck_pa5 {
    pinmux = <((((('A') - 'A') & 0xFU) << 9U) | (((5) & 0xFU) << 5U) | (((0x8) & 0x1FU) << 0U))>;
    bias-pull-down;
    slew-rate = "very-high-speed";
   };
   /omit-if-no-ref/ spi6_sck_pb3: spi6_sck_pb3 {
    pinmux = <((((('B') - 'A') & 0xFU) << 9U) | (((3) & 0xFU) << 5U) | (((0x8) & 0x1FU) << 0U))>;
    bias-pull-down;
    slew-rate = "very-high-speed";
   };
   /omit-if-no-ref/ spi6_sck_pg13: spi6_sck_pg13 {
    pinmux = <((((('G') - 'A') & 0xFU) << 9U) | (((13) & 0xFU) << 5U) | (((0x5) & 0x1FU) << 0U))>;
    bias-pull-down;
    slew-rate = "very-high-speed";
   };
   /omit-if-no-ref/ tim1_bkin_pa6: tim1_bkin_pa6 {
    pinmux = <((((('A') - 'A') & 0xFU) << 9U) | (((6) & 0xFU) << 5U) | (((0x1) & 0x1FU) << 0U))>;
   };
   /omit-if-no-ref/ tim1_bkin_pb12: tim1_bkin_pb12 {
    pinmux = <((((('B') - 'A') & 0xFU) << 9U) | (((12) & 0xFU) << 5U) | (((0x1) & 0x1FU) << 0U))>;
   };
   /omit-if-no-ref/ tim1_bkin2_pe6: tim1_bkin2_pe6 {
    pinmux = <((((('E') - 'A') & 0xFU) << 9U) | (((6) & 0xFU) << 5U) | (((0x1) & 0x1FU) << 0U))>;
   };
   /omit-if-no-ref/ tim1_bkin_pe15: tim1_bkin_pe15 {
    pinmux = <((((('E') - 'A') & 0xFU) << 9U) | (((15) & 0xFU) << 5U) | (((0x1) & 0x1FU) << 0U))>;
   };
   /omit-if-no-ref/ tim8_bkin_pa6: tim8_bkin_pa6 {
    pinmux = <((((('A') - 'A') & 0xFU) << 9U) | (((6) & 0xFU) << 5U) | (((0x3) & 0x1FU) << 0U))>;
   };
   /omit-if-no-ref/ tim8_bkin2_pa8: tim8_bkin2_pa8 {
    pinmux = <((((('A') - 'A') & 0xFU) << 9U) | (((8) & 0xFU) << 5U) | (((0x3) & 0x1FU) << 0U))>;
   };
   /omit-if-no-ref/ tim10_ch1_pb8: tim10_ch1_pb8 {
    pinmux = <((((('B') - 'A') & 0xFU) << 9U) | (((8) & 0xFU) << 5U) | (((0x3) & 0x1FU) << 0U))>;
   };
   /omit-if-no-ref/ tim10_ch1_pf6: tim10_ch1_pf6 {
    pinmux = <((((('F') - 'A') & 0xFU) << 9U) | (((6) & 0xFU) << 5U) | (((0x3) & 0x1FU) << 0U))>;
   };
   /omit-if-no-ref/ tim1_ch1n_pa7: tim1_ch1n_pa7 {
    pinmux = <((((('A') - 'A') & 0xFU) << 9U) | (((7) & 0xFU) << 5U) | (((0x1) & 0x1FU) << 0U))>;
   };
   /omit-if-no-ref/ tim1_ch1_pa8: tim1_ch1_pa8 {
    pinmux = <((((('A') - 'A') & 0xFU) << 9U) | (((8) & 0xFU) << 5U) | (((0x1) & 0x1FU) << 0U))>;
   };
   /omit-if-no-ref/ tim1_ch2_pa9: tim1_ch2_pa9 {
    pinmux = <((((('A') - 'A') & 0xFU) << 9U) | (((9) & 0xFU) << 5U) | (((0x1) & 0x1FU) << 0U))>;
   };
   /omit-if-no-ref/ tim1_ch3_pa10: tim1_ch3_pa10 {
    pinmux = <((((('A') - 'A') & 0xFU) << 9U) | (((10) & 0xFU) << 5U) | (((0x1) & 0x1FU) << 0U))>;
   };
   /omit-if-no-ref/ tim1_ch4_pa11: tim1_ch4_pa11 {
    pinmux = <((((('A') - 'A') & 0xFU) << 9U) | (((11) & 0xFU) << 5U) | (((0x1) & 0x1FU) << 0U))>;
   };
   /omit-if-no-ref/ tim1_ch2n_pb0: tim1_ch2n_pb0 {
    pinmux = <((((('B') - 'A') & 0xFU) << 9U) | (((0) & 0xFU) << 5U) | (((0x1) & 0x1FU) << 0U))>;
   };
   /omit-if-no-ref/ tim1_ch3n_pb1: tim1_ch3n_pb1 {
    pinmux = <((((('B') - 'A') & 0xFU) << 9U) | (((1) & 0xFU) << 5U) | (((0x1) & 0x1FU) << 0U))>;
   };
   /omit-if-no-ref/ tim11_ch1_pb9: tim11_ch1_pb9 {
    pinmux = <((((('B') - 'A') & 0xFU) << 9U) | (((9) & 0xFU) << 5U) | (((0x3) & 0x1FU) << 0U))>;
   };
   /omit-if-no-ref/ tim1_ch1n_pb13: tim1_ch1n_pb13 {
    pinmux = <((((('B') - 'A') & 0xFU) << 9U) | (((13) & 0xFU) << 5U) | (((0x1) & 0x1FU) << 0U))>;
   };
   /omit-if-no-ref/ tim1_ch2n_pb14: tim1_ch2n_pb14 {
    pinmux = <((((('B') - 'A') & 0xFU) << 9U) | (((14) & 0xFU) << 5U) | (((0x1) & 0x1FU) << 0U))>;
   };
   /omit-if-no-ref/ tim1_ch3n_pb15: tim1_ch3n_pb15 {
    pinmux = <((((('B') - 'A') & 0xFU) << 9U) | (((15) & 0xFU) << 5U) | (((0x1) & 0x1FU) << 0U))>;
   };
   /omit-if-no-ref/ tim1_ch1n_pe8: tim1_ch1n_pe8 {
    pinmux = <((((('E') - 'A') & 0xFU) << 9U) | (((8) & 0xFU) << 5U) | (((0x1) & 0x1FU) << 0U))>;
   };
   /omit-if-no-ref/ tim1_ch1_pe9: tim1_ch1_pe9 {
    pinmux = <((((('E') - 'A') & 0xFU) << 9U) | (((9) & 0xFU) << 5U) | (((0x1) & 0x1FU) << 0U))>;
   };
   /omit-if-no-ref/ tim1_ch2n_pe10: tim1_ch2n_pe10 {
    pinmux = <((((('E') - 'A') & 0xFU) << 9U) | (((10) & 0xFU) << 5U) | (((0x1) & 0x1FU) << 0U))>;
   };
   /omit-if-no-ref/ tim1_ch2_pe11: tim1_ch2_pe11 {
    pinmux = <((((('E') - 'A') & 0xFU) << 9U) | (((11) & 0xFU) << 5U) | (((0x1) & 0x1FU) << 0U))>;
   };
   /omit-if-no-ref/ tim1_ch3n_pe12: tim1_ch3n_pe12 {
    pinmux = <((((('E') - 'A') & 0xFU) << 9U) | (((12) & 0xFU) << 5U) | (((0x1) & 0x1FU) << 0U))>;
   };
   /omit-if-no-ref/ tim1_ch3_pe13: tim1_ch3_pe13 {
    pinmux = <((((('E') - 'A') & 0xFU) << 9U) | (((13) & 0xFU) << 5U) | (((0x1) & 0x1FU) << 0U))>;
   };
   /omit-if-no-ref/ tim1_ch4_pe14: tim1_ch4_pe14 {
    pinmux = <((((('E') - 'A') & 0xFU) << 9U) | (((14) & 0xFU) << 5U) | (((0x1) & 0x1FU) << 0U))>;
   };
   /omit-if-no-ref/ tim11_ch1_pf7: tim11_ch1_pf7 {
    pinmux = <((((('F') - 'A') & 0xFU) << 9U) | (((7) & 0xFU) << 5U) | (((0x3) & 0x1FU) << 0U))>;
   };
   /omit-if-no-ref/ tim2_ch1_pa0: tim2_ch1_pa0 {
    pinmux = <((((('A') - 'A') & 0xFU) << 9U) | (((0) & 0xFU) << 5U) | (((0x1) & 0x1FU) << 0U))>;
   };
   /omit-if-no-ref/ tim2_ch2_pa1: tim2_ch2_pa1 {
    pinmux = <((((('A') - 'A') & 0xFU) << 9U) | (((1) & 0xFU) << 5U) | (((0x1) & 0x1FU) << 0U))>;
   };
   /omit-if-no-ref/ tim2_ch3_pa2: tim2_ch3_pa2 {
    pinmux = <((((('A') - 'A') & 0xFU) << 9U) | (((2) & 0xFU) << 5U) | (((0x1) & 0x1FU) << 0U))>;
   };
   /omit-if-no-ref/ tim2_ch4_pa3: tim2_ch4_pa3 {
    pinmux = <((((('A') - 'A') & 0xFU) << 9U) | (((3) & 0xFU) << 5U) | (((0x1) & 0x1FU) << 0U))>;
   };
   /omit-if-no-ref/ tim2_ch1_pa5: tim2_ch1_pa5 {
    pinmux = <((((('A') - 'A') & 0xFU) << 9U) | (((5) & 0xFU) << 5U) | (((0x1) & 0x1FU) << 0U))>;
   };
   /omit-if-no-ref/ tim2_ch1_pa15: tim2_ch1_pa15 {
    pinmux = <((((('A') - 'A') & 0xFU) << 9U) | (((15) & 0xFU) << 5U) | (((0x1) & 0x1FU) << 0U))>;
   };
   /omit-if-no-ref/ tim2_ch2_pb3: tim2_ch2_pb3 {
    pinmux = <((((('B') - 'A') & 0xFU) << 9U) | (((3) & 0xFU) << 5U) | (((0x1) & 0x1FU) << 0U))>;
   };
   /omit-if-no-ref/ tim2_ch3_pb10: tim2_ch3_pb10 {
    pinmux = <((((('B') - 'A') & 0xFU) << 9U) | (((10) & 0xFU) << 5U) | (((0x1) & 0x1FU) << 0U))>;
   };
   /omit-if-no-ref/ tim2_ch4_pb11: tim2_ch4_pb11 {
    pinmux = <((((('B') - 'A') & 0xFU) << 9U) | (((11) & 0xFU) << 5U) | (((0x1) & 0x1FU) << 0U))>;
   };
   /omit-if-no-ref/ tim12_ch1_pb14: tim12_ch1_pb14 {
    pinmux = <((((('B') - 'A') & 0xFU) << 9U) | (((14) & 0xFU) << 5U) | (((0x9) & 0x1FU) << 0U))>;
   };
   /omit-if-no-ref/ tim12_ch2_pb15: tim12_ch2_pb15 {
    pinmux = <((((('B') - 'A') & 0xFU) << 9U) | (((15) & 0xFU) << 5U) | (((0x9) & 0x1FU) << 0U))>;
   };
   /omit-if-no-ref/ tim13_ch1_pa6: tim13_ch1_pa6 {
    pinmux = <((((('A') - 'A') & 0xFU) << 9U) | (((6) & 0xFU) << 5U) | (((0x9) & 0x1FU) << 0U))>;
   };
   /omit-if-no-ref/ tim3_ch1_pa6: tim3_ch1_pa6 {
    pinmux = <((((('A') - 'A') & 0xFU) << 9U) | (((6) & 0xFU) << 5U) | (((0x2) & 0x1FU) << 0U))>;
   };
   /omit-if-no-ref/ tim3_ch2_pa7: tim3_ch2_pa7 {
    pinmux = <((((('A') - 'A') & 0xFU) << 9U) | (((7) & 0xFU) << 5U) | (((0x2) & 0x1FU) << 0U))>;
   };
   /omit-if-no-ref/ tim3_ch3_pb0: tim3_ch3_pb0 {
    pinmux = <((((('B') - 'A') & 0xFU) << 9U) | (((0) & 0xFU) << 5U) | (((0x2) & 0x1FU) << 0U))>;
   };
   /omit-if-no-ref/ tim3_ch4_pb1: tim3_ch4_pb1 {
    pinmux = <((((('B') - 'A') & 0xFU) << 9U) | (((1) & 0xFU) << 5U) | (((0x2) & 0x1FU) << 0U))>;
   };
   /omit-if-no-ref/ tim3_ch1_pb4: tim3_ch1_pb4 {
    pinmux = <((((('B') - 'A') & 0xFU) << 9U) | (((4) & 0xFU) << 5U) | (((0x2) & 0x1FU) << 0U))>;
   };
   /omit-if-no-ref/ tim3_ch2_pb5: tim3_ch2_pb5 {
    pinmux = <((((('B') - 'A') & 0xFU) << 9U) | (((5) & 0xFU) << 5U) | (((0x2) & 0x1FU) << 0U))>;
   };
   /omit-if-no-ref/ tim3_ch1_pc6: tim3_ch1_pc6 {
    pinmux = <((((('C') - 'A') & 0xFU) << 9U) | (((6) & 0xFU) << 5U) | (((0x2) & 0x1FU) << 0U))>;
   };
   /omit-if-no-ref/ tim3_ch2_pc7: tim3_ch2_pc7 {
    pinmux = <((((('C') - 'A') & 0xFU) << 9U) | (((7) & 0xFU) << 5U) | (((0x2) & 0x1FU) << 0U))>;
   };
   /omit-if-no-ref/ tim3_ch3_pc8: tim3_ch3_pc8 {
    pinmux = <((((('C') - 'A') & 0xFU) << 9U) | (((8) & 0xFU) << 5U) | (((0x2) & 0x1FU) << 0U))>;
   };
   /omit-if-no-ref/ tim3_ch4_pc9: tim3_ch4_pc9 {
    pinmux = <((((('C') - 'A') & 0xFU) << 9U) | (((9) & 0xFU) << 5U) | (((0x2) & 0x1FU) << 0U))>;
   };
   /omit-if-no-ref/ tim13_ch1_pf8: tim13_ch1_pf8 {
    pinmux = <((((('F') - 'A') & 0xFU) << 9U) | (((8) & 0xFU) << 5U) | (((0x9) & 0x1FU) << 0U))>;
   };
   /omit-if-no-ref/ tim14_ch1_pa7: tim14_ch1_pa7 {
    pinmux = <((((('A') - 'A') & 0xFU) << 9U) | (((7) & 0xFU) << 5U) | (((0x9) & 0x1FU) << 0U))>;
   };
   /omit-if-no-ref/ tim4_ch1_pb6: tim4_ch1_pb6 {
    pinmux = <((((('B') - 'A') & 0xFU) << 9U) | (((6) & 0xFU) << 5U) | (((0x2) & 0x1FU) << 0U))>;
   };
   /omit-if-no-ref/ tim4_ch2_pb7: tim4_ch2_pb7 {
    pinmux = <((((('B') - 'A') & 0xFU) << 9U) | (((7) & 0xFU) << 5U) | (((0x2) & 0x1FU) << 0U))>;
   };
   /omit-if-no-ref/ tim4_ch3_pb8: tim4_ch3_pb8 {
    pinmux = <((((('B') - 'A') & 0xFU) << 9U) | (((8) & 0xFU) << 5U) | (((0x2) & 0x1FU) << 0U))>;
   };
   /omit-if-no-ref/ tim4_ch4_pb9: tim4_ch4_pb9 {
    pinmux = <((((('B') - 'A') & 0xFU) << 9U) | (((9) & 0xFU) << 5U) | (((0x2) & 0x1FU) << 0U))>;
   };
   /omit-if-no-ref/ tim4_ch1_pd12: tim4_ch1_pd12 {
    pinmux = <((((('D') - 'A') & 0xFU) << 9U) | (((12) & 0xFU) << 5U) | (((0x2) & 0x1FU) << 0U))>;
   };
   /omit-if-no-ref/ tim4_ch2_pd13: tim4_ch2_pd13 {
    pinmux = <((((('D') - 'A') & 0xFU) << 9U) | (((13) & 0xFU) << 5U) | (((0x2) & 0x1FU) << 0U))>;
   };
   /omit-if-no-ref/ tim4_ch3_pd14: tim4_ch3_pd14 {
    pinmux = <((((('D') - 'A') & 0xFU) << 9U) | (((14) & 0xFU) << 5U) | (((0x2) & 0x1FU) << 0U))>;
   };
   /omit-if-no-ref/ tim4_ch4_pd15: tim4_ch4_pd15 {
    pinmux = <((((('D') - 'A') & 0xFU) << 9U) | (((15) & 0xFU) << 5U) | (((0x2) & 0x1FU) << 0U))>;
   };
   /omit-if-no-ref/ tim14_ch1_pf9: tim14_ch1_pf9 {
    pinmux = <((((('F') - 'A') & 0xFU) << 9U) | (((9) & 0xFU) << 5U) | (((0x9) & 0x1FU) << 0U))>;
   };
   /omit-if-no-ref/ tim5_ch1_pa0: tim5_ch1_pa0 {
    pinmux = <((((('A') - 'A') & 0xFU) << 9U) | (((0) & 0xFU) << 5U) | (((0x2) & 0x1FU) << 0U))>;
   };
   /omit-if-no-ref/ tim5_ch2_pa1: tim5_ch2_pa1 {
    pinmux = <((((('A') - 'A') & 0xFU) << 9U) | (((1) & 0xFU) << 5U) | (((0x2) & 0x1FU) << 0U))>;
   };
   /omit-if-no-ref/ tim5_ch3_pa2: tim5_ch3_pa2 {
    pinmux = <((((('A') - 'A') & 0xFU) << 9U) | (((2) & 0xFU) << 5U) | (((0x2) & 0x1FU) << 0U))>;
   };
   /omit-if-no-ref/ tim5_ch4_pa3: tim5_ch4_pa3 {
    pinmux = <((((('A') - 'A') & 0xFU) << 9U) | (((3) & 0xFU) << 5U) | (((0x2) & 0x1FU) << 0U))>;
   };
   /omit-if-no-ref/ tim8_ch1n_pa5: tim8_ch1n_pa5 {
    pinmux = <((((('A') - 'A') & 0xFU) << 9U) | (((5) & 0xFU) << 5U) | (((0x3) & 0x1FU) << 0U))>;
   };
   /omit-if-no-ref/ tim8_ch1n_pa7: tim8_ch1n_pa7 {
    pinmux = <((((('A') - 'A') & 0xFU) << 9U) | (((7) & 0xFU) << 5U) | (((0x3) & 0x1FU) << 0U))>;
   };
   /omit-if-no-ref/ tim8_ch2n_pb0: tim8_ch2n_pb0 {
    pinmux = <((((('B') - 'A') & 0xFU) << 9U) | (((0) & 0xFU) << 5U) | (((0x3) & 0x1FU) << 0U))>;
   };
   /omit-if-no-ref/ tim8_ch3n_pb1: tim8_ch3n_pb1 {
    pinmux = <((((('B') - 'A') & 0xFU) << 9U) | (((1) & 0xFU) << 5U) | (((0x3) & 0x1FU) << 0U))>;
   };
   /omit-if-no-ref/ tim8_ch2n_pb14: tim8_ch2n_pb14 {
    pinmux = <((((('B') - 'A') & 0xFU) << 9U) | (((14) & 0xFU) << 5U) | (((0x3) & 0x1FU) << 0U))>;
   };
   /omit-if-no-ref/ tim8_ch3n_pb15: tim8_ch3n_pb15 {
    pinmux = <((((('B') - 'A') & 0xFU) << 9U) | (((15) & 0xFU) << 5U) | (((0x3) & 0x1FU) << 0U))>;
   };
   /omit-if-no-ref/ tim8_ch1_pc6: tim8_ch1_pc6 {
    pinmux = <((((('C') - 'A') & 0xFU) << 9U) | (((6) & 0xFU) << 5U) | (((0x3) & 0x1FU) << 0U))>;
   };
   /omit-if-no-ref/ tim8_ch2_pc7: tim8_ch2_pc7 {
    pinmux = <((((('C') - 'A') & 0xFU) << 9U) | (((7) & 0xFU) << 5U) | (((0x3) & 0x1FU) << 0U))>;
   };
   /omit-if-no-ref/ tim8_ch3_pc8: tim8_ch3_pc8 {
    pinmux = <((((('C') - 'A') & 0xFU) << 9U) | (((8) & 0xFU) << 5U) | (((0x3) & 0x1FU) << 0U))>;
   };
   /omit-if-no-ref/ tim8_ch4_pc9: tim8_ch4_pc9 {
    pinmux = <((((('C') - 'A') & 0xFU) << 9U) | (((9) & 0xFU) << 5U) | (((0x3) & 0x1FU) << 0U))>;
   };
   /omit-if-no-ref/ tim9_ch1_pa2: tim9_ch1_pa2 {
    pinmux = <((((('A') - 'A') & 0xFU) << 9U) | (((2) & 0xFU) << 5U) | (((0x3) & 0x1FU) << 0U))>;
   };
   /omit-if-no-ref/ tim9_ch2_pa3: tim9_ch2_pa3 {
    pinmux = <((((('A') - 'A') & 0xFU) << 9U) | (((3) & 0xFU) << 5U) | (((0x3) & 0x1FU) << 0U))>;
   };
   /omit-if-no-ref/ tim9_ch1_pe5: tim9_ch1_pe5 {
    pinmux = <((((('E') - 'A') & 0xFU) << 9U) | (((5) & 0xFU) << 5U) | (((0x3) & 0x1FU) << 0U))>;
   };
   /omit-if-no-ref/ tim9_ch2_pe6: tim9_ch2_pe6 {
    pinmux = <((((('E') - 'A') & 0xFU) << 9U) | (((6) & 0xFU) << 5U) | (((0x3) & 0x1FU) << 0U))>;
   };
   /omit-if-no-ref/ usart1_cts_pa11: usart1_cts_pa11 {
    pinmux = <((((('A') - 'A') & 0xFU) << 9U) | (((11) & 0xFU) << 5U) | (((0x7) & 0x1FU) << 0U))>;
    bias-pull-up;
    drive-open-drain;
   };
   /omit-if-no-ref/ usart2_cts_pa0: usart2_cts_pa0 {
    pinmux = <((((('A') - 'A') & 0xFU) << 9U) | (((0) & 0xFU) << 5U) | (((0x7) & 0x1FU) << 0U))>;
    bias-pull-up;
    drive-open-drain;
   };
   /omit-if-no-ref/ usart2_cts_pd3: usart2_cts_pd3 {
    pinmux = <((((('D') - 'A') & 0xFU) << 9U) | (((3) & 0xFU) << 5U) | (((0x7) & 0x1FU) << 0U))>;
    bias-pull-up;
    drive-open-drain;
   };
   /omit-if-no-ref/ usart3_cts_pb13: usart3_cts_pb13 {
    pinmux = <((((('B') - 'A') & 0xFU) << 9U) | (((13) & 0xFU) << 5U) | (((0x7) & 0x1FU) << 0U))>;
    bias-pull-up;
    drive-open-drain;
   };
   /omit-if-no-ref/ usart3_cts_pd11: usart3_cts_pd11 {
    pinmux = <((((('D') - 'A') & 0xFU) << 9U) | (((11) & 0xFU) << 5U) | (((0x7) & 0x1FU) << 0U))>;
    bias-pull-up;
    drive-open-drain;
   };
   /omit-if-no-ref/ uart4_cts_pb0: uart4_cts_pb0 {
    pinmux = <((((('B') - 'A') & 0xFU) << 9U) | (((0) & 0xFU) << 5U) | (((0x8) & 0x1FU) << 0U))>;
    bias-pull-up;
    drive-open-drain;
   };
   /omit-if-no-ref/ uart4_cts_pb15: uart4_cts_pb15 {
    pinmux = <((((('B') - 'A') & 0xFU) << 9U) | (((15) & 0xFU) << 5U) | (((0x8) & 0x1FU) << 0U))>;
    bias-pull-up;
    drive-open-drain;
   };
   /omit-if-no-ref/ uart5_cts_pc9: uart5_cts_pc9 {
    pinmux = <((((('C') - 'A') & 0xFU) << 9U) | (((9) & 0xFU) << 5U) | (((0x7) & 0x1FU) << 0U))>;
    bias-pull-up;
    drive-open-drain;
   };
   /omit-if-no-ref/ usart6_cts_pg13: usart6_cts_pg13 {
    pinmux = <((((('G') - 'A') & 0xFU) << 9U) | (((13) & 0xFU) << 5U) | (((0x8) & 0x1FU) << 0U))>;
    bias-pull-up;
    drive-open-drain;
   };
   /omit-if-no-ref/ usart6_cts_pg15: usart6_cts_pg15 {
    pinmux = <((((('G') - 'A') & 0xFU) << 9U) | (((15) & 0xFU) << 5U) | (((0x8) & 0x1FU) << 0U))>;
    bias-pull-up;
    drive-open-drain;
   };
   /omit-if-no-ref/ uart7_cts_pe10: uart7_cts_pe10 {
    pinmux = <((((('E') - 'A') & 0xFU) << 9U) | (((10) & 0xFU) << 5U) | (((0x8) & 0x1FU) << 0U))>;
    bias-pull-up;
    drive-open-drain;
   };
   /omit-if-no-ref/ uart7_cts_pf9: uart7_cts_pf9 {
    pinmux = <((((('F') - 'A') & 0xFU) << 9U) | (((9) & 0xFU) << 5U) | (((0x8) & 0x1FU) << 0U))>;
    bias-pull-up;
    drive-open-drain;
   };
   /omit-if-no-ref/ uart8_cts_pd14: uart8_cts_pd14 {
    pinmux = <((((('D') - 'A') & 0xFU) << 9U) | (((14) & 0xFU) << 5U) | (((0x8) & 0x1FU) << 0U))>;
    bias-pull-up;
    drive-open-drain;
   };
   /omit-if-no-ref/ usart1_de_pa12: usart1_de_pa12 {
    pinmux = <((((('A') - 'A') & 0xFU) << 9U) | (((12) & 0xFU) << 5U) | (((0x7) & 0x1FU) << 0U))>;
    drive-push-pull;
   };
   /omit-if-no-ref/ usart2_de_pa1: usart2_de_pa1 {
    pinmux = <((((('A') - 'A') & 0xFU) << 9U) | (((1) & 0xFU) << 5U) | (((0x7) & 0x1FU) << 0U))>;
    drive-push-pull;
   };
   /omit-if-no-ref/ usart2_de_pd4: usart2_de_pd4 {
    pinmux = <((((('D') - 'A') & 0xFU) << 9U) | (((4) & 0xFU) << 5U) | (((0x7) & 0x1FU) << 0U))>;
    drive-push-pull;
   };
   /omit-if-no-ref/ usart3_de_pb14: usart3_de_pb14 {
    pinmux = <((((('B') - 'A') & 0xFU) << 9U) | (((14) & 0xFU) << 5U) | (((0x7) & 0x1FU) << 0U))>;
    drive-push-pull;
   };
   /omit-if-no-ref/ usart3_de_pd12: usart3_de_pd12 {
    pinmux = <((((('D') - 'A') & 0xFU) << 9U) | (((12) & 0xFU) << 5U) | (((0x7) & 0x1FU) << 0U))>;
    drive-push-pull;
   };
   /omit-if-no-ref/ uart4_de_pa15: uart4_de_pa15 {
    pinmux = <((((('A') - 'A') & 0xFU) << 9U) | (((15) & 0xFU) << 5U) | (((0x8) & 0x1FU) << 0U))>;
    drive-push-pull;
   };
   /omit-if-no-ref/ uart4_de_pb14: uart4_de_pb14 {
    pinmux = <((((('B') - 'A') & 0xFU) << 9U) | (((14) & 0xFU) << 5U) | (((0x8) & 0x1FU) << 0U))>;
    drive-push-pull;
   };
   /omit-if-no-ref/ uart5_de_pc8: uart5_de_pc8 {
    pinmux = <((((('C') - 'A') & 0xFU) << 9U) | (((8) & 0xFU) << 5U) | (((0x7) & 0x1FU) << 0U))>;
    drive-push-pull;
   };
   /omit-if-no-ref/ usart6_de_pg8: usart6_de_pg8 {
    pinmux = <((((('G') - 'A') & 0xFU) << 9U) | (((8) & 0xFU) << 5U) | (((0x8) & 0x1FU) << 0U))>;
    drive-push-pull;
   };
   /omit-if-no-ref/ usart6_de_pg12: usart6_de_pg12 {
    pinmux = <((((('G') - 'A') & 0xFU) << 9U) | (((12) & 0xFU) << 5U) | (((0x8) & 0x1FU) << 0U))>;
    drive-push-pull;
   };
   /omit-if-no-ref/ uart7_de_pe9: uart7_de_pe9 {
    pinmux = <((((('E') - 'A') & 0xFU) << 9U) | (((9) & 0xFU) << 5U) | (((0x8) & 0x1FU) << 0U))>;
    drive-push-pull;
   };
   /omit-if-no-ref/ uart7_de_pf8: uart7_de_pf8 {
    pinmux = <((((('F') - 'A') & 0xFU) << 9U) | (((8) & 0xFU) << 5U) | (((0x8) & 0x1FU) << 0U))>;
    drive-push-pull;
   };
   /omit-if-no-ref/ uart8_de_pd15: uart8_de_pd15 {
    pinmux = <((((('D') - 'A') & 0xFU) << 9U) | (((15) & 0xFU) << 5U) | (((0x8) & 0x1FU) << 0U))>;
    drive-push-pull;
   };
   /omit-if-no-ref/ usart1_rts_pa12: usart1_rts_pa12 {
    pinmux = <((((('A') - 'A') & 0xFU) << 9U) | (((12) & 0xFU) << 5U) | (((0x7) & 0x1FU) << 0U))>;
    bias-pull-up;
    drive-open-drain;
   };
   /omit-if-no-ref/ usart2_rts_pa1: usart2_rts_pa1 {
    pinmux = <((((('A') - 'A') & 0xFU) << 9U) | (((1) & 0xFU) << 5U) | (((0x7) & 0x1FU) << 0U))>;
    bias-pull-up;
    drive-open-drain;
   };
   /omit-if-no-ref/ usart2_rts_pd4: usart2_rts_pd4 {
    pinmux = <((((('D') - 'A') & 0xFU) << 9U) | (((4) & 0xFU) << 5U) | (((0x7) & 0x1FU) << 0U))>;
    bias-pull-up;
    drive-open-drain;
   };
   /omit-if-no-ref/ usart3_rts_pb14: usart3_rts_pb14 {
    pinmux = <((((('B') - 'A') & 0xFU) << 9U) | (((14) & 0xFU) << 5U) | (((0x7) & 0x1FU) << 0U))>;
    bias-pull-up;
    drive-open-drain;
   };
   /omit-if-no-ref/ usart3_rts_pd12: usart3_rts_pd12 {
    pinmux = <((((('D') - 'A') & 0xFU) << 9U) | (((12) & 0xFU) << 5U) | (((0x7) & 0x1FU) << 0U))>;
    bias-pull-up;
    drive-open-drain;
   };
   /omit-if-no-ref/ uart4_rts_pa15: uart4_rts_pa15 {
    pinmux = <((((('A') - 'A') & 0xFU) << 9U) | (((15) & 0xFU) << 5U) | (((0x8) & 0x1FU) << 0U))>;
    bias-pull-up;
    drive-open-drain;
   };
   /omit-if-no-ref/ uart4_rts_pb14: uart4_rts_pb14 {
    pinmux = <((((('B') - 'A') & 0xFU) << 9U) | (((14) & 0xFU) << 5U) | (((0x8) & 0x1FU) << 0U))>;
    bias-pull-up;
    drive-open-drain;
   };
   /omit-if-no-ref/ uart5_rts_pc8: uart5_rts_pc8 {
    pinmux = <((((('C') - 'A') & 0xFU) << 9U) | (((8) & 0xFU) << 5U) | (((0x7) & 0x1FU) << 0U))>;
    bias-pull-up;
    drive-open-drain;
   };
   /omit-if-no-ref/ usart6_rts_pg8: usart6_rts_pg8 {
    pinmux = <((((('G') - 'A') & 0xFU) << 9U) | (((8) & 0xFU) << 5U) | (((0x8) & 0x1FU) << 0U))>;
    bias-pull-up;
    drive-open-drain;
   };
   /omit-if-no-ref/ usart6_rts_pg12: usart6_rts_pg12 {
    pinmux = <((((('G') - 'A') & 0xFU) << 9U) | (((12) & 0xFU) << 5U) | (((0x8) & 0x1FU) << 0U))>;
    bias-pull-up;
    drive-open-drain;
   };
   /omit-if-no-ref/ uart7_rts_pe9: uart7_rts_pe9 {
    pinmux = <((((('E') - 'A') & 0xFU) << 9U) | (((9) & 0xFU) << 5U) | (((0x8) & 0x1FU) << 0U))>;
    bias-pull-up;
    drive-open-drain;
   };
   /omit-if-no-ref/ uart7_rts_pf8: uart7_rts_pf8 {
    pinmux = <((((('F') - 'A') & 0xFU) << 9U) | (((8) & 0xFU) << 5U) | (((0x8) & 0x1FU) << 0U))>;
    bias-pull-up;
    drive-open-drain;
   };
   /omit-if-no-ref/ uart8_rts_pd15: uart8_rts_pd15 {
    pinmux = <((((('D') - 'A') & 0xFU) << 9U) | (((15) & 0xFU) << 5U) | (((0x8) & 0x1FU) << 0U))>;
    bias-pull-up;
    drive-open-drain;
   };
   /omit-if-no-ref/ usart1_rx_pa10: usart1_rx_pa10 {
    pinmux = <((((('A') - 'A') & 0xFU) << 9U) | (((10) & 0xFU) << 5U) | (((0x7) & 0x1FU) << 0U))>;
   };
   /omit-if-no-ref/ usart1_rx_pb7: usart1_rx_pb7 {
    pinmux = <((((('B') - 'A') & 0xFU) << 9U) | (((7) & 0xFU) << 5U) | (((0x7) & 0x1FU) << 0U))>;
   };
   /omit-if-no-ref/ usart1_rx_pb15: usart1_rx_pb15 {
    pinmux = <((((('B') - 'A') & 0xFU) << 9U) | (((15) & 0xFU) << 5U) | (((0x4) & 0x1FU) << 0U))>;
   };
   /omit-if-no-ref/ usart2_rx_pa3: usart2_rx_pa3 {
    pinmux = <((((('A') - 'A') & 0xFU) << 9U) | (((3) & 0xFU) << 5U) | (((0x7) & 0x1FU) << 0U))>;
   };
   /omit-if-no-ref/ usart2_rx_pd6: usart2_rx_pd6 {
    pinmux = <((((('D') - 'A') & 0xFU) << 9U) | (((6) & 0xFU) << 5U) | (((0x7) & 0x1FU) << 0U))>;
   };
   /omit-if-no-ref/ usart3_rx_pb11: usart3_rx_pb11 {
    pinmux = <((((('B') - 'A') & 0xFU) << 9U) | (((11) & 0xFU) << 5U) | (((0x7) & 0x1FU) << 0U))>;
   };
   /omit-if-no-ref/ usart3_rx_pc11: usart3_rx_pc11 {
    pinmux = <((((('C') - 'A') & 0xFU) << 9U) | (((11) & 0xFU) << 5U) | (((0x7) & 0x1FU) << 0U))>;
   };
   /omit-if-no-ref/ usart3_rx_pd9: usart3_rx_pd9 {
    pinmux = <((((('D') - 'A') & 0xFU) << 9U) | (((9) & 0xFU) << 5U) | (((0x7) & 0x1FU) << 0U))>;
   };
   /omit-if-no-ref/ uart4_rx_pa1: uart4_rx_pa1 {
    pinmux = <((((('A') - 'A') & 0xFU) << 9U) | (((1) & 0xFU) << 5U) | (((0x8) & 0x1FU) << 0U))>;
   };
   /omit-if-no-ref/ uart4_rx_pa11: uart4_rx_pa11 {
    pinmux = <((((('A') - 'A') & 0xFU) << 9U) | (((11) & 0xFU) << 5U) | (((0x6) & 0x1FU) << 0U))>;
   };
   /omit-if-no-ref/ uart4_rx_pc11: uart4_rx_pc11 {
    pinmux = <((((('C') - 'A') & 0xFU) << 9U) | (((11) & 0xFU) << 5U) | (((0x8) & 0x1FU) << 0U))>;
   };
   /omit-if-no-ref/ uart4_rx_pd0: uart4_rx_pd0 {
    pinmux = <((((('D') - 'A') & 0xFU) << 9U) | (((0) & 0xFU) << 5U) | (((0x8) & 0x1FU) << 0U))>;
   };
   /omit-if-no-ref/ uart5_rx_pb5: uart5_rx_pb5 {
    pinmux = <((((('B') - 'A') & 0xFU) << 9U) | (((5) & 0xFU) << 5U) | (((0x1) & 0x1FU) << 0U))>;
   };
   /omit-if-no-ref/ uart5_rx_pb8: uart5_rx_pb8 {
    pinmux = <((((('B') - 'A') & 0xFU) << 9U) | (((8) & 0xFU) << 5U) | (((0x7) & 0x1FU) << 0U))>;
   };
   /omit-if-no-ref/ uart5_rx_pb12: uart5_rx_pb12 {
    pinmux = <((((('B') - 'A') & 0xFU) << 9U) | (((12) & 0xFU) << 5U) | (((0x8) & 0x1FU) << 0U))>;
   };
   /omit-if-no-ref/ uart5_rx_pd2: uart5_rx_pd2 {
    pinmux = <((((('D') - 'A') & 0xFU) << 9U) | (((2) & 0xFU) << 5U) | (((0x8) & 0x1FU) << 0U))>;
   };
   /omit-if-no-ref/ usart6_rx_pc7: usart6_rx_pc7 {
    pinmux = <((((('C') - 'A') & 0xFU) << 9U) | (((7) & 0xFU) << 5U) | (((0x8) & 0x1FU) << 0U))>;
   };
   /omit-if-no-ref/ usart6_rx_pg9: usart6_rx_pg9 {
    pinmux = <((((('G') - 'A') & 0xFU) << 9U) | (((9) & 0xFU) << 5U) | (((0x8) & 0x1FU) << 0U))>;
   };
   /omit-if-no-ref/ uart7_rx_pa8: uart7_rx_pa8 {
    pinmux = <((((('A') - 'A') & 0xFU) << 9U) | (((8) & 0xFU) << 5U) | (((0xc) & 0x1FU) << 0U))>;
   };
   /omit-if-no-ref/ uart7_rx_pb3: uart7_rx_pb3 {
    pinmux = <((((('B') - 'A') & 0xFU) << 9U) | (((3) & 0xFU) << 5U) | (((0xc) & 0x1FU) << 0U))>;
   };
   /omit-if-no-ref/ uart7_rx_pe7: uart7_rx_pe7 {
    pinmux = <((((('E') - 'A') & 0xFU) << 9U) | (((7) & 0xFU) << 5U) | (((0x8) & 0x1FU) << 0U))>;
   };
   /omit-if-no-ref/ uart7_rx_pf6: uart7_rx_pf6 {
    pinmux = <((((('F') - 'A') & 0xFU) << 9U) | (((6) & 0xFU) << 5U) | (((0x8) & 0x1FU) << 0U))>;
   };
   /omit-if-no-ref/ uart8_rx_pe0: uart8_rx_pe0 {
    pinmux = <((((('E') - 'A') & 0xFU) << 9U) | (((0) & 0xFU) << 5U) | (((0x8) & 0x1FU) << 0U))>;
   };
   /omit-if-no-ref/ usart1_tx_pa9: usart1_tx_pa9 {
    pinmux = <((((('A') - 'A') & 0xFU) << 9U) | (((9) & 0xFU) << 5U) | (((0x7) & 0x1FU) << 0U))>;
    bias-pull-up;
   };
   /omit-if-no-ref/ usart1_tx_pb6: usart1_tx_pb6 {
    pinmux = <((((('B') - 'A') & 0xFU) << 9U) | (((6) & 0xFU) << 5U) | (((0x7) & 0x1FU) << 0U))>;
    bias-pull-up;
   };
   /omit-if-no-ref/ usart1_tx_pb14: usart1_tx_pb14 {
    pinmux = <((((('B') - 'A') & 0xFU) << 9U) | (((14) & 0xFU) << 5U) | (((0x4) & 0x1FU) << 0U))>;
    bias-pull-up;
   };
   /omit-if-no-ref/ usart2_tx_pa2: usart2_tx_pa2 {
    pinmux = <((((('A') - 'A') & 0xFU) << 9U) | (((2) & 0xFU) << 5U) | (((0x7) & 0x1FU) << 0U))>;
    bias-pull-up;
   };
   /omit-if-no-ref/ usart2_tx_pd5: usart2_tx_pd5 {
    pinmux = <((((('D') - 'A') & 0xFU) << 9U) | (((5) & 0xFU) << 5U) | (((0x7) & 0x1FU) << 0U))>;
    bias-pull-up;
   };
   /omit-if-no-ref/ usart3_tx_pb10: usart3_tx_pb10 {
    pinmux = <((((('B') - 'A') & 0xFU) << 9U) | (((10) & 0xFU) << 5U) | (((0x7) & 0x1FU) << 0U))>;
    bias-pull-up;
   };
   /omit-if-no-ref/ usart3_tx_pc10: usart3_tx_pc10 {
    pinmux = <((((('C') - 'A') & 0xFU) << 9U) | (((10) & 0xFU) << 5U) | (((0x7) & 0x1FU) << 0U))>;
    bias-pull-up;
   };
   /omit-if-no-ref/ usart3_tx_pd8: usart3_tx_pd8 {
    pinmux = <((((('D') - 'A') & 0xFU) << 9U) | (((8) & 0xFU) << 5U) | (((0x7) & 0x1FU) << 0U))>;
    bias-pull-up;
   };
   /omit-if-no-ref/ uart4_tx_pa0: uart4_tx_pa0 {
    pinmux = <((((('A') - 'A') & 0xFU) << 9U) | (((0) & 0xFU) << 5U) | (((0x8) & 0x1FU) << 0U))>;
    bias-pull-up;
   };
   /omit-if-no-ref/ uart4_tx_pa12: uart4_tx_pa12 {
    pinmux = <((((('A') - 'A') & 0xFU) << 9U) | (((12) & 0xFU) << 5U) | (((0x6) & 0x1FU) << 0U))>;
    bias-pull-up;
   };
   /omit-if-no-ref/ uart4_tx_pc10: uart4_tx_pc10 {
    pinmux = <((((('C') - 'A') & 0xFU) << 9U) | (((10) & 0xFU) << 5U) | (((0x8) & 0x1FU) << 0U))>;
    bias-pull-up;
   };
   /omit-if-no-ref/ uart4_tx_pd1: uart4_tx_pd1 {
    pinmux = <((((('D') - 'A') & 0xFU) << 9U) | (((1) & 0xFU) << 5U) | (((0x8) & 0x1FU) << 0U))>;
    bias-pull-up;
   };
   /omit-if-no-ref/ uart5_tx_pb6: uart5_tx_pb6 {
    pinmux = <((((('B') - 'A') & 0xFU) << 9U) | (((6) & 0xFU) << 5U) | (((0x1) & 0x1FU) << 0U))>;
    bias-pull-up;
   };
   /omit-if-no-ref/ uart5_tx_pb9: uart5_tx_pb9 {
    pinmux = <((((('B') - 'A') & 0xFU) << 9U) | (((9) & 0xFU) << 5U) | (((0x7) & 0x1FU) << 0U))>;
    bias-pull-up;
   };
   /omit-if-no-ref/ uart5_tx_pb13: uart5_tx_pb13 {
    pinmux = <((((('B') - 'A') & 0xFU) << 9U) | (((13) & 0xFU) << 5U) | (((0x8) & 0x1FU) << 0U))>;
    bias-pull-up;
   };
   /omit-if-no-ref/ uart5_tx_pc12: uart5_tx_pc12 {
    pinmux = <((((('C') - 'A') & 0xFU) << 9U) | (((12) & 0xFU) << 5U) | (((0x8) & 0x1FU) << 0U))>;
    bias-pull-up;
   };
   /omit-if-no-ref/ usart6_tx_pc6: usart6_tx_pc6 {
    pinmux = <((((('C') - 'A') & 0xFU) << 9U) | (((6) & 0xFU) << 5U) | (((0x8) & 0x1FU) << 0U))>;
    bias-pull-up;
   };
   /omit-if-no-ref/ usart6_tx_pg14: usart6_tx_pg14 {
    pinmux = <((((('G') - 'A') & 0xFU) << 9U) | (((14) & 0xFU) << 5U) | (((0x8) & 0x1FU) << 0U))>;
    bias-pull-up;
   };
   /omit-if-no-ref/ uart7_tx_pa15: uart7_tx_pa15 {
    pinmux = <((((('A') - 'A') & 0xFU) << 9U) | (((15) & 0xFU) << 5U) | (((0xc) & 0x1FU) << 0U))>;
    bias-pull-up;
   };
   /omit-if-no-ref/ uart7_tx_pb4: uart7_tx_pb4 {
    pinmux = <((((('B') - 'A') & 0xFU) << 9U) | (((4) & 0xFU) << 5U) | (((0xc) & 0x1FU) << 0U))>;
    bias-pull-up;
   };
   /omit-if-no-ref/ uart7_tx_pe8: uart7_tx_pe8 {
    pinmux = <((((('E') - 'A') & 0xFU) << 9U) | (((8) & 0xFU) << 5U) | (((0x8) & 0x1FU) << 0U))>;
    bias-pull-up;
   };
   /omit-if-no-ref/ uart7_tx_pf7: uart7_tx_pf7 {
    pinmux = <((((('F') - 'A') & 0xFU) << 9U) | (((7) & 0xFU) << 5U) | (((0x8) & 0x1FU) << 0U))>;
    bias-pull-up;
   };
   /omit-if-no-ref/ uart8_tx_pe1: uart8_tx_pe1 {
    pinmux = <((((('E') - 'A') & 0xFU) << 9U) | (((1) & 0xFU) << 5U) | (((0x8) & 0x1FU) << 0U))>;
    bias-pull-up;
   };
   /omit-if-no-ref/ usb_otg_fs_sof_pa8: usb_otg_fs_sof_pa8 {
    pinmux = <((((('A') - 'A') & 0xFU) << 9U) | (((8) & 0xFU) << 5U) | (((0xa) & 0x1FU) << 0U))>;
   };
   /omit-if-no-ref/ usb_otg_fs_vbus_pa9: usb_otg_fs_vbus_pa9 {
    pinmux = <((((('A') - 'A') & 0xFU) << 9U) | (((9) & 0xFU) << 5U) | (((0x10) & 0x1FU) << 0U))>;
   };
   /omit-if-no-ref/ usb_otg_fs_id_pa10: usb_otg_fs_id_pa10 {
    pinmux = <((((('A') - 'A') & 0xFU) << 9U) | (((10) & 0xFU) << 5U) | (((0xa) & 0x1FU) << 0U))>;
   };
   /omit-if-no-ref/ usb_otg_fs_dm_pa11: usb_otg_fs_dm_pa11 {
    pinmux = <((((('A') - 'A') & 0xFU) << 9U) | (((11) & 0xFU) << 5U) | (((0xa) & 0x1FU) << 0U))>;
   };
   /omit-if-no-ref/ usb_otg_fs_dp_pa12: usb_otg_fs_dp_pa12 {
    pinmux = <((((('A') - 'A') & 0xFU) << 9U) | (((12) & 0xFU) << 5U) | (((0xa) & 0x1FU) << 0U))>;
   };
   /omit-if-no-ref/ usb_otg_hs_sof_pa4: usb_otg_hs_sof_pa4 {
    pinmux = <((((('A') - 'A') & 0xFU) << 9U) | (((4) & 0xFU) << 5U) | (((0xc) & 0x1FU) << 0U))>;
   };
   /omit-if-no-ref/ usb_otg_hs_id_pb12: usb_otg_hs_id_pb12 {
    pinmux = <((((('B') - 'A') & 0xFU) << 9U) | (((12) & 0xFU) << 5U) | (((0xc) & 0x1FU) << 0U))>;
   };
   /omit-if-no-ref/ usb_otg_hs_vbus_pb13: usb_otg_hs_vbus_pb13 {
    pinmux = <((((('B') - 'A') & 0xFU) << 9U) | (((13) & 0xFU) << 5U) | (((0x10) & 0x1FU) << 0U))>;
   };
   /omit-if-no-ref/ usb_otg_hs_dm_pb14: usb_otg_hs_dm_pb14 {
    pinmux = <((((('B') - 'A') & 0xFU) << 9U) | (((14) & 0xFU) << 5U) | (((0xc) & 0x1FU) << 0U))>;
   };
   /omit-if-no-ref/ usb_otg_hs_dp_pb15: usb_otg_hs_dp_pb15 {
    pinmux = <((((('B') - 'A') & 0xFU) << 9U) | (((15) & 0xFU) << 5U) | (((0xc) & 0x1FU) << 0U))>;
   };
   /omit-if-no-ref/ usb_otg_hs_ulpi_d0_pa3: usb_otg_hs_ulpi_d0_pa3 {
    pinmux = <((((('A') - 'A') & 0xFU) << 9U) | (((3) & 0xFU) << 5U) | (((0xa) & 0x1FU) << 0U))>;
    slew-rate = "high-speed";
   };
   /omit-if-no-ref/ usb_otg_hs_ulpi_ck_pa5: usb_otg_hs_ulpi_ck_pa5 {
    pinmux = <((((('A') - 'A') & 0xFU) << 9U) | (((5) & 0xFU) << 5U) | (((0xa) & 0x1FU) << 0U))>;
    slew-rate = "high-speed";
   };
   /omit-if-no-ref/ usb_otg_hs_ulpi_d1_pb0: usb_otg_hs_ulpi_d1_pb0 {
    pinmux = <((((('B') - 'A') & 0xFU) << 9U) | (((0) & 0xFU) << 5U) | (((0xa) & 0x1FU) << 0U))>;
    slew-rate = "high-speed";
   };
   /omit-if-no-ref/ usb_otg_hs_ulpi_d2_pb1: usb_otg_hs_ulpi_d2_pb1 {
    pinmux = <((((('B') - 'A') & 0xFU) << 9U) | (((1) & 0xFU) << 5U) | (((0xa) & 0x1FU) << 0U))>;
    slew-rate = "high-speed";
   };
   /omit-if-no-ref/ usb_otg_hs_ulpi_d7_pb5: usb_otg_hs_ulpi_d7_pb5 {
    pinmux = <((((('B') - 'A') & 0xFU) << 9U) | (((5) & 0xFU) << 5U) | (((0xa) & 0x1FU) << 0U))>;
    slew-rate = "high-speed";
   };
   /omit-if-no-ref/ usb_otg_hs_ulpi_d3_pb10: usb_otg_hs_ulpi_d3_pb10 {
    pinmux = <((((('B') - 'A') & 0xFU) << 9U) | (((10) & 0xFU) << 5U) | (((0xa) & 0x1FU) << 0U))>;
    slew-rate = "high-speed";
   };
   /omit-if-no-ref/ usb_otg_hs_ulpi_d4_pb11: usb_otg_hs_ulpi_d4_pb11 {
    pinmux = <((((('B') - 'A') & 0xFU) << 9U) | (((11) & 0xFU) << 5U) | (((0xa) & 0x1FU) << 0U))>;
    slew-rate = "high-speed";
   };
   /omit-if-no-ref/ usb_otg_hs_ulpi_d5_pb12: usb_otg_hs_ulpi_d5_pb12 {
    pinmux = <((((('B') - 'A') & 0xFU) << 9U) | (((12) & 0xFU) << 5U) | (((0xa) & 0x1FU) << 0U))>;
    slew-rate = "high-speed";
   };
   /omit-if-no-ref/ usb_otg_hs_ulpi_d6_pb13: usb_otg_hs_ulpi_d6_pb13 {
    pinmux = <((((('B') - 'A') & 0xFU) << 9U) | (((13) & 0xFU) << 5U) | (((0xa) & 0x1FU) << 0U))>;
    slew-rate = "high-speed";
   };
   /omit-if-no-ref/ usb_otg_hs_ulpi_stp_pc0: usb_otg_hs_ulpi_stp_pc0 {
    pinmux = <((((('C') - 'A') & 0xFU) << 9U) | (((0) & 0xFU) << 5U) | (((0xa) & 0x1FU) << 0U))>;
    slew-rate = "high-speed";
   };
   /omit-if-no-ref/ usb_otg_hs_ulpi_dir_pc2: usb_otg_hs_ulpi_dir_pc2 {
    pinmux = <((((('C') - 'A') & 0xFU) << 9U) | (((2) & 0xFU) << 5U) | (((0xa) & 0x1FU) << 0U))>;
    slew-rate = "high-speed";
   };
   /omit-if-no-ref/ usb_otg_hs_ulpi_nxt_pc3: usb_otg_hs_ulpi_nxt_pc3 {
    pinmux = <((((('C') - 'A') & 0xFU) << 9U) | (((3) & 0xFU) << 5U) | (((0xa) & 0x1FU) << 0U))>;
    slew-rate = "high-speed";
   };
  };
 };
};
/ {
 arduino_header: connector {
  compatible = "arduino-header-r3";
  #gpio-cells = <2>;
  gpio-map-mask = <0xffffffff 0xffffffc0>;
  gpio-map-pass-thru = <0 0x3f>;
  gpio-map = <0 0 &gpioa 3 0>,
      <1 0 &gpioc 0 0>,
      <2 0 &gpioc 3 0>,
      <3 0 &gpiof 3 0>,
      <4 0 &gpiof 5 0>,
      <5 0 &gpiof 10 0>,
      <6 0 &gpiog 9 0>,
      <7 0 &gpiog 14 0>,
      <8 0 &gpiof 15 0>,
      <9 0 &gpioe 13 0>,
      <10 0 &gpiof 14 0>,
      <11 0 &gpioe 11 0>,
      <12 0 &gpioe 9 0>,
      <13 0 &gpiof 13 0>,
      <14 0 &gpiof 12 0>,
      <15 0 &gpiod 15 0>,
      <16 0 &gpiod 14 0>,
      <17 0 &gpioa 7 0>,
      <18 0 &gpioa 6 0>,
      <19 0 &gpioa 5 0>,
      <20 0 &gpiob 9 0>,
      <21 0 &gpiob 8 0>;
 };
};
arduino_serial: &usart6 {};
arduino_i2c: &i2c1 {};
arduino_spi: &spi1 {};
/ {
 model = "STMicroelectronics STM32F767ZI-NUCLEO board";
 compatible = "st,stm32f767zi-nucleo";
 chosen {
  zephyr,console = &usart3;
  zephyr,shell-uart = &usart3;
  zephyr,sram = &sram0;
  zephyr,flash = &flash0;
  zephyr,code-partition = &slot0_partition;
  zephyr,dtcm = &dtcm;
  zephyr,canbus = &can1;
 };
 leds: leds {
  compatible = "gpio-leds";
  green_led: led_0 {
   gpios = <&gpiob 0 (0 << 0)>;
   label = "User LD1";
  };
  blue_led: led_1 {
   gpios = <&gpiob 7 (0 << 0)>;
   label = "User LD2";
  };
  red_led: led_2 {
   gpios = <&gpiob 14 (0 << 0)>;
   label = "User LD3";
  };
 };
 gpio_keys {
  compatible = "gpio-keys";
  user_button: button_0 {
   label = "User";
   gpios = <&gpioc 13 (1 << 0)>;
   zephyr,code = <11>;
  };
 };
 aliases {
  led0 = &green_led;
  led1 = &blue_led;
  led2 = &red_led;
  sw0 = &user_button;
  watchdog0 = &iwdg;
  volt-sensor0 = &vref;
  volt-sensor1 = &vbat;
 };
};
&clk_lsi {
 status = "okay";
};
&clk_hse {
 hse-bypass;
 clock-frequency = <((8) * 1000 * 1000)>;
 status = "okay";
};
&pll {
 div-m = <4>;
 mul-n = <216>;
 div-p = <2>;
 div-q = <9>;
 clocks = <&clk_hse>;
 status = "okay";
};
&rcc {
 clocks = <&pll>;
 clock-frequency = <((216) * 1000 * 1000)>;
 ahb-prescaler = <1>;
 apb1-prescaler = <4>;
 apb2-prescaler = <2>;
};
&usart2 {
 pinctrl-0 = <&usart2_tx_pd5
       &usart2_rx_pd6
       &usart2_rts_pd4
       &usart2_cts_pd3>;
 pinctrl-names = "default";
 current-speed = <115200>;
};
&usart3 {
 pinctrl-0 = <&usart3_tx_pd8 &usart3_rx_pd9>;
 pinctrl-names = "default";
 current-speed = <115200>;
 status = "okay";
};
&usart6 {
 pinctrl-0 = <&usart6_tx_pg14 &usart6_rx_pg9>;
 pinctrl-names = "default";
 current-speed = <115200>;
 status = "okay";
};
zephyr_udc0: &usbotg_fs {
 pinctrl-0 = <&usb_otg_fs_dm_pa11 &usb_otg_fs_dp_pa12>;
 pinctrl-names = "default";
 status = "okay";
};
&i2c1 {
 pinctrl-0 = <&i2c1_scl_pb8 &i2c1_sda_pb9>;
 pinctrl-names = "default";
 status = "okay";
 clock-frequency = <400000>;
};
&timers1 {
 st,prescaler = <10000>;
 status = "okay";
 pwm1: pwm {
  status = "okay";
  pinctrl-0 = <&tim1_ch3_pe13>;
  pinctrl-names = "default";
 };
};
&spi1 {
 pinctrl-0 = <&spi1_sck_pa5 &spi1_miso_pa6 &spi1_mosi_pa7>;
 pinctrl-names = "default";
 cs-gpios = <&gpiod 14 ((1 << 0) | (1 << 4))>;
 status = "okay";
};
&iwdg {
 status = "okay";
};
&rtc {
 clocks = <&rcc 0x040 0x10000000>,
   <&rcc 0x005 ((((0x70) & 0xFFU) << 0U) | (((8) & 0x1FU) << 8U) | (((3) & 0x7U) << 13U) | (((2) & 0x7U) << 16U))>;
 status = "okay";
};
&can1 {
 pinctrl-0 = <&can1_rx_pd0 &can1_tx_pd1>;
 pinctrl-names = "default";
 bus-speed = <125000>;
 status = "okay";
};
&adc1 {
 pinctrl-0 = <&adc1_in0_pa0>;
 pinctrl-names = "default";
 st,adc-clock-source = <1>;
 st,adc-prescaler = <2>;
 status = "okay";
};
&dac1 {
 status = "okay";
 pinctrl-0 = <&dac_out1_pa4>;
 pinctrl-names = "default";
};
&rng {
 status = "okay";
};
&mac {
 status = "okay";
 pinctrl-0 = <&eth_mdc_pc1
       &eth_rxd0_pc4
       &eth_rxd1_pc5
       &eth_ref_clk_pa1
       &eth_mdio_pa2
       &eth_crs_dv_pa7
       &eth_tx_en_pg11
       &eth_txd0_pg13
       &eth_txd1_pb13>;
 pinctrl-names = "default";
};
&flash0 {
 partitions {
  compatible = "fixed-partitions";
  #address-cells = <1>;
  #size-cells = <1>;
  boot_partition: partition@0 {
   label = "mcuboot";
   reg = <0x0 ((64) * 1024)>;
   read-only;
  };
  storage_partition: partition@10000 {
   label = "storage";
   reg = <0x00010000 ((64) * 1024)>;
  };
  slot0_partition: partition@40000 {
   label = "image-0";
   reg = <0x00040000 ((768) * 1024)>;
  };
  slot1_partition: partition@100000 {
   label = "image-1";
   reg = <0x00100000 ((768) * 1024)>;
  };
  scratch_partition: partition@1C0000 {
   label = "image-scratch";
   reg = <0x001C0000 ((256) * 1024)>;
  };
 };
};
&vref {
 status = "okay";
};
&vbat {
 status = "okay";
};
